VERSION ""

NS_ :

BS_:

BU_: PowertrainControlModule AtmosphericSensor SafetyRestraintSystem2 Aftertreatment_2_GasOutlet Aftertreatment_2_GasIntake DieselParticulateFilterControl Turbocharger SafetyRestraintSystem1 CabDisplay2 Aftertreatment_1_GasOutlet Aftertreatment_1_GasIntake OnBoardDataLogger OffBoardDiagnosticTool2 OffBoardDiagnosticTool1 FileServer ParkingBrakeController SeatController2 FanDriveController SteeringColumnUnit CommunicationUnitRadio CommunicationUnitSatellite CommunicationUnitCellular PropulsionBatteryCharger ChassisController2 ChassisController1 EngineValveControl AuxiliaryHeater2 AuxiliaryHeater1 ClutchUnit RampControl InformationSystem1 SuspensionSystemController2 OilSensor VehicleDynamicStability ExhaustEmissionController TransmissionDisplay2 TransmissionDisplay1 ClimateControl2 WaterPumpController RearAxleSteeringController LightingOperatorControl SeatController1 IgnitionController2 IgnitionController1 TirePressureController CabController2 CabController1 PneumaticSystemController SuspensionSystemController1 HydraulicPumpController EnduranceBrakingSystem RetarderExhaustEngine2 OnBoardDiagnosticUnit HeadwayController RetarderExhaustEngine1 CabDisplay1 ManagementComputer VirtualTerminal OffVehicleGateway PowerTakeOffFront HitchControl AuxiliaryValveControl BodyController TractorTrailerBridge1 StarterSystem ElectricalSystem VehicleSecurity VehicleNavigation AerodynamicControl ElectricalChargingSystem ClimateControl1 TripRecorder InstrumentCluster SuspensionDriveAxle2 SuspensionDriveAxle1 SuspensionSteerAxle SteeringController FuelSystem CruiseControl RetarderDriveline RetarderEngine BrakesDriveAxle2 BrakesDriveAxle1 BrakesSystemController BrakesSteerAxle AxleDrive2 AxleDrive1 AxleSteering PowerTakeOff ShiftConsoleSecondary ShiftConsolePrimary Transmission2 Transmission1 Engine2 Engine1

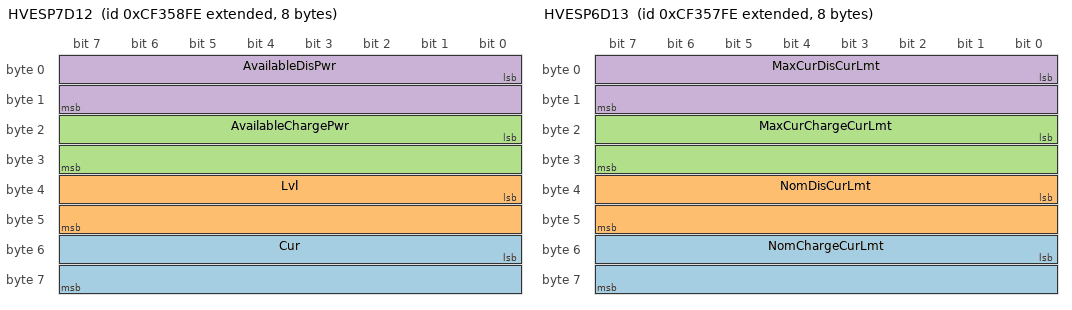
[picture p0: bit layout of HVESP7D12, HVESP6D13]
BO_ 2364758270 HVESP7D12: 8 Vector__XXX
 SG_ Cur : 48|16@1+ (0.125,-4000) [-4000|4031.875] "A" Vector__XXX
 SG_ Lvl : 32|16@1+ (0.125,0) [0|8031.875] "V" Vector__XXX
 SG_ AvailableChargePwr : 16|16@1+ (0.25,0) [0|16063.75] "kW" Vector__XXX
 SG_ AvailableDisPwr : 0|16@1+ (0.25,0) [0|16063.75] "kW" Vector__XXX

BO_ 2364758014 HVESP6D13: 8 Vector__XXX
 SG_ NomChargeCurLmt : 48|16@1+ (0.125,-4000) [0|4031.875] "A" Vector__XXX
 SG_ NomDisCurLmt : 32|16@1+ (0.125,-4000) [-4000|0] "A" Vector__XXX
 SG_ MaxCurChargeCurLmt : 16|16@1+ (0.125,-4000) [0|4031.875] "A" Vector__XXX
 SG_ MaxCurDisCurLmt : 0|16@1+ (0.125,-4000) [-4000|0] "A" Vector__XXX

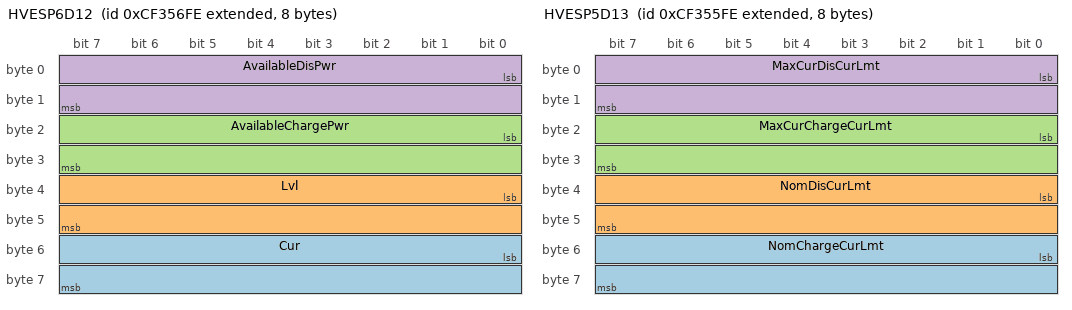
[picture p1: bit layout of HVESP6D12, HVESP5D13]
BO_ 2364757758 HVESP6D12: 8 Vector__XXX
 SG_ Cur : 48|16@1+ (0.125,-4000) [-4000|4031.875] "A" Vector__XXX
 SG_ Lvl : 32|16@1+ (0.125,0) [0|8031.875] "V" Vector__XXX
 SG_ AvailableChargePwr : 16|16@1+ (0.25,0) [0|16063.75] "kW" Vector__XXX
 SG_ AvailableDisPwr : 0|16@1+ (0.25,0) [0|16063.75] "kW" Vector__XXX

BO_ 2364757502 HVESP5D13: 8 Vector__XXX
 SG_ NomChargeCurLmt : 48|16@1+ (0.125,-4000) [0|4031.875] "A" Vector__XXX
 SG_ NomDisCurLmt : 32|16@1+ (0.125,-4000) [-4000|0] "A" Vector__XXX
 SG_ MaxCurChargeCurLmt : 16|16@1+ (0.125,-4000) [0|4031.875] "A" Vector__XXX
 SG_ MaxCurDisCurLmt : 0|16@1+ (0.125,-4000) [-4000|0] "A" Vector__XXX

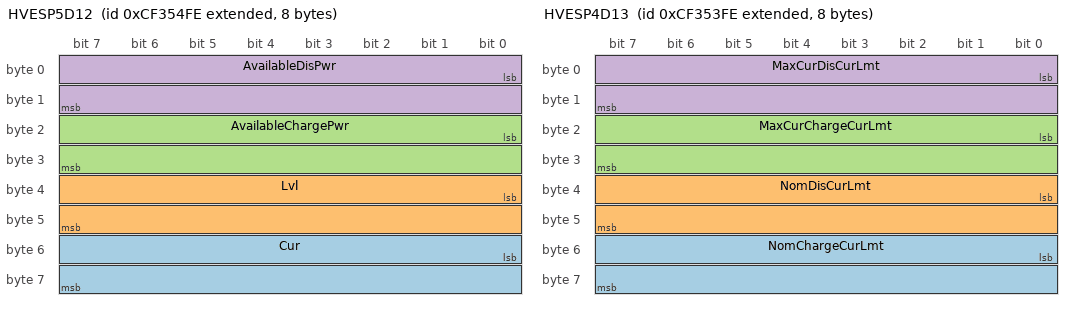
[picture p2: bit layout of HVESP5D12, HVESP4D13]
BO_ 2364757246 HVESP5D12: 8 Vector__XXX
 SG_ Cur : 48|16@1+ (0.125,-4000) [-4000|4031.875] "A" Vector__XXX
 SG_ Lvl : 32|16@1+ (0.125,0) [0|8031.875] "V" Vector__XXX
 SG_ AvailableChargePwr : 16|16@1+ (0.25,0) [0|16063.75] "kW" Vector__XXX
 SG_ AvailableDisPwr : 0|16@1+ (0.25,0) [0|16063.75] "kW" Vector__XXX

BO_ 2364756990 HVESP4D13: 8 Vector__XXX
 SG_ NomChargeCurLmt : 48|16@1+ (0.125,-4000) [0|4031.875] "A" Vector__XXX
 SG_ NomDisCurLmt : 32|16@1+ (0.125,-4000) [-4000|0] "A" Vector__XXX
 SG_ MaxCurChargeCurLmt : 16|16@1+ (0.125,-4000) [0|4031.875] "A" Vector__XXX
 SG_ MaxCurDisCurLmt : 0|16@1+ (0.125,-4000) [-4000|0] "A" Vector__XXX

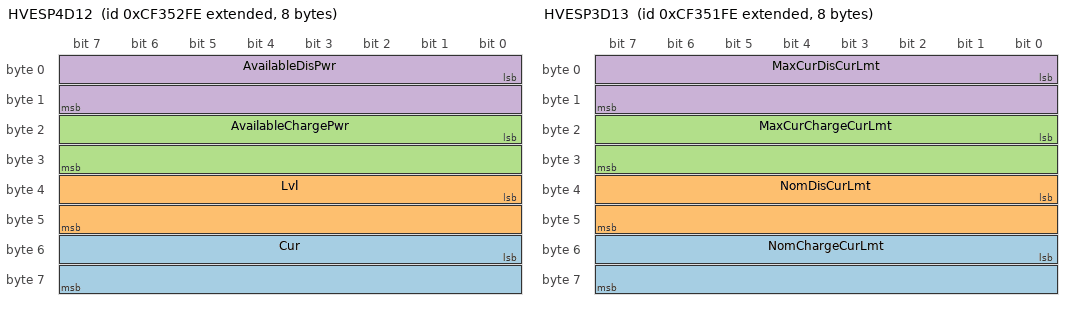
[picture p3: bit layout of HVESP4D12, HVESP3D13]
BO_ 2364756734 HVESP4D12: 8 Vector__XXX
 SG_ Cur : 48|16@1+ (0.125,-4000) [-4000|4031.875] "A" Vector__XXX
 SG_ Lvl : 32|16@1+ (0.125,0) [0|8031.875] "V" Vector__XXX
 SG_ AvailableChargePwr : 16|16@1+ (0.25,0) [0|16063.75] "kW" Vector__XXX
 SG_ AvailableDisPwr : 0|16@1+ (0.25,0) [0|16063.75] "kW" Vector__XXX

BO_ 2364756478 HVESP3D13: 8 Vector__XXX
 SG_ NomChargeCurLmt : 48|16@1+ (0.125,-4000) [0|4031.875] "A" Vector__XXX
 SG_ NomDisCurLmt : 32|16@1+ (0.125,-4000) [-4000|0] "A" Vector__XXX
 SG_ MaxCurChargeCurLmt : 16|16@1+ (0.125,-4000) [0|4031.875] "A" Vector__XXX
 SG_ MaxCurDisCurLmt : 0|16@1+ (0.125,-4000) [-4000|0] "A" Vector__XXX

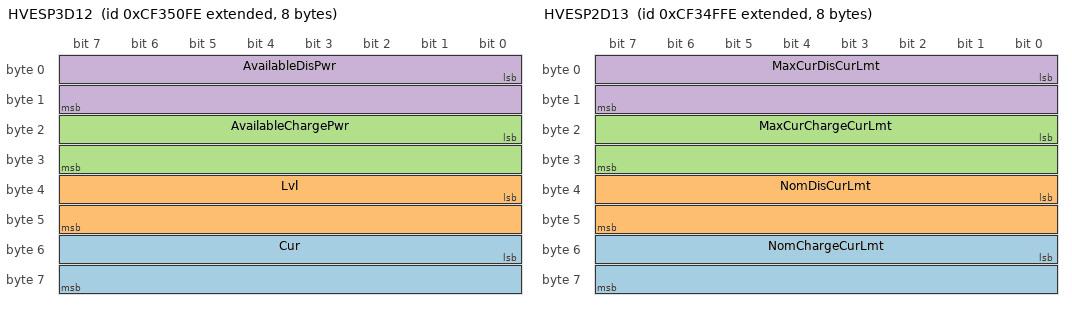
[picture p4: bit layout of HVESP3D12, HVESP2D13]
BO_ 2364756222 HVESP3D12: 8 Vector__XXX
 SG_ Cur : 48|16@1+ (0.125,-4000) [-4000|4031.875] "A" Vector__XXX
 SG_ Lvl : 32|16@1+ (0.125,0) [0|8031.875] "V" Vector__XXX
 SG_ AvailableChargePwr : 16|16@1+ (0.25,0) [0|16063.75] "kW" Vector__XXX
 SG_ AvailableDisPwr : 0|16@1+ (0.25,0) [0|16063.75] "kW" Vector__XXX

BO_ 2364755966 HVESP2D13: 8 Vector__XXX
 SG_ NomChargeCurLmt : 48|16@1+ (0.125,-4000) [0|4031.875] "A" Vector__XXX
 SG_ NomDisCurLmt : 32|16@1+ (0.125,-4000) [-4000|0] "A" Vector__XXX
 SG_ MaxCurChargeCurLmt : 16|16@1+ (0.125,-4000) [0|4031.875] "A" Vector__XXX
 SG_ MaxCurDisCurLmt : 0|16@1+ (0.125,-4000) [-4000|0] "A" Vector__XXX

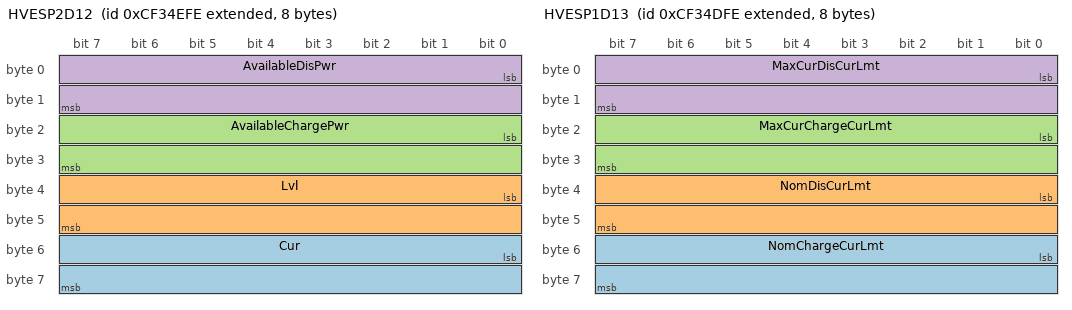
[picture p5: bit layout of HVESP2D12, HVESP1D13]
BO_ 2364755710 HVESP2D12: 8 Vector__XXX
 SG_ Cur : 48|16@1+ (0.125,-4000) [-4000|4031.875] "A" Vector__XXX
 SG_ Lvl : 32|16@1+ (0.125,0) [0|8031.875] "V" Vector__XXX
 SG_ AvailableChargePwr : 16|16@1+ (0.25,0) [0|16063.75] "kW" Vector__XXX
 SG_ AvailableDisPwr : 0|16@1+ (0.25,0) [0|16063.75] "kW" Vector__XXX

BO_ 2364755454 HVESP1D13: 8 Vector__XXX
 SG_ NomChargeCurLmt : 48|16@1+ (0.125,-4000) [0|4031.875] "A" Vector__XXX
 SG_ NomDisCurLmt : 32|16@1+ (0.125,-4000) [-4000|0] "A" Vector__XXX
 SG_ MaxCurChargeCurLmt : 16|16@1+ (0.125,-4000) [0|4031.875] "A" Vector__XXX
 SG_ MaxCurDisCurLmt : 0|16@1+ (0.125,-4000) [-4000|0] "A" Vector__XXX

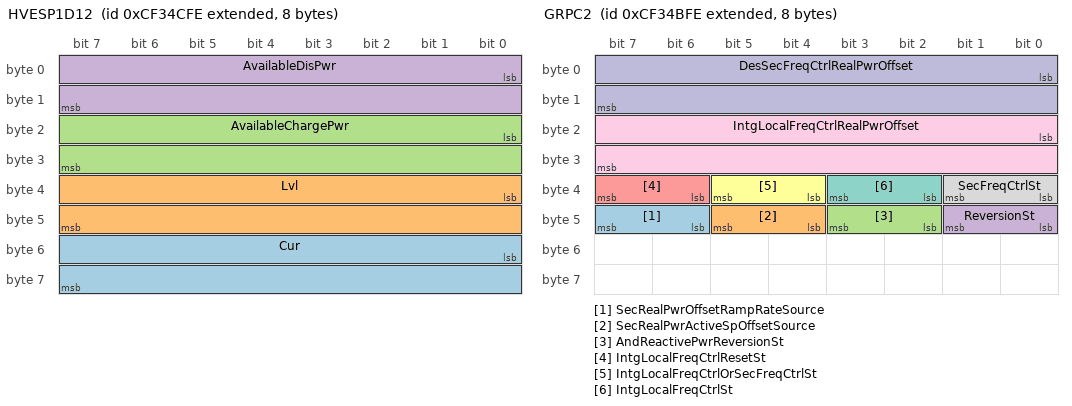
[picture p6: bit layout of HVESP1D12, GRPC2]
BO_ 2364755198 HVESP1D12: 8 Vector__XXX
 SG_ Cur : 48|16@1+ (0.125,-4000) [-4000|4031.875] "A" Vector__XXX
 SG_ Lvl : 32|16@1+ (0.125,0) [0|8031.875] "V" Vector__XXX
 SG_ AvailableChargePwr : 16|16@1+ (0.25,0) [0|16063.75] "kW" Vector__XXX
 SG_ AvailableDisPwr : 0|16@1+ (0.25,0) [0|16063.75] "kW" Vector__XXX

BO_ 2364754942 GRPC2: 8 Vector__XXX
 SG_ SecRealPwrOffsetRampRateSource : 46|2@1+ (1,0) [0|3] "" Vector__XXX
 SG_ SecRealPwrActiveSpOffsetSource : 44|2@1+ (1,0) [0|3] "" Vector__XXX
 SG_ AndReactivePwrReversionSt : 42|2@1+ (1,0) [0|3] "" Vector__XXX
 SG_ ReversionSt : 40|2@1+ (1,0) [0|3] "" Vector__XXX
 SG_ IntgLocalFreqCtrlResetSt : 38|2@1+ (1,0) [0|3] "" Vector__XXX
 SG_ IntgLocalFreqCtrlOrSecFreqCtrlSt : 36|2@1+ (1,0) [0|3] "" Vector__XXX
 SG_ IntgLocalFreqCtrlSt : 34|2@1+ (1,0) [0|3] "" Vector__XXX
 SG_ SecFreqCtrlSt : 32|2@1+ (1,0) [0|3] "" Vector__XXX
 SG_ IntgLocalFreqCtrlRealPwrOffset : 16|16@1+ (0.01,-321.27) [-321.27|321.28] "%" Vector__XXX
 SG_ DesSecFreqCtrlRealPwrOffset : 0|16@1+ (0.01,-321.27) [-321.27|321.28] "%" Vector__XXX

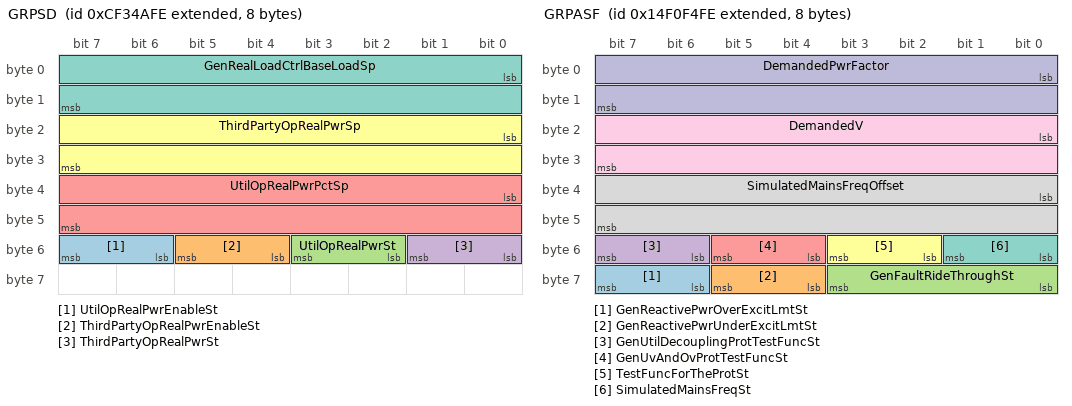
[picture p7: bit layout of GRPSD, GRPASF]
BO_ 2364754686 GRPSD: 8 Vector__XXX
 SG_ UtilOpRealPwrEnableSt : 54|2@1+ (1,0) [0|3] "" Vector__XXX
 SG_ ThirdPartyOpRealPwrEnableSt : 52|2@1+ (1,0) [0|3] "" Vector__XXX
 SG_ UtilOpRealPwrSt : 50|2@1+ (1,0) [0|3] "" Vector__XXX
 SG_ ThirdPartyOpRealPwrSt : 48|2@1+ (1,0) [0|3] "" Vector__XXX
 SG_ UtilOpRealPwrPctSp : 32|16@1+ (0.01,-321.27) [-321.27|321.28] "%" Vector__XXX
 SG_ ThirdPartyOpRealPwrSp : 16|16@1+ (0.01,-321.27) [-321.27|321.28] "%" Vector__XXX
 SG_ GenRealLoadCtrlBaseLoadSp : 0|16@1+ (0.01,-321.27) [-321.27|321.28] "%" Vector__XXX

BO_ 2498819326 GRPASF: 8 Vector__XXX
 SG_ GenReactivePwrOverExcitLmtSt : 62|2@1+ (1,0) [0|3] "" Vector__XXX
 SG_ GenReactivePwrUnderExcitLmtSt : 60|2@1+ (1,0) [0|3] "" Vector__XXX
 SG_ GenFaultRideThroughSt : 56|4@1+ (1,0) [0|15] "" Vector__XXX
 SG_ GenUtilDecouplingProtTestFuncSt : 54|2@1+ (1,0) [0|3] "" Vector__XXX
 SG_ GenUvAndOvProtTestFuncSt : 52|2@1+ (1,0) [0|3] "" Vector__XXX
 SG_ TestFuncForTheProtSt : 50|2@1+ (1,0) [0|3] "" Vector__XXX
 SG_ SimulatedMainsFreqSt : 48|2@1+ (1,0) [0|3] "" Vector__XXX
 SG_ SimulatedMainsFreqOffset : 32|16@1+ (0.0078125,0) [0|501.9921875] "Hz" Vector__XXX
 SG_ DemandedV : 16|16@1+ (0.01,-321.28) [-321.28|321.27] "V" Vector__XXX
 SG_ DemandedPwrFactor : 0|16@1+ (6.103515625E-005,-1) [-1|2.92181396484375] "" Vector__XXX

BO_ 2565918718 ETWAI2: 8 Vector__XXX
 SG_ FourOpSt : 4|4@1+ (1,0) [0|15] "" Vector__XXX
 SG_ ThreeOpSt : 0|4@1+ (1,0) [0|15] "" Vector__XXX

BO_ 2565918462 ETCC4: 8 Vector__XXX
 SG_ WastegateAct4Cmd : 16|16@1+ (0.0025,0) [0|160.6375] "%" Vector__XXX
 SG_ WastegateAct3Cmd : 0|16@1+ (0.0025,0) [0|160.6375] "%" Vector__XXX

BO_ 2565905662 MG6ITPS: 8 Vector__XXX
 SG_ CapLmt : 8|8@1+ (0.4,0) [0|100] "%" Vector__XXX
 SG_ CapUsed : 0|8@1+ (0.4,0) [0|100] "%" Vector__XXX

BO_ 2565905406 MG5ITPS: 8 Vector__XXX
 SG_ CapLmt : 8|8@1+ (0.4,0) [0|100] "%" Vector__XXX
 SG_ CapUsed : 0|8@1+ (0.4,0) [0|100] "%" Vector__XXX

BO_ 2565905150 MG4ITPS: 8 Vector__XXX
 SG_ CapLmt : 8|8@1+ (0.4,0) [0|100] "%" Vector__XXX
 SG_ CapUsed : 0|8@1+ (0.4,0) [0|100] "%" Vector__XXX

BO_ 2565904894 MG3ITPS: 8 Vector__XXX
 SG_ CapLmt : 8|8@1+ (0.4,0) [0|100] "%" Vector__XXX
 SG_ CapUsed : 0|8@1+ (0.4,0) [0|100] "%" Vector__XXX

BO_ 2565904638 MG2ITPS: 8 Vector__XXX
 SG_ CapLmt : 8|8@1+ (0.4,0) [0|100] "%" Vector__XXX
 SG_ CapUsed : 0|8@1+ (0.4,0) [0|100] "%" Vector__XXX

BO_ 2565904382 MG1ITPS: 8 Vector__XXX
 SG_ CapLmt : 8|8@1+ (0.4,0) [0|100] "%" Vector__XXX
 SG_ CapUsed : 0|8@1+ (0.4,0) [0|100] "%" Vector__XXX

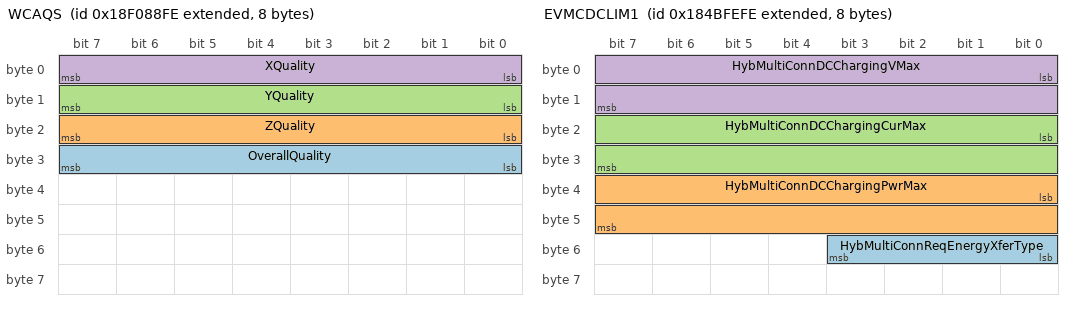
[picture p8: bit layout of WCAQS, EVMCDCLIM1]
BO_ 2565900542 WCAQS: 8 Vector__XXX
 SG_ OverallQuality : 24|8@1+ (0.4,0) [0|100] "%" Vector__XXX
 SG_ ZQuality : 16|8@1+ (0.8,-100) [-100|100] "%" Vector__XXX
 SG_ YQuality : 8|8@1+ (0.8,-100) [-100|100] "%" Vector__XXX
 SG_ XQuality : 0|8@1+ (0.8,-100) [-100|100] "%" Vector__XXX

BO_ 2555117310 EVMCDCLIM1: 8 Vector__XXX
 SG_ HybMultiConnReqEnergyXferType : 48|4@1+ (1,0) [0|15] "" Vector__XXX
 SG_ HybMultiConnDCChargingPwrMax : 32|16@1+ (0.05,0) [0|3212.75] "kW" Vector__XXX
 SG_ HybMultiConnDCChargingCurMax : 16|16@1+ (0.0625,0) [0|4015.9375] "A" Vector__XXX
 SG_ HybMultiConnDCChargingVMax : 0|16@1+ (0.05,0) [0|3212.75] "V" Vector__XXX

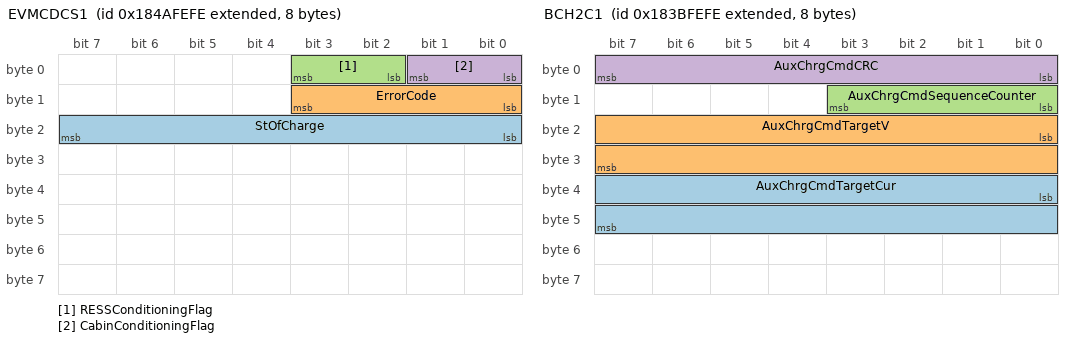
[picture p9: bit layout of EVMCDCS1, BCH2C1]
BO_ 2555051774 EVMCDCS1: 8 Vector__XXX
 SG_ StOfCharge : 16|8@1+ (0.5,0) [0|125] "%" Vector__XXX
 SG_ ErrorCode : 8|4@1+ (1,0) [0|15] "" Vector__XXX
 SG_ RESSConditioningFlag : 2|2@1+ (1,0) [0|3] "" Vector__XXX
 SG_ CabinConditioningFlag : 0|2@1+ (1,0) [0|3] "" Vector__XXX

BO_ 2554068734 BCH2C1: 8 Vector__XXX
 SG_ AuxChrgCmdTargetCur : 32|16@1+ (0.0625,0) [0|4015.9375] "A" Vector__XXX
 SG_ AuxChrgCmdTargetV : 16|16@1+ (0.05,0) [0|3212.75] "V" Vector__XXX
 SG_ AuxChrgCmdSequenceCounter : 8|4@1+ (1,0) [0|15] "" Vector__XXX
 SG_ AuxChrgCmdCRC : 0|8@1+ (1,0) [0|255] "" Vector__XXX

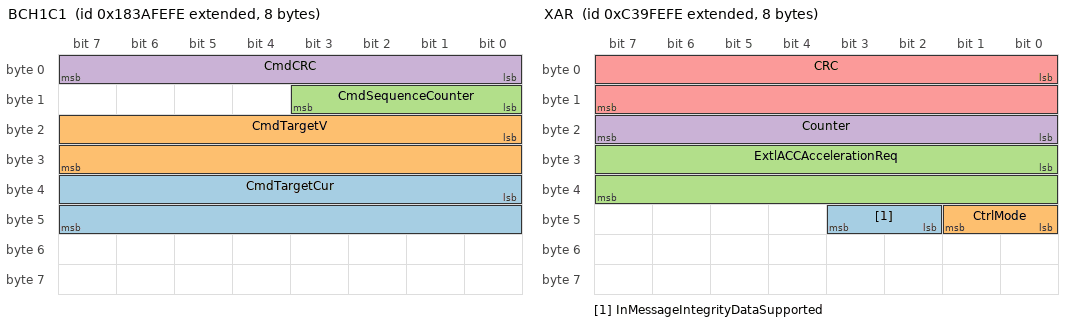
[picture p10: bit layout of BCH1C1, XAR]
BO_ 2554003198 BCH1C1: 8 Vector__XXX
 SG_ CmdTargetCur : 32|16@1+ (0.0625,0) [0|4015.9375] "A" Vector__XXX
 SG_ CmdTargetV : 16|16@1+ (0.05,0) [0|3212.75] "V" Vector__XXX
 SG_ CmdSequenceCounter : 8|4@1+ (1,0) [0|15] "" Vector__XXX
 SG_ CmdCRC : 0|8@1+ (1,0) [0|255] "" Vector__XXX

BO_ 2352611070 XAR: 8 Vector__XXX
 SG_ InMessageIntegrityDataSupported : 42|2@1+ (1,0) [0|3] "" Vector__XXX
 SG_ CtrlMode : 40|2@1+ (1,0) [0|3] "" Vector__XXX
 SG_ ExtlACCAccelerationReq : 24|16@1+ (0.00048828125,-15.6865234375) [-15.6865234375|15.68798828125] "m/s²" Vector__XXX
 SG_ Counter : 16|8@1+ (1,0) [0|255] "" Vector__XXX
 SG_ CRC : 0|16@1+ (1,0) [0|65535] "" Vector__XXX

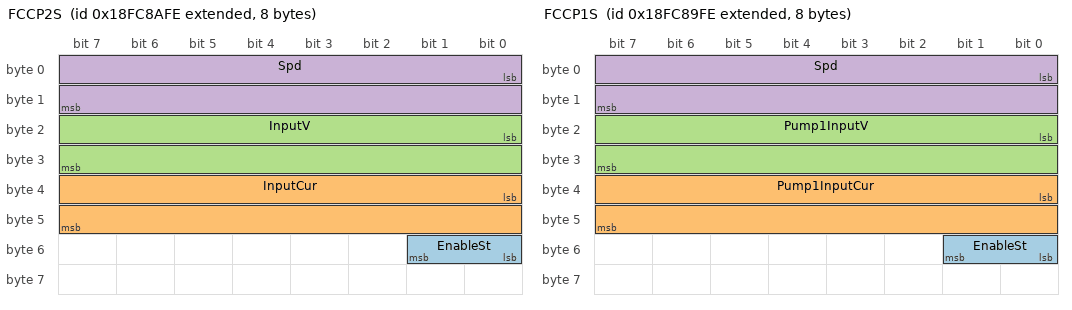
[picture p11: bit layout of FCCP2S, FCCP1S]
BO_ 2566687486 FCCP2S: 8 Vector__XXX
 SG_ EnableSt : 48|2@1+ (1,0) [0|3] "" Vector__XXX
 SG_ InputCur : 32|16@1+ (0.001,0) [0|64.255] "A" Vector__XXX
 SG_ InputV : 16|16@1+ (1,0) [0|64255] "V" Vector__XXX
 SG_ Spd : 0|16@1+ (0.5,0) [0|32127.5] "rpm" Vector__XXX

BO_ 2566687230 FCCP1S: 8 Vector__XXX
 SG_ EnableSt : 48|2@1+ (1,0) [0|3] "" Vector__XXX
 SG_ Pump1InputCur : 32|16@1+ (0.001,0) [0|64.255] "A" Vector__XXX
 SG_ Pump1InputV : 16|16@1+ (1,0) [0|64255] "V" Vector__XXX
 SG_ Spd : 0|16@1+ (0.5,0) [0|32127.5] "rpm" Vector__XXX

BO_ 2566686974 FCCP2C: 8 Vector__XXX
 SG_ EnableCmd : 24|2@1+ (1,0) [0|3] "" Vector__XXX
 SG_ PercentSpdCmd : 16|8@1+ (0.5,0) [0|125] "%" Vector__XXX
 SG_ SpdCmd : 0|16@1+ (0.5,0) [0|32127.5] "rpm" Vector__XXX

BO_ 2566686718 FCCP1C: 8 Vector__XXX
 SG_ EnableCmd : 24|2@1+ (1,0) [0|3] "" Vector__XXX
 SG_ PercentSpdCmd : 16|8@1+ (0.5,0) [0|125] "%" Vector__XXX
 SG_ SpdCmd : 0|16@1+ (0.5,0) [0|32127.5] "rpm" Vector__XXX

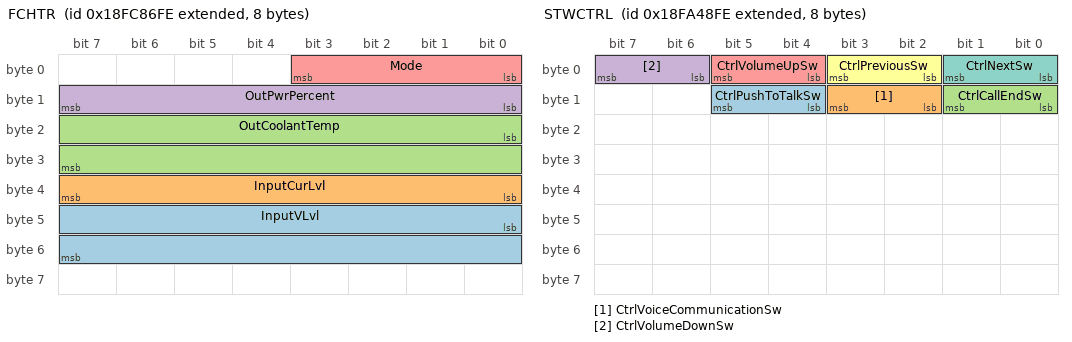
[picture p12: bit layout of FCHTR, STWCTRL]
BO_ 2566686462 FCHTR: 8 Vector__XXX
 SG_ InputVLvl : 40|16@1+ (1,0) [0|64255] "V" Vector__XXX
 SG_ InputCurLvl : 32|8@1+ (0.25,0) [0|62.5] "A" Vector__XXX
 SG_ OutCoolantTemp : 16|16@1+ (0.0078125,-273) [-273|228.9921875] "°C" Vector__XXX
 SG_ OutPwrPercent : 8|8@1+ (0.4,0) [0|100] "%" Vector__XXX
 SG_ Mode : 0|4@1+ (1,0) [0|15] "" Vector__XXX

BO_ 2566686206 FCHTRC: 8 Vector__XXX
 SG_ OutCoolantTempSp : 16|16@1+ (0.0078125,-273) [-273|228.9921875] "°C" Vector__XXX
 SG_ PwrPercentCmd : 8|8@1+ (0.4,0) [0|100] "%" Vector__XXX
 SG_ ModeReq : 0|4@1+ (1,0) [0|15] "" Vector__XXX

BO_ 2566675710 SSCTI: 8 Vector__XXX
 SG_ Component3Identifier : 8|8@1+ (1,0) [0|250] "ID" Vector__XXX
 SG_ SyncSvcDelay_CalendarTime : 0|8@1+ (1,-125) [-125|125] "week" Vector__XXX

BO_ 2566675454 SSOTI: 8 Vector__XXX
 SG_ Component2Identifier : 0|8@1+ (1,0) [0|250] "ID" Vector__XXX
 SG_ SyncSvcDelay_OperationalTime : 65528|16@1+ (1,-32127) [-32127|32128] "h" Vector__XXX

BO_ 2566675198 SSDI: 8 Vector__XXX
 SG_ Component1Identifier : 0|8@1+ (1,0) [0|250] "ID" Vector__XXX
 SG_ SyncSvcDist : 65528|16@1+ (5,-160635) [-160635|160640] "km" Vector__XXX

BO_ 2566539774 PA: 8 Vector__XXX
 SG_ RearParkAssistSt : 3|3@1+ (1,0) [0|7] "" Vector__XXX
 SG_ FrontParkAssistSt : 0|3@1+ (1,0) [0|7] "" Vector__XXX

BO_ 2566539518 STWCTRL: 8 Vector__XXX
 SG_ CtrlPushToTalkSw : 12|2@1+ (1,0) [0|3] "" Vector__XXX
 SG_ CtrlVoiceCommunicationSw : 10|2@1+ (1,0) [0|3] "" Vector__XXX
 SG_ CtrlCallEndSw : 8|2@1+ (1,0) [0|3] "" Vector__XXX
 SG_ CtrlVolumeDownSw : 6|2@1+ (1,0) [0|3] "" Vector__XXX
 SG_ CtrlVolumeUpSw : 4|2@1+ (1,0) [0|3] "" Vector__XXX
 SG_ CtrlPreviousSw : 2|2@1+ (1,0) [0|3] "" Vector__XXX
 SG_ CtrlNextSw : 0|2@1+ (1,0) [0|3] "" Vector__XXX

BO_ 2566539262 EFASM: 8 Vector__XXX
 SG_ TwoSvcModeReq : 2|2@1+ (1,0) [0|3] "" Vector__XXX
 SG_ OneSvcModeReq : 0|2@1+ (1,0) [0|3] "" Vector__XXX

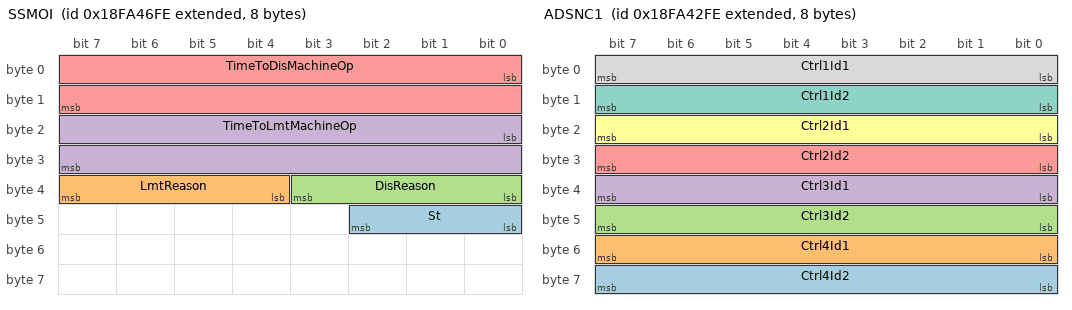
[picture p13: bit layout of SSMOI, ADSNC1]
BO_ 2566539006 SSMOI: 8 Vector__XXX
 SG_ St : 40|3@1+ (1,0) [0|7] "" Vector__XXX
 SG_ LmtReason : 36|4@1+ (1,0) [0|15] "" Vector__XXX
 SG_ DisReason : 32|4@1+ (1,0) [0|15] "" Vector__XXX
 SG_ TimeToLmtMachineOp : 16|16@1+ (1,0) [0|64255] "min" Vector__XXX
 SG_ TimeToDisMachineOp : 0|16@1+ (1,0) [0|64255] "min" Vector__XXX

BO_ 2365212158 GTRACE2: 8 Vector__XXX
 SG_ KVArHoursImport : 0|32@1+ (1,0) [0|4211081215] "kVArh" Vector__XXX

BO_ 2566538494 LF2: 8 Vector__XXX
 SG_ TotalAvgLoadFactor : 8|8@1+ (0.4,0) [0|100] "%" Vector__XXX
 SG_ TripAvgLoadFactor : 0|8@1+ (0.4,0) [0|100] "%" Vector__XXX

BO_ 2499429374 HSI2: 8 Vector__XXX
 SG_ TotalRegenerativeBrakingLvl : 16|8@1+ (0.4,0) [0|100] "%" Vector__XXX

BO_ 2566537982 ADSNC1: 8 Vector__XXX
 SG_ Ctrl4Id2 : 56|8@1+ (1,0) [0|255] "" Vector__XXX
 SG_ Ctrl4Id1 : 48|8@1+ (1,0) [0|255] "" Vector__XXX
 SG_ Ctrl3Id2 : 40|8@1+ (1,0) [0|255] "" Vector__XXX
 SG_ Ctrl3Id1 : 32|8@1+ (1,0) [0|255] "" Vector__XXX
 SG_ Ctrl2Id2 : 24|8@1+ (1,0) [0|255] "" Vector__XXX
 SG_ Ctrl2Id1 : 16|8@1+ (1,0) [0|255] "" Vector__XXX
 SG_ Ctrl1Id2 : 8|8@1+ (1,0) [0|255] "" Vector__XXX
 SG_ Ctrl1Id1 : 0|8@1+ (1,0) [0|255] "" Vector__XXX

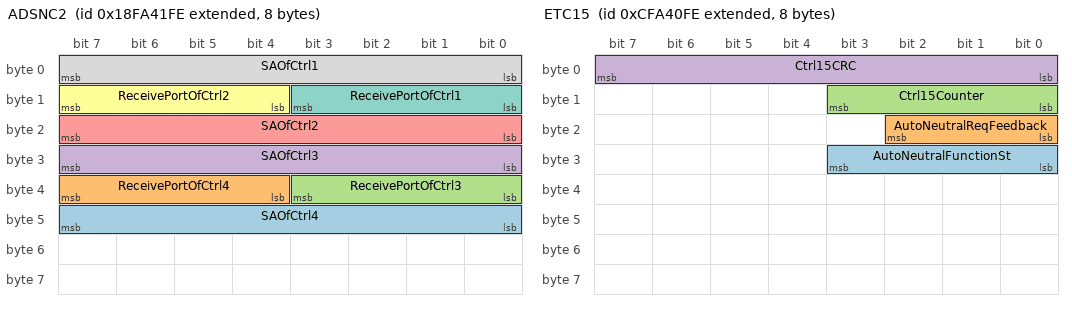
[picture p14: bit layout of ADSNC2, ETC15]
BO_ 2566537726 ADSNC2: 8 Vector__XXX
 SG_ SAOfCtrl4 : 40|8@1+ (1,0) [0|255] "" Vector__XXX
 SG_ ReceivePortOfCtrl4 : 36|4@1+ (1,0) [0|15] "" Vector__XXX
 SG_ ReceivePortOfCtrl3 : 32|4@1+ (1,0) [0|15] "" Vector__XXX
 SG_ SAOfCtrl3 : 24|8@1+ (1,0) [0|255] "" Vector__XXX
 SG_ SAOfCtrl2 : 16|8@1+ (1,0) [0|255] "" Vector__XXX
 SG_ ReceivePortOfCtrl2 : 12|4@1+ (1,0) [0|15] "" Vector__XXX
 SG_ ReceivePortOfCtrl1 : 8|4@1+ (1,0) [0|15] "" Vector__XXX
 SG_ SAOfCtrl1 : 0|8@1+ (1,0) [0|255] "" Vector__XXX

BO_ 2365210878 ETC15: 8 Vector__XXX
 SG_ AutoNeutralFunctionSt : 24|4@1+ (1,0) [0|15] "" Vector__XXX
 SG_ AutoNeutralReqFeedback : 16|3@1+ (1,0) [0|7] "" Vector__XXX
 SG_ Ctrl15Counter : 8|4@1+ (1,0) [0|15] "" Vector__XXX
 SG_ Ctrl15CRC : 0|8@1+ (1,0) [0|255] "" Vector__XXX

BO_ 2566081022 FCCI: 8 Vector__XXX
 SG_ HydrogenConcentration : 16|8@1+ (500,0) [0|125000] "ppm" Vector__XXX
 SG_ Enclosure2HydrogenConcentration : 8|8@1+ (500,0) [0|125000] "ppm" Vector__XXX
 SG_ Enclosure1HydrogenConcentration : 0|8@1+ (500,0) [0|125000] "ppm" Vector__XXX

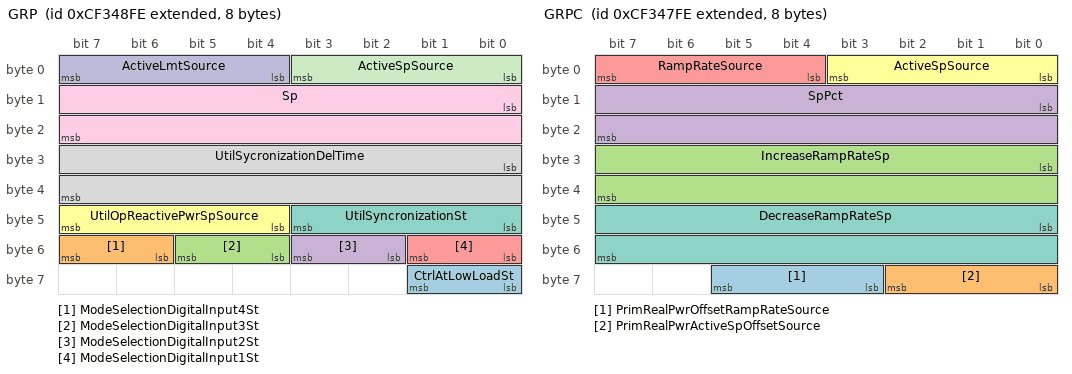
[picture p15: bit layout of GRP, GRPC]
BO_ 2364754174 GRP: 8 Vector__XXX
 SG_ CtrlAtLowLoadSt : 56|2@1+ (1,0) [0|3] "" Vector__XXX
 SG_ ModeSelectionDigitalInput4St : 54|2@1+ (1,0) [0|3] "" Vector__XXX
 SG_ ModeSelectionDigitalInput3St : 52|2@1+ (1,0) [0|3] "" Vector__XXX
 SG_ ModeSelectionDigitalInput2St : 50|2@1+ (1,0) [0|3] "" Vector__XXX
 SG_ ModeSelectionDigitalInput1St : 48|2@1+ (1,0) [0|3] "" Vector__XXX
 SG_ UtilOpReactivePwrSpSource : 44|4@1+ (1,0) [0|15] "" Vector__XXX
 SG_ UtilSyncronizationSt : 40|4@1+ (1,0) [0|15] "" Vector__XXX
 SG_ UtilSycronizationDelTime : 24|16@1+ (1,0) [0|64255] "s" Vector__XXX
 SG_ Sp : 8|16@1+ (0.01,-321.27) [-321.27|321.28] "%" Vector__XXX
 SG_ ActiveLmtSource : 4|4@1+ (1,0) [0|15] "" Vector__XXX
 SG_ ActiveSpSource : 0|4@1+ (1,0) [0|15] "" Vector__XXX

BO_ 2364753918 GRPC: 8 Vector__XXX
 SG_ PrimRealPwrOffsetRampRateSource : 59|3@1+ (1,0) [0|7] "" Vector__XXX
 SG_ PrimRealPwrActiveSpOffsetSource : 56|3@1+ (1,0) [0|7] "" Vector__XXX
 SG_ IncreaseRampRateSp : 24|16@1+ (0.01,0) [0|642.55] "%/s" Vector__XXX
 SG_ SpPct : 8|16@1+ (0.01,-321.27) [-321.27|321.28] "%" Vector__XXX
 SG_ RampRateSource : 4|4@1+ (1,0) [0|15] "" Vector__XXX
 SG_ ActiveSpSource : 0|4@1+ (1,0) [0|15] "" Vector__XXX
 SG_ DecreaseRampRateSp : 40|16@1+ (0.01,0) [0|642.55] "%/s" Vector__XXX

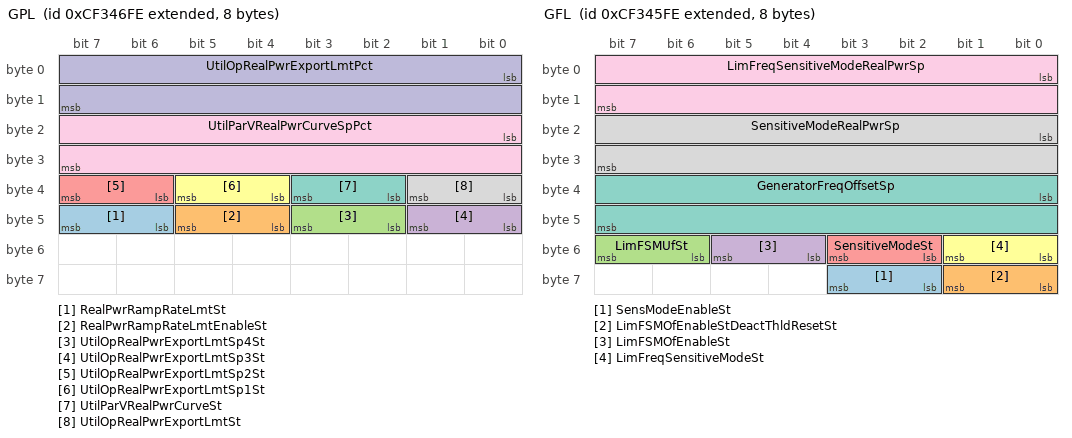
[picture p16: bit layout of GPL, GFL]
BO_ 2364753662 GPL: 8 Vector__XXX
 SG_ RealPwrRampRateLmtSt : 46|2@1+ (1,0) [0|3] "" Vector__XXX
 SG_ RealPwrRampRateLmtEnableSt : 44|2@1+ (1,0) [0|3] "" Vector__XXX
 SG_ UtilOpRealPwrExportLmtSp4St : 42|2@1+ (1,0) [0|3] "" Vector__XXX
 SG_ UtilOpRealPwrExportLmtSp3St : 40|2@1+ (1,0) [0|3] "" Vector__XXX
 SG_ UtilOpRealPwrExportLmtSp2St : 38|2@1+ (1,0) [0|3] "" Vector__XXX
 SG_ UtilOpRealPwrExportLmtSp1St : 36|2@1+ (1,0) [0|3] "" Vector__XXX
 SG_ UtilParVRealPwrCurveSt : 34|2@1+ (1,0) [0|3] "" Vector__XXX
 SG_ UtilOpRealPwrExportLmtSt : 32|2@1+ (1,0) [0|3] "" Vector__XXX
 SG_ UtilParVRealPwrCurveSpPct : 16|16@1+ (0.01,-321.27) [-321.27|321.28] "%" Vector__XXX
 SG_ UtilOpRealPwrExportLmtPct : 0|16@1+ (0.01,-321.27) [-321.27|321.28] "%" Vector__XXX

BO_ 2364753406 GFL: 8 Vector__XXX
 SG_ SensModeEnableSt : 58|2@1+ (1,0) [0|3] "" Vector__XXX
 SG_ LimFSMOfEnableStDeactThldResetSt : 56|2@1+ (1,0) [0|3] "" Vector__XXX
 SG_ LimFSMUfSt : 54|2@1+ (1,0) [0|3] "" Vector__XXX
 SG_ LimFSMOfEnableSt : 52|2@1+ (1,0) [0|3] "" Vector__XXX
 SG_ SensitiveModeSt : 50|2@1+ (1,0) [0|3] "" Vector__XXX
 SG_ LimFreqSensitiveModeSt : 48|2@1+ (1,0) [0|3] "" Vector__XXX
 SG_ GeneratorFreqOffsetSp : 32|16@1+ (0.0078125,0) [0|501.9921875] "Hz" Vector__XXX
 SG_ SensitiveModeRealPwrSp : 16|16@1+ (0.01,-321.27) [-321.27|321.28] "%" Vector__XXX
 SG_ LimFreqSensitiveModeRealPwrSp : 0|16@1+ (0.01,-321.27) [-321.27|321.28] "%" Vector__XXX

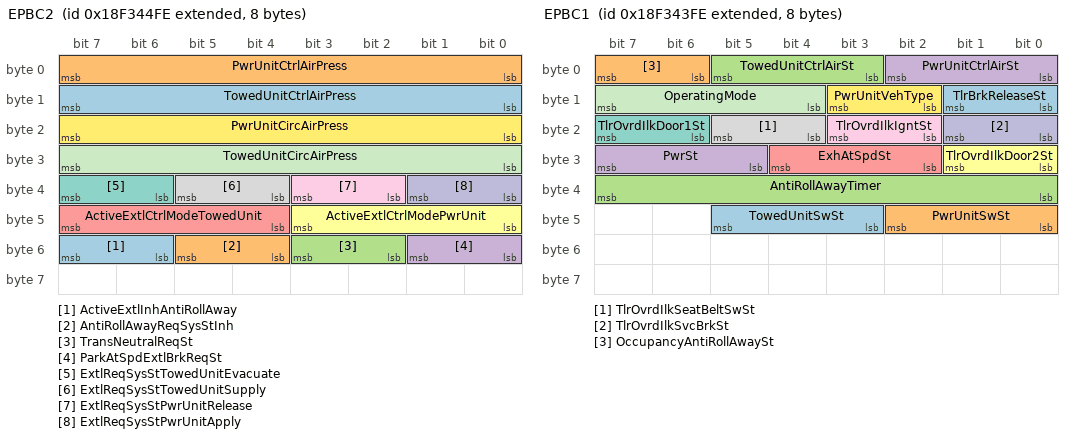
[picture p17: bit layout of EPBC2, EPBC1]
BO_ 2566079742 EPBC2: 8 Vector__XXX
 SG_ ActiveExtlInhAntiRollAway : 54|2@1+ (1,0) [0|3] "" Vector__XXX
 SG_ AntiRollAwayReqSysStInh : 52|2@1+ (1,0) [0|3] "" Vector__XXX
 SG_ TransNeutralReqSt : 50|2@1+ (1,0) [0|3] "" Vector__XXX
 SG_ ParkAtSpdExtlBrkReqSt : 48|2@1+ (1,0) [0|3] "" Vector__XXX
 SG_ ActiveExtlCtrlModeTowedUnit : 44|4@1+ (1,0) [0|15] "" Vector__XXX
 SG_ ActiveExtlCtrlModePwrUnit : 40|4@1+ (1,0) [0|15] "" Vector__XXX
 SG_ ExtlReqSysStTowedUnitEvacuate : 38|2@1+ (1,0) [0|3] "" Vector__XXX
 SG_ ExtlReqSysStTowedUnitSupply : 36|2@1+ (1,0) [0|3] "" Vector__XXX
 SG_ ExtlReqSysStPwrUnitRelease : 34|2@1+ (1,0) [0|3] "" Vector__XXX
 SG_ ExtlReqSysStPwrUnitApply : 32|2@1+ (1,0) [0|3] "" Vector__XXX
 SG_ TowedUnitCircAirPress : 24|8@1+ (8,0) [0|2000] "kPa" Vector__XXX
 SG_ PwrUnitCircAirPress : 16|8@1+ (8,0) [0|2000] "kPa" Vector__XXX
 SG_ TowedUnitCtrlAirPress : 8|8@1+ (8,0) [0|2000] "kPa" Vector__XXX
 SG_ PwrUnitCtrlAirPress : 0|8@1+ (8,0) [0|2000] "kPa" Vector__XXX

BO_ 2566079486 EPBC1: 8 Vector__XXX
 SG_ TowedUnitSwSt : 43|3@1+ (1,0) [0|7] "" Vector__XXX
 SG_ PwrUnitSwSt : 40|3@1+ (1,0) [0|7] "" Vector__XXX
 SG_ AntiRollAwayTimer : 32|8@1+ (1,0) [0|240] "s" Vector__XXX
 SG_ PwrSt : 29|3@1+ (1,0) [0|7] "" Vector__XXX
 SG_ ExhAtSpdSt : 26|3@1+ (1,0) [0|7] "" Vector__XXX
 SG_ TlrOvrdIlkDoor2St : 24|2@1+ (1,0) [0|3] "" Vector__XXX
 SG_ TlrOvrdIlkDoor1St : 22|2@1+ (1,0) [0|3] "" Vector__XXX
 SG_ TlrOvrdIlkSeatBeltSwSt : 20|2@1+ (1,0) [0|3] "" Vector__XXX
 SG_ TlrOvrdIlkIgntSt : 18|2@1+ (1,0) [0|3] "" Vector__XXX
 SG_ TlrOvrdIlkSvcBrkSt : 16|2@1+ (1,0) [0|3] "" Vector__XXX
 SG_ OperatingMode : 12|4@1+ (1,0) [0|15] "" Vector__XXX
 SG_ PwrUnitVehType : 10|2@1+ (1,0) [0|3] "" Vector__XXX
 SG_ TlrBrkReleaseSt : 8|2@1+ (1,0) [0|3] "" Vector__XXX
 SG_ OccupancyAntiRollAwaySt : 6|2@1+ (1,0) [0|3] "" Vector__XXX
 SG_ TowedUnitCtrlAirSt : 3|3@1+ (1,0) [0|7] "" Vector__XXX
 SG_ PwrUnitCtrlAirSt : 0|3@1+ (1,0) [0|7] "" Vector__XXX

BO_ 2555313918 FDTPDT: 12 Vector__XXX
 SG_ SessionNumber : 0|4@1+ (1,0) [0|7] "" Vector__XXX
 SG_ SegmentNumber : 8|24@1+ (1,0) [0|16777215] "" Vector__XXX
 SG_ DataTransferFormatInd : 4|4@1+ (1,0) [0|15] "" Vector__XXX

BO_ 2555248382 FDTPCM: 12 Vector__XXX
 SG_ TotalNoOfSegments m0 : 32|24@1+ (1,0) [0|16777215] "" Vector__XXX
 SG_ TotalMsgSize m0 : 8|24@1+ (1,0) [0|16777215] "" Vector__XXX
 SG_ RequestCode m1 : 64|8@1+ (1,0) [0|255] "" Vector__XXX
 SG_ PgnOfSegmentedMsg : 72|24@1+ (1,0) [0|262143] "" Vector__XXX
 SG_ NumberOfSegments m1 : 56|8@1+ (1,0) [0|255] "" Vector__XXX
 SG_ NextSegment m1 : 32|24@1+ (1,0) [0|16777215] "" Vector__XXX
 SG_ MaxNoOfSegments m0 : 56|8@1+ (1,0) [0|255] "" Vector__XXX
 SG_ SizeOfAssuranceData m2 : 56|8@1+ (1,0) [0|52] "" Vector__XXX
 SG_ AssuranceDataType m0 : 64|8@1+ (1,0) [0|255] "" Vector__XXX
 SG_ ConAbortReason m15 : 64|8@1+ (1,0) [0|0] "" Vector__XXX
 SG_ SessionNumber : 4|4@1+ (1,0) [0|7] "" Vector__XXX
 SG_ ControlByte M : 0|4@1+ (1,0) [0|0] "" Vector__XXX

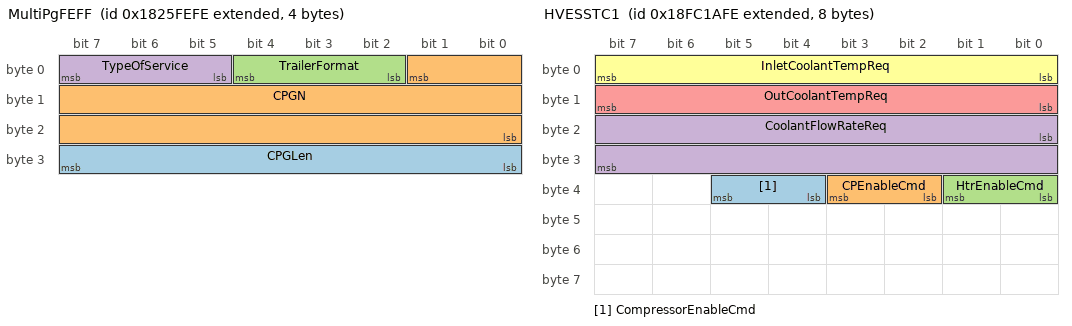
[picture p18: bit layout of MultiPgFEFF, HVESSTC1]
BO_ 2552626942 MultiPgFEFF: 4 Vector__XXX
 SG_ CPGLen : 31|8@0+ (1,0) [0|60] "" Vector__XXX
 SG_ CPGN : 1|18@0+ (1,0) [0|262143] "" Vector__XXX
 SG_ TrailerFormat : 4|3@0+ (1,0) [0|7] "" Vector__XXX
 SG_ TypeOfService : 7|3@0+ (1,0) [0|7] "" Vector__XXX

BO_ 2566679038 EVOI1: 8 Vector__XXX
 SG_ HVESSEstRemainingDist : 0|16@1+ (0.25,0) [0|16063.75] "km" Vector__XXX

BO_ 2365332478 HVESSTC2: 8 Vector__XXX
 SG_ CompressorPercentSpdCmd : 40|8@1+ (0.5,0) [0|100] "%" Vector__XXX
 SG_ CompressorSpdCmd : 24|16@1+ (0.5,0) [0|32127.5] "rpm" Vector__XXX
 SG_ CPPercentSpdCmd : 16|8@1+ (0.5,0) [0|100] "%" Vector__XXX
 SG_ CPSpdCmd : 0|16@1+ (0.5,0) [0|32127.5] "rpm" Vector__XXX

BO_ 2566658814 HVESSTC1: 8 Vector__XXX
 SG_ CompressorEnableCmd : 36|2@1+ (1,0) [0|3] "" Vector__XXX
 SG_ CPEnableCmd : 34|2@1+ (1,0) [0|3] "" Vector__XXX
 SG_ HtrEnableCmd : 32|2@1+ (1,0) [0|3] "" Vector__XXX
 SG_ CoolantFlowRateReq : 16|16@1+ (0.5,0) [0|32127.5] "l/min" Vector__XXX
 SG_ OutCoolantTempReq : 8|8@1+ (1,-40) [-40|210] "°C" Vector__XXX
 SG_ InletCoolantTempReq : 0|8@1+ (1,-40) [-40|210] "°C" Vector__XXX

BO_ 2566564606 EATC2: 8 Vector__XXX
 SG_ CurGear : 8|8@1+ (1,-125) [-125|125] "" Vector__XXX
 SG_ SelectedGear : 0|8@1+ (1,-125) [-125|125] "" Vector__XXX

BO_ 2566564350 TSTI: 8 Vector__XXX
 SG_ OneIntmdShaftPeakTwist : 16|8@1+ (0.1,-12.5) [-12.5|12.5] "deg" Vector__XXX
 SG_ OneOutShaftPeakTwist : 8|8@1+ (0.1,-12.5) [-12.5|12.5] "deg" Vector__XXX
 SG_ OneInputShaftPeakTwist : 0|8@1+ (0.1,-12.5) [-12.5|12.5] "deg" Vector__XXX

BO_ 2566564094 T1HIST: 12 Vector__XXX
 SG_ OpTimeSinceRebuild : 64|32@1+ (1,0) [0|4211081215] "s" Vector__XXX
 SG_ TotalOutShaftRevolutions : 32|32@1+ (1000,0) [0|4211081215000] "r" Vector__XXX
 SG_ TotalHoursOfOp : 0|32@1+ (1,0) [0|4211081215] "s" Vector__XXX

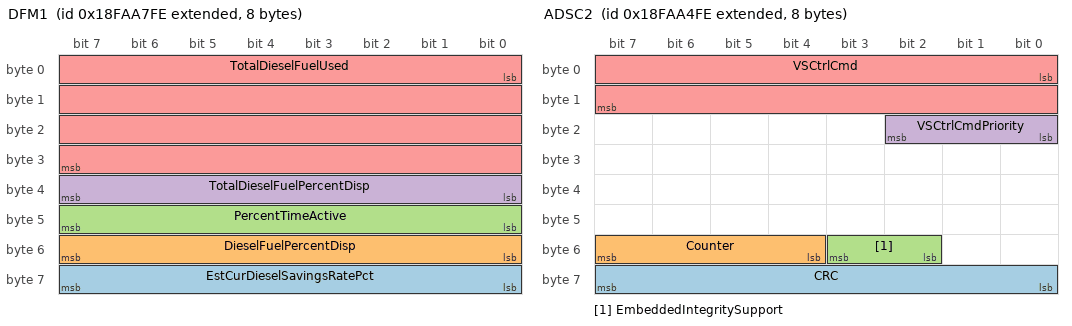
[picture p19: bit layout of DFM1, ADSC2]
BO_ 2566563838 DFM1: 8 Vector__XXX
 SG_ EstCurDieselSavingsRatePct : 56|8@1+ (0.4,0) [0|100] "%" Vector__XXX
 SG_ DieselFuelPercentDisp : 48|8@1+ (0.4,0) [0|100] "%" Vector__XXX
 SG_ PercentTimeActive : 40|8@1+ (0.4,0) [0|100] "%" Vector__XXX
 SG_ TotalDieselFuelPercentDisp : 32|8@1+ (0.5,0) [0|125] "%" Vector__XXX
 SG_ TotalDieselFuelUsed : 0|32@1+ (0.5,0) [0|2105540607.5] "l" Vector__XXX

BO_ 2566563582 DFM2: 8 Vector__XXX
 SG_ TotalDieselFuelDemand : 32|32@1+ (0.5,0) [0|2105540607.5] "l" Vector__XXX
 SG_ TotalDieselFuelDispByGasFuel : 0|32@1+ (0.5,0) [0|2105540607.5] "l" Vector__XXX

BO_ 2566563326 DFM3: 8 Vector__XXX
 SG_ StReason : 24|8@1+ (1,0) [0|255] "" Vector__XXX
 SG_ OperatingSt : 16|4@1+ (1,0) [0|15] "" Vector__XXX
 SG_ EstCurFuelSavingsRate : 0|16@1+ (0.05,0) [0|3212.75] "l/h" Vector__XXX

BO_ 2566563070 ADSC2: 8 Vector__XXX
 SG_ CRC : 56|8@1+ (1,0) [0|255] "" Vector__XXX
 SG_ Counter : 52|4@1+ (1,0) [0|15] "" Vector__XXX
 SG_ EmbeddedIntegritySupport : 50|2@1+ (1,0) [0|3] "" Vector__XXX
 SG_ VSCtrlCmdPriority : 16|3@1+ (1,0) [0|7] "" Vector__XXX
 SG_ VSCtrlCmd : 0|16@1+ (0.00390625,0) [0|250.99609375] "km/h" Vector__XXX

BO_ 2566562814 HVESP26CFG: 19 Vector__XXX
 SG_ NomRatedCapacity : 128|24@1+ (0.001,0) [0|16449.535] "kWh" Vector__XXX
 SG_ CellMinVLmt : 120|8@1+ (0.02044,0) [0|5.11] "V" Vector__XXX
 SG_ CellMaxVLmt : 112|8@1+ (0.02044,0) [0|5.11] "V" Vector__XXX
 SG_ RecommendedMinOperatingTemp : 96|16@1+ (0.03125,-273) [-273|1734.96875] "°C" Vector__XXX
 SG_ RecommendedMaxOperatingTemp : 80|16@1+ (0.03125,-273) [-273|1734.96875] "°C" Vector__XXX
 SG_ RecommendedMaxStOfCharge : 64|16@1+ (0.0015625,0) [0|100.3984375] "%" Vector__XXX
 SG_ RecommendedMinStOfCharge : 48|16@1+ (0.0015625,0) [0|100.3984375] "%" Vector__XXX
 SG_ RecommendedMaxOperatingV : 32|16@1+ (0.05,0) [0|3212.75] "V" Vector__XXX
 SG_ RecommendedMinOperatingV : 16|16@1+ (0.05,0) [0|3212.75] "V" Vector__XXX
 SG_ NomV : 0|16@1+ (0.05,0) [0|3212.75] "V" Vector__XXX

BO_ 2633671422 HVESP26HIST: 19 Vector__XXX
 SG_ TotalEnergyOut : 120|32@1+ (1,0) [0|4211081215] "kWh" Vector__XXX
 SG_ TotalEnergyInput : 88|32@1+ (1,0) [0|4211081215] "kWh" Vector__XXX
 SG_ TotalAccumulatedCharge : 56|32@1+ (100,0) [0|421108121500] "Ah" Vector__XXX
 SG_ TotalEnergyThroughput : 24|32@1+ (100,0) [0|421108121500] "Wh" Vector__XXX
 SG_ ContactorOpenUnderLoadCount : 8|16@1+ (1,0) [0|64255] "" Vector__XXX
 SG_ StOfHealth : 0|8@1+ (0.4,0) [0|100] "%" Vector__XXX

BO_ 2566562302 HVESP25CFG: 19 Vector__XXX
 SG_ NomRatedCapacity : 128|24@1+ (0.001,0) [0|16449.535] "kWh" Vector__XXX
 SG_ CellMinVLmt : 120|8@1+ (0.02044,0) [0|5.11] "V" Vector__XXX
 SG_ CellMaxVLmt : 112|8@1+ (0.02044,0) [0|5.11] "V" Vector__XXX
 SG_ RecommendedMinOperatingTemp : 96|16@1+ (0.03125,-273) [-273|1734.96875] "°C" Vector__XXX
 SG_ RecommendedMaxOperatingTemp : 80|16@1+ (0.03125,-273) [-273|1734.96875] "°C" Vector__XXX
 SG_ RecommendedMaxStOfCharge : 64|16@1+ (0.0015625,0) [0|100.3984375] "%" Vector__XXX
 SG_ RecommendedMinStOfCharge : 48|16@1+ (0.0015625,0) [0|100.3984375] "%" Vector__XXX
 SG_ RecommendedMaxOperatingV : 32|16@1+ (0.05,0) [0|3212.75] "V" Vector__XXX
 SG_ RecommendedMinOperatingV : 16|16@1+ (0.05,0) [0|3212.75] "V" Vector__XXX
 SG_ NomV : 0|16@1+ (0.05,0) [0|3212.75] "V" Vector__XXX

BO_ 2633670910 HVESP25HIST: 19 Vector__XXX
 SG_ TotalEnergyOut : 120|32@1+ (1,0) [0|4211081215] "kWh" Vector__XXX
 SG_ TotalEnergyInput : 88|32@1+ (1,0) [0|4211081215] "kWh" Vector__XXX
 SG_ TotalAccumulatedCharge : 56|32@1+ (100,0) [0|421108121500] "Ah" Vector__XXX
 SG_ TotalEnergyThroughput : 24|32@1+ (100,0) [0|421108121500] "Wh" Vector__XXX
 SG_ ContactorOpenUnderLoadCount : 8|16@1+ (1,0) [0|64255] "" Vector__XXX
 SG_ StOfHealth : 0|8@1+ (0.4,0) [0|100] "%" Vector__XXX

BO_ 2566561790 HVESP24CFG: 19 Vector__XXX
 SG_ NomRatedCapacity : 128|24@1+ (0.001,0) [0|16449.535] "kWh" Vector__XXX
 SG_ CellMinVLmt : 120|8@1+ (0.02044,0) [0|5.11] "V" Vector__XXX
 SG_ CellMaxVLmt : 112|8@1+ (0.02044,0) [0|5.11] "V" Vector__XXX
 SG_ RecommendedMinOperatingTemp : 96|16@1+ (0.03125,-273) [-273|1734.96875] "°C" Vector__XXX
 SG_ RecommendedMaxOperatingTemp : 80|16@1+ (0.03125,-273) [-273|1734.96875] "°C" Vector__XXX
 SG_ RecommendedMaxStOfCharge : 64|16@1+ (0.0015625,0) [0|100.3984375] "%" Vector__XXX
 SG_ RecommendedMinStOfCharge : 48|16@1+ (0.0015625,0) [0|100.3984375] "%" Vector__XXX
 SG_ RecommendedMaxOperatingV : 32|16@1+ (0.05,0) [0|3212.75] "V" Vector__XXX
 SG_ RecommendedMinOperatingV : 16|16@1+ (0.05,0) [0|3212.75] "V" Vector__XXX
 SG_ NomV : 0|16@1+ (0.05,0) [0|3212.75] "V" Vector__XXX

BO_ 2633670398 HVESP24HIST: 19 Vector__XXX
 SG_ TotalEnergyOut : 120|32@1+ (1,0) [0|4211081215] "kWh" Vector__XXX
 SG_ TotalEnergyInput : 88|32@1+ (1,0) [0|4211081215] "kWh" Vector__XXX
 SG_ TotalAccumulatedCharge : 56|32@1+ (100,0) [0|421108121500] "Ah" Vector__XXX
 SG_ TotalEnergyThroughput : 24|32@1+ (100,0) [0|421108121500] "Wh" Vector__XXX
 SG_ ContactorOpenUnderLoadCount : 8|16@1+ (1,0) [0|64255] "" Vector__XXX
 SG_ StOfHealth : 0|8@1+ (0.4,0) [0|100] "%" Vector__XXX

BO_ 2566561278 HVESP23CFG: 19 Vector__XXX
 SG_ NomRatedCapacity : 128|24@1+ (0.001,0) [0|16449.535] "kWh" Vector__XXX
 SG_ CellMinVLmt : 120|8@1+ (0.02044,0) [0|5.11] "V" Vector__XXX
 SG_ CellMaxVLmt : 112|8@1+ (0.02044,0) [0|5.11] "V" Vector__XXX
 SG_ RecommendedMinOperatingTemp : 96|16@1+ (0.03125,-273) [-273|1734.96875] "°C" Vector__XXX
 SG_ RecommendedMaxOperatingTemp : 80|16@1+ (0.03125,-273) [-273|1734.96875] "°C" Vector__XXX
 SG_ RecommendedMaxStOfCharge : 64|16@1+ (0.0015625,0) [0|100.3984375] "%" Vector__XXX
 SG_ RecommendedMinStOfCharge : 48|16@1+ (0.0015625,0) [0|100.3984375] "%" Vector__XXX
 SG_ RecommendedMaxOperatingV : 32|16@1+ (0.05,0) [0|3212.75] "V" Vector__XXX
 SG_ RecommendedMinOperatingV : 16|16@1+ (0.05,0) [0|3212.75] "V" Vector__XXX
 SG_ NomV : 0|16@1+ (0.05,0) [0|3212.75] "V" Vector__XXX

CM_ BO_ 2364758270 "High Voltage Energy Storage Pack 7 Data 12
Data set 12 (electrical data) for High Voltage Energy Storage Pack 7.";
CM_ SG_ 2364758270 Cur "The current in or out of this High Voltage Energy Storage Pack instance. This parameter should be synchronized with SPN 22492 (HVESP7 Voltage Level (Extended Range)) such that a realized power value can be calculated. This parameter is defined from ...";
CM_ SG_ 2364758270 Lvl "The voltage level of this High Voltage Energy Storage Pack instance. This parameter should be synchronized with SPN 22493 (HVESP7 Current (Extended Range)) such that a realized power value can be calculated. If the HVES component physically contains ...";
CM_ SG_ 2364758270 AvailableChargePwr "The rate at which this High Voltage Energy Storage Pack instance can currently receive energy from a regenerative or recharging system.
This parameter is for one of multiple packs in an HVESS. If there is only one pack in the system, the HVESS ...";
CM_ SG_ 2364758270 AvailableDisPwr "The rate at which this High Voltage Energy Storage Pack instance can currently provide energy for propulsion or other uses.
This parameter is for one of multiple packs in an HVESS. If there is only one pack in the system, the HVESS parameters ...";
CM_ BO_ 2364758014 "High Voltage Energy Storage Pack 6 Data 13
Data set 13 (electrical data) for High Voltage Energy Storage Pack 6.";
CM_ SG_ 2364758014 NomChargeCurLmt "The nominal current flow limit into the High Voltage Energy Storage Pack instance. This limit is a preferred boundary for normal operation.  Operating within this limit reduces negative impacts on battery life or battery health, but should not ...";
CM_ SG_ 2364758014 NomDisCurLmt "The nominal current flow limit out of the High Voltage Energy Storage Pack instance. This limit is a preferred boundary for normal operation.  Operating within this limit reduces negative impacts on battery life or battery health, but should not ...";
CM_ SG_ 2364758014 MaxCurChargeCurLmt "The maximum instantaneous current flow limit into this High Voltage Energy Storage Pack instance. This parameter is defined from the high voltage energy storage pack's point of view and should reflect the instantaneous capability of the pack.  The ...";
CM_ SG_ 2364758014 MaxCurDisCurLmt "The maximum instantaneous current flow limit out of this High Voltage Energy Storage Pack instance. This parameter is defined from the high voltage energy storage pack's point of view and should reflect the instantaneous capability of the pack.  The ...";
CM_ BO_ 2364757758 "High Voltage Energy Storage Pack 6 Data 12
Data set 12 (electrical data) for High Voltage Energy Storage Pack 6.";
CM_ SG_ 2364757758 Cur "The current in or out of this High Voltage Energy Storage Pack instance. This parameter should be synchronized with SPN 22470 (HVESP6 Voltage Level (Extended Range)) such that a realized power value can be calculated. This parameter is defined from ...";
CM_ SG_ 2364757758 Lvl "The voltage level of this High Voltage Energy Storage Pack instance. This parameter should be synchronized with SPN 22471 (HVESP6 Current (Extended Range)) such that a realized power value can be calculated. If the HVES component physically contains ...";
CM_ SG_ 2364757758 AvailableChargePwr "The rate at which this High Voltage Energy Storage Pack instance can currently receive energy from a regenerative or recharging system.
This parameter is for one of multiple packs in an HVESS. If there is only one pack in the system, the HVESS ...";
CM_ SG_ 2364757758 AvailableDisPwr "The rate at which this High Voltage Energy Storage Pack instance can currently provide energy for propulsion or other uses.
This parameter is for one of multiple packs in an HVESS. If there is only one pack in the system, the HVESS parameters ...";
CM_ BO_ 2364757502 "High Voltage Energy Storage Pack 5 Data 13
Data set 13 (electrical data) for High Voltage Energy Storage Pack 5.";
CM_ SG_ 2364757502 NomChargeCurLmt "The nominal current flow limit into the High Voltage Energy Storage Pack instance. This limit is a preferred boundary for normal operation.  Operating within this limit reduces negative impacts on battery life or battery health, but should not ...";
CM_ SG_ 2364757502 NomDisCurLmt "The nominal current flow limit out of the High Voltage Energy Storage Pack instance. This limit is a preferred boundary for normal operation.  Operating within this limit reduces negative impacts on battery life or battery health, but should not ...";
CM_ SG_ 2364757502 MaxCurChargeCurLmt "The maximum instantaneous current flow limit into this High Voltage Energy Storage Pack instance. This parameter is defined from the high voltage energy storage pack's point of view and should reflect the instantaneous capability of the pack.  The ...";
CM_ SG_ 2364757502 MaxCurDisCurLmt "The maximum instantaneous current flow limit out of this High Voltage Energy Storage Pack instance. This parameter is defined from the high voltage energy storage pack's point of view and should reflect the instantaneous capability of the pack.  The ...";
CM_ BO_ 2364757246 "High Voltage Energy Storage Pack 5 Data 12
Data set 12 (electrical data) for High Voltage Energy Storage Pack 5.";
CM_ SG_ 2364757246 Cur "The current in or out of this High Voltage Energy Storage Pack instance. This parameter should be synchronized with SPN 22448 (HVESP5 Voltage Level (Extended Range)) such that a realized power value can be calculated. This parameter is defined from ...";
CM_ SG_ 2364757246 Lvl "The voltage level of this High Voltage Energy Storage Pack instance. This parameter should be synchronized with SPN 22449 (HVESP5 Current (Extended Range)) such that a realized power value can be calculated. If the HVES component physically contains ...";
CM_ SG_ 2364757246 AvailableChargePwr "The rate at which this High Voltage Energy Storage Pack instance can currently receive energy from a regenerative or recharging system.
This parameter is for one of multiple packs in an HVESS. If there is only one pack in the system, the HVESS ...";
CM_ SG_ 2364757246 AvailableDisPwr "The rate at which this High Voltage Energy Storage Pack instance can currently provide energy for propulsion or other uses.
This parameter is for one of multiple packs in an HVESS. If there is only one pack in the system, the HVESS parameters ...";
CM_ BO_ 2364756990 "High Voltage Energy Storage Pack 4 Data 13
Data set 13 (electrical data) for High Voltage Energy Storage Pack 4.";
CM_ SG_ 2364756990 NomChargeCurLmt "The nominal current flow limit into the High Voltage Energy Storage Pack instance. This limit is a preferred boundary for normal operation.  Operating within this limit reduces negative impacts on battery life or battery health, but should not ...";
CM_ SG_ 2364756990 NomDisCurLmt "The nominal current flow limit out of the High Voltage Energy Storage Pack instance. This limit is a preferred boundary for normal operation.  Operating within this limit reduces negative impacts on battery life or battery health, but should not ...";
CM_ SG_ 2364756990 MaxCurChargeCurLmt "The maximum instantaneous current flow limit into this High Voltage Energy Storage Pack instance. This parameter is defined from the high voltage energy storage pack's point of view and should reflect the instantaneous capability of the pack.  The ...";
CM_ SG_ 2364756990 MaxCurDisCurLmt "The maximum instantaneous current flow limit out of this High Voltage Energy Storage Pack instance. This parameter is defined from the high voltage energy storage pack's point of view and should reflect the instantaneous capability of the pack.  The ...";
CM_ BO_ 2364756734 "High Voltage Energy Storage Pack 4 Data 12
Data set 12 (electrical data) for High Voltage Energy Storage Pack 4.";
CM_ SG_ 2364756734 Cur "The current in or out of this High Voltage Energy Storage Pack instance. This parameter should be synchronized with SPN 22426 (HVESP4 Voltage Level (Extended Range)) such that a realized power value can be calculated. This parameter is defined from ...";
CM_ SG_ 2364756734 Lvl "The voltage level of this High Voltage Energy Storage Pack instance. This parameter should be synchronized with SPN 22427 (HVESP4 Current (Extended Range)) such that a realized power value can be calculated. If the HVES component physically contains ...";
CM_ SG_ 2364756734 AvailableChargePwr "The rate at which this High Voltage Energy Storage Pack instance can currently receive energy from a regenerative or recharging system.
This parameter is for one of multiple packs in an HVESS. If there is only one pack in the system, the HVESS ...";
CM_ SG_ 2364756734 AvailableDisPwr "The rate at which this High Voltage Energy Storage Pack instance can currently provide energy for propulsion or other uses.
This parameter is for one of multiple packs in an HVESS. If there is only one pack in the system, the HVESS parameters ...";
CM_ BO_ 2364756478 "High Voltage Energy Storage Pack 3 Data 13
Data set 13 (electrical data) for High Voltage Energy Storage Pack 3.";
CM_ SG_ 2364756478 NomChargeCurLmt "The nominal current flow limit into the High Voltage Energy Storage Pack instance. This limit is a preferred boundary for normal operation.  Operating within this limit reduces negative impacts on battery life or battery health, but should not ...";
CM_ SG_ 2364756478 NomDisCurLmt "The nominal current flow limit out of the High Voltage Energy Storage Pack instance. This limit is a preferred boundary for normal operation.  Operating within this limit reduces negative impacts on battery life or battery health, but should not ...";
CM_ SG_ 2364756478 MaxCurChargeCurLmt "The maximum instantaneous current flow limit into this High Voltage Energy Storage Pack instance. This parameter is defined from the high voltage energy storage pack's point of view and should reflect the instantaneous capability of the pack.  The ...";
CM_ SG_ 2364756478 MaxCurDisCurLmt "The maximum instantaneous current flow limit out of this High Voltage Energy Storage Pack instance. This parameter is defined from the high voltage energy storage pack's point of view and should reflect the instantaneous capability of the pack.  The ...";
CM_ BO_ 2364756222 "High Voltage Energy Storage Pack 3 Data 12
Data set 12 (electrical data) for High Voltage Energy Storage Pack 3.";
CM_ SG_ 2364756222 Cur "The current in or out of this High Voltage Energy Storage Pack instance. This parameter should be synchronized with SPN 22404 (HVESP3 Voltage Level (Extended Range)) such that a realized power value can be calculated. This parameter is defined from ...";
CM_ SG_ 2364756222 Lvl "The voltage level of this High Voltage Energy Storage Pack instance. This parameter should be synchronized with SPN 22405 (HVESP3 Current (Extended Range)) such that a realized power value can be calculated. If the HVES component physically contains ...";
CM_ SG_ 2364756222 AvailableChargePwr "The rate at which this High Voltage Energy Storage Pack instance can currently receive energy from a regenerative or recharging system.
This parameter is for one of multiple packs in an HVESS. If there is only one pack in the system, the HVESS ...";
CM_ SG_ 2364756222 AvailableDisPwr "The rate at which this High Voltage Energy Storage Pack instance can currently provide energy for propulsion or other uses.
This parameter is for one of multiple packs in an HVESS. If there is only one pack in the system, the HVESS parameters ...";
CM_ BO_ 2364755966 "High Voltage Energy Storage Pack 2 Data 13
Data set 13 (electrical data) for High Voltage Energy Storage Pack 2.";
CM_ SG_ 2364755966 NomChargeCurLmt "The nominal current flow limit into the High Voltage Energy Storage Pack instance. This limit is a preferred boundary for normal operation.  Operating within this limit reduces negative impacts on battery life or battery health, but should not ...";
CM_ SG_ 2364755966 NomDisCurLmt "The nominal current flow limit out of the High Voltage Energy Storage Pack instance. This limit is a preferred boundary for normal operation.  Operating within this limit reduces negative impacts on battery life or battery health, but should not ...";
CM_ SG_ 2364755966 MaxCurChargeCurLmt "The maximum instantaneous current flow limit into this High Voltage Energy Storage Pack instance. This parameter is defined from the high voltage energy storage pack's point of view and should reflect the instantaneous capability of the pack.  The ...";
CM_ SG_ 2364755966 MaxCurDisCurLmt "The maximum instantaneous current flow limit out of this High Voltage Energy Storage Pack instance. This parameter is defined from the high voltage energy storage pack's point of view and should reflect the instantaneous capability of the pack.  The ...";
CM_ BO_ 2364755710 "High Voltage Energy Storage Pack 2 Data 12
Data set 12 (electrical data) for High Voltage Energy Storage Pack 2.";
CM_ SG_ 2364755710 Cur "The current in or out of this High Voltage Energy Storage Pack instance. This parameter should be synchronized with SPN 22382 (HVESP2 Voltage Level (Extended Range)) such that a realized power value can be calculated. This parameter is defined from ...";
CM_ SG_ 2364755710 Lvl "The voltage level of this High Voltage Energy Storage Pack instance. This parameter should be synchronized with SPN 22383 (HVESP2 Current (Extended Range)) such that a realized power value can be calculated. If the HVES component physically contains ...";
CM_ SG_ 2364755710 AvailableChargePwr "The rate at which this High Voltage Energy Storage Pack instance can currently receive energy from a regenerative or recharging system.
This parameter is for one of multiple packs in an HVESS. If there is only one pack in the system, the HVESS ...";
CM_ SG_ 2364755710 AvailableDisPwr "The rate at which this High Voltage Energy Storage Pack instance can currently provide energy for propulsion or other uses.
This parameter is for one of multiple packs in an HVESS. If there is only one pack in the system, the HVESS parameters ...";
CM_ BO_ 2364755454 "High Voltage Energy Storage Pack 1 Data 13
Data set 13 (electrical data) for High Voltage Energy Storage Pack 1.";
CM_ SG_ 2364755454 NomChargeCurLmt "The nominal current flow limit into the High Voltage Energy Storage Pack instance. This limit is a preferred boundary for normal operation.  Operating within this limit reduces negative impacts on battery life or battery health, but should not ...";
CM_ SG_ 2364755454 NomDisCurLmt "The nominal current flow limit out of the High Voltage Energy Storage Pack instance. This limit is a preferred boundary for normal operation.  Operating within this limit reduces negative impacts on battery life or battery health, but should not ...";
CM_ SG_ 2364755454 MaxCurChargeCurLmt "The maximum instantaneous current flow limit into this High Voltage Energy Storage Pack instance. This parameter is defined from the high voltage energy storage pack's point of view and should reflect the instantaneous capability of the pack.  The ...";
CM_ SG_ 2364755454 MaxCurDisCurLmt "The maximum instantaneous current flow limit out of this High Voltage Energy Storage Pack instance. This parameter is defined from the high voltage energy storage pack's point of view and should reflect the instantaneous capability of the pack.  The ...";
CM_ BO_ 2364755198 "High Voltage Energy Storage Pack 1 Data 12
Data set 12 (electrical data) for High Voltage Energy Storage Pack 1.";
CM_ SG_ 2364755198 Cur "The current in or out of this High Voltage Energy Storage Pack instance. This parameter should be synchronized with SPN 22360 (HVESP1 Voltage Level (Extended Range)) such that a realized power value can be calculated. This parameter is defined from ...";
CM_ SG_ 2364755198 Lvl "The voltage level of this High Voltage Energy Storage Pack instance. This parameter should be synchronized with SPN 22361 (HVESP1 Current (Extended Range)) such that a realized power value can be calculated. If the HVES component physically contains ...";
CM_ SG_ 2364755198 AvailableChargePwr "The rate at which this High Voltage Energy Storage Pack instance can currently receive energy from a regenerative or recharging system.
This parameter is for one of multiple packs in an HVESS. If there is only one pack in the system, the HVESS ...";
CM_ SG_ 2364755198 AvailableDisPwr "The rate at which this High Voltage Energy Storage Pack instance can currently provide energy for propulsion or other uses.
This parameter is for one of multiple packs in an HVESS. If there is only one pack in the system, the HVESS parameters ...";
CM_ BO_ 2364754942 "Genset Real Power Control 2
Contains control information for the status, power and reactive power for generator grid code control functions.
These parameters are intended for stationary Generator/Engine components, not mobile applications.  See ...";
CM_ SG_ 2364754942 SecRealPwrOffsetRampRateSource "Indicates when the secondary frequency control or the integral local frequency control are controlling the real power offset ramp rate.

00b = Integral Local Frequency Regulation
01b = Secondary Regulation
10b = Error
11b = None";
CM_ SG_ 2364754942 SecRealPwrActiveSpOffsetSource "Indicates when the secondary frequency control or the integral local frequency control are controlling the real power offset.

00b = Integral Local Frequency Regulation
01b = Secondary Regulation
10b = Error
11b = None";
CM_ SG_ 2364754942 AndReactivePwrReversionSt "Indicates real power and reactive power reversion status. 

00b = Inactive
01b = Active
10b = Error
11b = Not available";
CM_ SG_ 2364754942 ReversionSt "Indicates when the real power reversion is active.

00b = Inactive
01b = Active
10b = Error
11b = Not available";
CM_ SG_ 2364754942 IntgLocalFreqCtrlResetSt "Indicates when a reset of the offset of the integral local frequency control is requested.

00b = Reset not requested
01b = Reset requested
10b = Error
11b = Not Available";
CM_ SG_ 2364754942 IntgLocalFreqCtrlOrSecFreqCtrlSt "Indicates when the integral local frequency control or the secondary frequency control function are enabled.

00b = Disabled
01b = Enabled
10b = Error
11b = Not available";
CM_ SG_ 2364754942 IntgLocalFreqCtrlSt "Indicates when the integral local frequency control is active

00b = Inactive
01b = Active
10b = Error
11b = Not available";
CM_ SG_ 2364754942 SecFreqCtrlSt "Indicates when the secondary frequency control is active.

00b = Inactive
01b = Active
10b = Error
11b = Not available";
CM_ SG_ 2364754942 IntgLocalFreqCtrlRealPwrOffset "Desired generator real power offset based on the real power demand by the integral local frequency control.";
CM_ SG_ 2364754942 DesSecFreqCtrlRealPwrOffset "Desired generator real power offset based on the real power demand by the secondary frequency control.";
CM_ BO_ 2364754686 "Genset Real Power Setpoint Demand
Contains control information for the status, power and reactive power for generator grid code control functions.
These parameters are intended for stationary Generator/Engine components, not mobile applications ...";
CM_ SG_ 2364754686 UtilOpRealPwrEnableSt "Indicates when the utility operator real power input status is enabled.

00b = Disabled
01b = Enabled
10b = Error
11b = Not available";
CM_ SG_ 2364754686 ThirdPartyOpRealPwrEnableSt "Indicates when the third party operator real power input status is enabled.

00b = Disabled
01b = Enabled
10b = Error
11b = Not available";
CM_ SG_ 2364754686 UtilOpRealPwrSt "Indicates when the utility operator real power is controlling the generator output power.

00b = Not Actively Controlling
01b = Actively Controlling
10b = Error
11b = Not available";
CM_ SG_ 2364754686 ThirdPartyOpRealPwrSt "Indicates when the third party operator real power is controlling the generator output power.

00b = Not Actively Controlling
01b = Actively Controlling
10b = Error
11b = Not available";
CM_ SG_ 2364754686 UtilOpRealPwrPctSp "The desired utility operator real power setpoint as a percentage of generator rated power.";
CM_ SG_ 2364754686 ThirdPartyOpRealPwrSp "The desired third party operator real power setpoint as a percentage of generator rated power.";
CM_ SG_ 2364754686 GenRealLoadCtrlBaseLoadSp "The desired real power base load setpoint as a percentage of generator rated power.";
CM_ BO_ 2498819326 "Genset Reactive Power and Supporting Functions
Contains control information for the status, power and reactive power for generator grid code control functions.
These parameters are intended for stationary Generator/Engine components, not mobile ...";
CM_ SG_ 2498819326 GenReactivePwrOverExcitLmtSt "Indicates that the generator reactive power is limited with an over excitation limitation.

00b = Inactive
01b = Active
10b = Error
11b = Not available";
CM_ SG_ 2498819326 GenReactivePwrUnderExcitLmtSt "Indicates that the generator reactive power is limited with an under excitation limitation.

00b = Inactive
01b = Active
10b = Error
11b = Not available";
CM_ SG_ 2498819326 GenFaultRideThroughSt "Indicates when a Fault Ride Through is detected.
Note:  The state 0001b = Fault Ride Through detected is used when the system is unable to determine high or low voltage
0000b = No Fault Ride Through detected
0001b = Fault Ride Through detected
 ...";
CM_ SG_ 2498819326 GenUtilDecouplingProtTestFuncSt "Indicates if the test function for the utility decoupling protection function is active or inactive.

00b = Inactive
01b = Active
10b = Error
11b = Not available";
CM_ SG_ 2498819326 GenUvAndOvProtTestFuncSt "Indicates if the test function for the overvoltage and undervoltage protection function is active or inactive.

00b = Inactive
01b = Active
10b = Error
11b = Not available";
CM_ SG_ 2498819326 TestFuncForTheProtSt "Indicates when the test function for the protection function is active or inactive.

00b = Inactive
01b = Active
10b = Error
11b = Not available";
CM_ SG_ 2498819326 SimulatedMainsFreqSt "Indicates when the test function for the simulated mains frequency is active or inactive. The simulated frequency offset can be added to the measured frequency or to the nominal frequency.
00b = Inactive
01b = Active
10b = Error
11b = Not ...";
CM_ SG_ 2498819326 SimulatedMainsFreqOffset "Simulated mains frequency offset for test functionality for grid code functions. The simulated frequency offset can be added to the measured frequency or to the nominal frequency.";
CM_ SG_ 2498819326 DemandedV "Voltage demanded by the reactive power and real power grid code functions.";
CM_ SG_ 2498819326 DemandedPwrFactor "Power factor demanded by the reactive power grid code functions.";
CM_ BO_ 2565918718 "Engine Turbocharger Wastegate Actuator and Exhaust Back Pressure Regulator Information 2";
CM_ SG_ 2565918718 FourOpSt "Used to identify the status of Engine Turbocharger Wastegate Actuator 4.
0000b = Normal
0001b = Alarm (fully operational but needs service)
0010b = Alarm High Severity (functional but transient performance may be reduced)
0011b = Derate Active ...";
CM_ SG_ 2565918718 ThreeOpSt "Used to identify the status of Engine Turbocharger Wastegate Actuator 3.
0000b = Normal
0001b = Alarm (fully operational but needs service)
0010b = Alarm High Severity (functional but transient performance may be reduced)
0011b = Derate Active ...";
CM_ BO_ 2565918462 "Engine Turbocharger Control 4
This PG contains commands for the Engine Turbocharger Wastegate Actuator 3 & 4.";
CM_ SG_ 2565918462 WastegateAct4Cmd "The command to a Turbocharger Wastegate actuator 4, normalized to percent, where 0% nominally represents fully closed (No Flow) and 100% represents fully open (Max Flow).";
CM_ SG_ 2565918462 WastegateAct3Cmd "The command to a Turbocharger Wastegate actuator 3, normalized to percent, where 0% nominally represents fully closed (No Flow) and 100% represents fully open (Max Flow).";
CM_ BO_ 2565905662 "Motor/Generator 6 Inverter Thermal Performance Status  
Inverter Thermal Performance Status Information";
CM_ SG_ 2565905662 CapLmt "A manufacturer defined thermal threshold beyond which product life may be reduced. 
According to SPN 22965 (Motor/Generator 6 Inverter Thermal Capability Used).
Detailed description is attached in Appendix D figure SPNxxx_A.";
CM_ SG_ 2565905662 CapUsed "Thermal Capability Used of this Motor/Generator Inverter instance. The calculation method must be defined by the manufacturer.
Thermal Capability is an indicator of available inverter power capability in relation to thermal conditions.
Detailed ...";
CM_ BO_ 2565905406 "Motor/Generator 5 Inverter Thermal Performance Status  
Inverter Thermal Performance Status Information";
CM_ SG_ 2565905406 CapLmt "A manufacturer defined thermal threshold beyond which product life may be reduced. 
According to SPN 22961 (Motor/Generator 5 Inverter Thermal Capability Used).
Detailed description is attached in Appendix D figure SPNxxx_A.";
CM_ SG_ 2565905406 CapUsed "Thermal Capability Used of this Motor/Generator Inverter instance. The calculation method must be defined by the manufacturer.
Thermal Capability is an indicator of available inverter power capability in relation to thermal conditions.
Detailed ...";
CM_ BO_ 2565905150 "Motor/Generator 4 Inverter Thermal Performance Status  
Inverter Thermal Performance Status Information";
CM_ SG_ 2565905150 CapLmt "A manufacturer defined thermal threshold beyond which product life may be reduced. 
According to SPN 22957 (Motor/Generator 4 Inverter Thermal Capability Used).
Detailed description is attached in Appendix D figure SPNxxx_A.";
CM_ SG_ 2565905150 CapUsed "Thermal Capability Used of this Motor/Generator Inverter instance. The calculation method must be defined by the manufacturer.
Thermal Capability is an indicator of available inverter power capability in relation to thermal conditions.
Detailed ...";
CM_ BO_ 2565904894 "Motor/Generator 3 Inverter Thermal Performance Status  
Inverter Thermal Performance Status Information";
CM_ SG_ 2565904894 CapLmt "A manufacturer defined thermal threshold beyond which product life may be reduced. 
According to SPN 22953 (Motor/Generator 3 Inverter Thermal Capability Used).
Detailed description is attached in Appendix D figure SPNxxx_A.";
CM_ SG_ 2565904894 CapUsed "Thermal Capability Used of this Motor/Generator Inverter instance. The calculation method must be defined by the manufacturer.
Thermal Capability is an indicator of available inverter power capability in relation to thermal conditions.
Detailed ...";
CM_ BO_ 2565904638 "Motor/Generator 2 Inverter Thermal Performance Status  
Inverter Thermal Performance Status Information";
CM_ SG_ 2565904638 CapLmt "A manufacturer defined thermal threshold beyond which product life may be reduced. 
According to SPN 22949 (Motor/Generator 2 Inverter Thermal Capability Used).
Detailed description is attached in Appendix D figure SPNxxx_A.";
CM_ SG_ 2565904638 CapUsed "Thermal Capability Used of this Motor/Generator Inverter instance. The calculation method must be defined by the manufacturer.
Thermal Capability is an indicator of available inverter power capability in relation to thermal conditions.
Detailed ...";
CM_ BO_ 2565904382 "Motor/Generator 1 Inverter Thermal Performance Status  
Inverter Thermal Performance Status Information";
CM_ SG_ 2565904382 CapLmt "A manufacturer defined thermal threshold beyond which product life may be reduced. According to SPN 22945 (Motor/Generator 1 Inverter Thermal Capability Used). Detailed description is attached in Appendix D figure SPNxxx_A.";
CM_ SG_ 2565904382 CapUsed "Thermal Capability Used of this Motor/Generator Inverter instance. The calculation method must be defined by the manufacturer. Thermal Capability is an indicator of available inverter power capability in relation to thermal conditions. Detailed ...";
CM_ BO_ 2565900542 "Wireless Charger Alignment Quality Status
Communicates the quality of alignment of the vehicle charger over top of the ground charger. This is used to aid the driver of the vehicle during approach and alignment.";
CM_ SG_ 2565900542 OverallQuality "Qualitative metric of overall alignment, 100% being optimally aligned and 0% not being aligned in any measurable way.";
CM_ SG_ 2565900542 ZQuality "Qualitative metric of alignment in the Z direction (vertical direction), 100 when the vehicle coil is above the nominal charging height, -100 when below the nominal charging height, 0 when the vehicle coil is at the nominal charging height.";
CM_ SG_ 2565900542 YQuality "Qualitative metric of alignment in the Y direction (left/right direction), 100 when the ground assembly coil is to the left of the vehicle coil, -100 when ground assembly coil is to the right of the vehicle, 0 when the charging coils are aligned.";
CM_ SG_ 2565900542 XQuality "Qualitative metric of alignment in the X direction (direction of travel), 100 when the ground assembly coil is in front of the vehicle coil, -100 when ground assembly coil is behind the vehicle coil, 0 when the charging coils are aligned.";
CM_ BO_ 2555117310 "EV Multi-Connection DC Charging Limits 1
Data used by the EVCC when negotiating charging limits with an EVSE that supports DC charging.
This data is sent to the EVSE on initial connection and may be dynamically updated during charging.
This PG ...";
CM_ SG_ 2555117310 HybMultiConnReqEnergyXferType "Hybrid  or Electric vehicle's required Energy transfer type for this connection
0000b = DC-Extended
0001b = DC-Core
0010b = Reserved
0011b = Reserved
0100b = Reserved
0101b = Reserved
0110b = Reserved
0111b = Reserved
1000b = Reserved
 ...";
CM_ SG_ 2555117310 HybMultiConnDCChargingPwrMax "Hybrid or Electric Vehicle's maximum rated DC charging input power,  for this connection.
This is communicated to a DC EVSE during initial exchange of parameters and may optionally be dynamically updated during charging.
When charging, the ...";
CM_ SG_ 2555117310 HybMultiConnDCChargingCurMax "Hybrid or Electric Vehicle's maximum rated DC charging input current, for this connection.
This is communicated to a DC EVSE during initial exchange of parameters and may optionally be dynamically updated during charging.
When charging, the ...";
CM_ SG_ 2555117310 HybMultiConnDCChargingVMax "Hybrid or Electric Vehicle's maximum allowed DC charging input voltage for this connection.
This is communicated to a DC EVSE during initial exchange of parameters and may optionally be dynamically updated during charging.
When charging, the ...";
CM_ BO_ 2555051774 "EV Multi-Connection DC Status 1
This message carries status of the vehicle during DC charging to the EVCC/EVSE.
This PG can be addressed to a specific EVCC and can be used on systems which support multiple active connections where different EVCCs ...";
CM_ SG_ 2555051774 StOfCharge "State of Charge for the battery pack being charged by this connection.

This value may be used by the connected EVSE for display purposes";
CM_ SG_ 2555051774 ErrorCode "Indicates the highest priority EV internal error state that may inhibit/abort charging
See SAE J2847-2 (April 2015 Section 4.2.26)
0000b = No Error
0001b = Battery Temperature too hot/cold
0010b = Shift Position  (Vehicle not in park)
0011b = ...";
CM_ SG_ 2555051774 RESSConditioningFlag "Informs the EVSE that the EV is using energy from the EVSE  to perform battery (RESS/HVES) conditioning.
See SAE J2847-2 (April 2015 Section 4.2.33)
00b = Battery conditioning not active
01b = Battery conditioning active
10b = Reserved
11b = ...";
CM_ SG_ 2555051774 CabinConditioningFlag "Informs the EVSE that the EV is performing cabin conditioning.

See SAE J2847-2 (April 2015 Section 4.2.23)

00b = Cabin conditioning not active
01b = Cabin conditioning active
10b = Reserved
11b = Not available";
CM_ BO_ 2554068734 "Battery Charger 2 Command 1
This PG is used to control the auxiliary output of a battery charger or other power source. The status of that auxiliary output is reported by PGN 64788 (BCH2). Typically this will used to charge the low voltage battery ...";
CM_ SG_ 2554068734 AuxChrgCmdTargetCur "Instantaneous requested DC output current limit.";
CM_ SG_ 2554068734 AuxChrgCmdTargetV "Instantaneous requested DC output voltage limit.";
CM_ SG_ 2554068734 AuxChrgCmdSequenceCounter "The message counter is used to detect situations where the transmitting ECU malfunction repeats the same frame all the time. The receiver of the information may use the counter parameter to
detect this situation. The transmitting device will ...";
CM_ SG_ 2554068734 AuxChrgCmdCRC "The CRC is defined as follows:
• Length: 8 bits
• Polynomial: x^8+x^5+x^3+x^2+x+1
• Initial Value: FFh
• Input Data Reflection: Not reflected
• Result Data Reflection: Not reflected
• XOR value: FFh
SAE makes no claim of the functional safety ...";
CM_ BO_ 2554003198 "Battery Charger 1 Command 1
This PG is used to control the main (or only) output of a battery charger or other power source. The status of the main output is reported by PGN 64789 (BCH1).
This PG is used in systems that support multiple, ...";
CM_ SG_ 2554003198 CmdTargetCur "Instantaneous requested DC output current limit.";
CM_ SG_ 2554003198 CmdTargetV "Instantaneous requested DC output voltage limit.";
CM_ SG_ 2554003198 CmdSequenceCounter "The message counter is used to detect situations where the transmitting ECU malfunction repeats the same frame all the time. The receiver of the information may use the counter parameter to
detect this situation. The transmitting device will ...";
CM_ SG_ 2554003198 CmdCRC "The CRC is defined as follows:
• Length: 8 bits
• Polynomial: x^8+x^5+x^3+x^2+x+1
• Initial Value: FFh
• Input Data Reflection: Not reflected
• Result Data Reflection: Not reflected
• XOR value: FFh
SAE makes no claim of the functional safety ...";
CM_ BO_ 2352611070 "External ACC Acceleration Request
Intended to provide the vehicle an Adaptive Cruise Control (ACC) acceleration interface to a powertrain cruise control system. The powertrain cruise control system has to process the demanded acceleration. This PG ...";
CM_ SG_ 2352611070 InMessageIntegrityDataSupported "Indicates the External ACC Acceleration Request CRC (SPN 22128) and the External ACC Acceleration Request  Counter (SPN 22129) is supported by the sender.
00b = External ACC Acceleration Request CRC and Counter is support by the sender
01b = ...";
CM_ SG_ 2352611070 CtrlMode "This signal defines if the External ACC acceleration request should be considered by the cruise control system.
When the signal state is No External ACC Acceleration Request (00b) the powertrain cruise control system should not consider the ...";
CM_ SG_ 2352611070 ExtlACCAccelerationReq "This signal is provided to a powertrain cruise control system from an external adaptive cruise control system. This acceleration value is intended as an input to the engine controller’s cruise control system. This signal is intended to be used to ...";
CM_ SG_ 2352611070 Counter "The counter is generated by the sender of the PG. The counter value is initialized to 0 for the first transmission of this PG. The counter shall be incremented by 1 for every following transmission of the PG. When the counter reaches the maximum ...";
CM_ SG_ 2352611070 CRC "This two byte signal field is reserved to support the use of an in-frame data integrity CRC.
When a CRC is correctly implemented as part of a Functional Safety process (ISO 26262) it can provide protection against the effects of faults within the ...";
CM_ BO_ 2566687486 "Fuel Cell Coolant Pump 2 Status
Indicates the status of Fuel Cell Coolant Pump 2.

Note: See PGN 64648 (Fuel Cell Coolant Pump 2 Command) for corresponding command message.";
CM_ SG_ 2566687486 EnableSt "Indicates the enable and direction status of the Fuel Cell Coolant Pump 2 system or component.

00b = Motor Off
01b = Motor On - Normal, Forward, or Default Direction
10b = Motor On - Reverse Direction
11b = Not available";
CM_ SG_ 2566687486 InputCur "This parameter indicates the input DC current to the Fuel Cell Coolant pump 2.";
CM_ SG_ 2566687486 InputV "Indicates the input DC voltage to the Fuel Cell Coolant pump 2.";
CM_ SG_ 2566687486 Spd "Indicates the speed of the Fuel Cell Coolant Pump 2.";
CM_ BO_ 2566687230 "Fuel Cell Coolant Pump 1 Status
Indicates the status of Fuel Cell Coolant Pump 1.

Note: See PGN 64647 (Fuel Cell Coolant Pump 1 Command) for corresponding command message.";
CM_ SG_ 2566687230 EnableSt "Indicates the enable and direction status of the Fuel Cell Coolant Pump 1 system or component.

00b = Motor Off
01b = Motor On - Normal, Forward, or Default Direction
10b = Motor On - Reverse Direction
11b = Not available";
CM_ SG_ 2566687230 Pump1InputCur "Indicates the input DC current to the Fuel Cell Coolant pump 1.";
CM_ SG_ 2566687230 Pump1InputV "Indicates the input DC voltage to the Fuel Cell Coolant pump 1.";
CM_ SG_ 2566687230 Spd "Indicates the speed of the Fuel Cell Coolant Pump 1.";
CM_ BO_ 2566686974 "Fuel Cell Coolant Pump 2 Command
The command message to the Fuel Cell Coolant Pump 2.

Note: See PGN 64650 (Fuel Cell Coolant Pump 2 Status) for corresponding status message.";
CM_ SG_ 2566686974 EnableCmd "Indicates the enable and direction command to the Fuel Cell Coolant Pump 2.

00b = Motor Off
01b = Motor On Normal/Default Direction
10b = Motor On Reverse Direction
11b = Don't Care/Take no action";
CM_ SG_ 2566686974 PercentSpdCmd "The speed commanded to the Fuel Cell Coolant Pump 2  in percentage of maximum speed.
Note:  Both Fuel Cell Coolant Pump 2 Speed Command and Fuel Cell Coolant Pump 2 Percent Speed Command cannot be used at the same time.  Always set the unused speed ...";
CM_ SG_ 2566686974 SpdCmd "The speed commanded to the Fuel Cell Coolant Pump 2.
Note:  Both Fuel Cell Coolant Pump 2 Speed Command and Fuel Cell Coolant Pump 2 Percent Speed Command cannot be used at the same time.  Always set the unused speed command to Not Available.  If ...";
CM_ BO_ 2566686718 "Fuel Cell Coolant Pump 1 Command
The command message to the Fuel Cell Coolant Pump 1.

Note: See PGN 64649 (Fuel Cell Coolant Pump 1 Status) for corresponding status message.";
CM_ SG_ 2566686718 EnableCmd "Indicates the enable and direction command to the Fuel Cell Coolant Pump 1.

00b = Motor Off
01b = Motor On Normal/Default Direction
10b = Motor On Reverse Direction
11b = Don't Care/Take no action";
CM_ SG_ 2566686718 PercentSpdCmd "The speed commanded to the Fuel Cell Coolant Pump 1  in percentage of maximum speed.
Note: Both Fuel Cell Coolant Pump 1 Speed Command and Fuel Cell Coolant Pump 1 Percent Speed Command cannot be used at the same time.  Always set the unused speed ...";
CM_ SG_ 2566686718 SpdCmd "The speed commanded to the fuel cell coolant pump 1.
Note:  Both Fuel Cell Coolant Pump 1 Speed Command and Fuel Cell Coolant Pump 1 Percent Speed Command cannot be used at the same time.  Always set the unused speed command to Not Available.  If ...";
CM_ BO_ 2566686462 "Fuel Cell Auxiliary Heater Information
Contains the Fuel Cell Auxiliary Heater Information.";
CM_ SG_ 2566686462 InputVLvl "Indicates the input DC voltage to the fuel cell auxilary heater.";
CM_ SG_ 2566686462 InputCurLvl "Indicates the input DC current to the fuel cell auxilary heater.";
CM_ SG_ 2566686462 OutCoolantTemp "Indicates the temperature of the fuel cell auxiliary heater output coolant (I.e. water in a water heater system.)";
CM_ SG_ 2566686462 OutPwrPercent "Indicates the current fuel cell auxiliary heater output power, relative to the fuel cell auxiliary heater maximum output power.
Note: See SPN 21315 (Fuel Cell Auxiliary Heater Power Percent Command) for Fuel Cell Auxiliary Heater Power Percent ...";
CM_ SG_ 2566686462 Mode "Indicates the state of the fuel cell auxiliary heater
0000b = Heater not active
0001b = Economy mode
0010b = Normal mode
0011b = Heater pump up-keep   (running the equipment in order to keep it in good condition)
0100b = Heater Starting - ...";
CM_ BO_ 2566686206 "Fuel Cell Auxiliary Heater Control
The command message to the Fuel Cell Auxiliary Heater.";
CM_ SG_ 2566686206 OutCoolantTempSp "This parameter indicates the setpoint temperature of the fuel cell auxiliary heater output coolant (i.e. water in a water heater system.)";
CM_ SG_ 2566686206 PwrPercentCmd "This parameter indicates the commanded fuel cell auxillary heater output power in percentage, relative to the fuel cell auxiliary heater maximum output power.
Note: See SPN 21318 (Fuel Cell Auxiliary Heater Output Power Percent) for the Fuel Cell ...";
CM_ SG_ 2566686206 ModeReq "This is the request to activate the fuel cell auxiliary heater.
0000b = De-activate fuel cell auxiliary heater
0001b = Economy mode
0010b = Normal mode
0011b = Heater pump up-keep (run the equipment in order to keep it in good condition)
0100b ...";
CM_ BO_ 2566675710 "Synchronized Service Delay/Calendar Time Based Information
Transmitted with all the service component identification values that have the  nearest time in weeks until the next service inspection. Along with the component identifier with nearest ...";
CM_ SG_ 2566675710 Component3Identifier "Identification of the component needing service. This parameter indicates each components needing to be serviced based on SPN 21204 (Synchronized Service Delay/Calendar Time).
Component values are defined in Table SPN911_A of Appendix D in ...";
CM_ SG_ 2566675710 SyncSvcDelay_CalendarTime "The parameter indicates the synchronized time in weeks until the next vehicle service inspection is required. If the service inspection has passed, a negative time is transmitted. A service time that has exceeded the data range is saturated to the ...";
CM_ BO_ 2566675454 "Synchronized Service Delay/Operational Time Based Information
Transmitted with all the service component identification values that have the nearest time in hours until the next service inspection. Along with the component identifier with nearest ...";
CM_ SG_ 2566675454 Component2Identifier "Identification of the component needing service. This parameter indicates each component needing to be serviced based on SPN 21202 (Synchronized Service Delay/Operational Time).
Component values are defined in Table SPN911_A of Appendix D in ...";
CM_ SG_ 2566675454 SyncSvcDelay_OperationalTime "The parameter indicates the vehicle operational time until the next service inspection is required. If the service inspection has passed, a negative time is transmitted. A service time that has exceeded the data range is saturated to the minimum or ...";
CM_ BO_ 2566675198 "Synchronized Service Distance Information
Transmitted with all the service component identification values that have the shortest distance until the next service inspection. Along with the service component identifier with shortest distance to the ...";
CM_ SG_ 2566675198 Component1Identifier "Identification of the component needing service. This parameter indicates each component needing to be serviced based on SPN 21200 (Synchronized Service Distance).  Component values are defined in Table SPN911_A of Appendix D in Supporting ...";
CM_ SG_ 2566675198 SyncSvcDist "The parameter indicates the synchronized distance until the next vehicle service inspection is required. If the service inspection has passed, a negative distance is transmitted. A service distance that has exceeded the data range is saturated to ...";
CM_ BO_ 2566539774 "Park Assist
Contains park assist information for the vehicle. This may include any such technology that provides vehicle parking support, i.e. radar, ultrasonic, or camera-based.";
CM_ SG_ 2566539774 RearParkAssistSt "Indicates the status of the Rear Park Assist system. Park Assist systems detect objects during low velocity movement and typically utilize ultrasonics, radar, or cameras.
000b = Off - Park assist is not enabled
001b = Standby - Park assist is ...";
CM_ SG_ 2566539774 FrontParkAssistSt "Indicates the status of the Front Park Assist system. Park Assist systems detect objects during low velocity movement and typically utilize ultrasonics, radar, or cameras.
000b = Off - Park assist is not enabled
001b = Standby - Park assist is ...";
CM_ BO_ 2566539518 "Steering Wheel Controls
Contains steering wheel button press information.";
CM_ SG_ 2566539518 CtrlPushToTalkSw "Status of the Steering Wheel Push To Talk Switch.

00b = Released (Off)
01b = Pressed (On)
10b = Error
11b = Not Available";
CM_ SG_ 2566539518 CtrlVoiceCommunicationSw "Status of the Steering Wheel Voice Communication Control Switch.

00b = Released (Off)
01b = Pressed (On)
10b = Error
11b = Not Available";
CM_ SG_ 2566539518 CtrlCallEndSw "Indicates the status of the steering wheel call end switch. This button is used to end an ongoing call or to mute entertainment (non-call) audio in some cases.

00b = Released (Off)
01b = Pressed (On)
10b = Error
11b = Not Available";
CM_ SG_ 2566539518 CtrlVolumeDownSw "Indicates the status of the steering wheel volume down switch. This switch controls the volume of the audio that is actively playing.

00b = Released (Off)
01b = Pressed (On)
10b = Error
11b = Not Available";
CM_ SG_ 2566539518 CtrlVolumeUpSw "Indicates the status of the steering wheel volume up switch. This switch controls the volume of the audio that is actively playing.

00b = Released (Off)
01b = Pressed (On)
10b = Error
11b = Not Available";
CM_ SG_ 2566539518 CtrlPreviousSw "Indicates the state of the steering wheel previous switch button. This will typically cycle to the previous favorite, station, or song that is currently providing audio.

00b = Released (Off)
01b = Pressed (On)
10b = Error
11b = Not Available";
CM_ SG_ 2566539518 CtrlNextSw "Indicates the state of the steering wheel next switch button. This will typically cycle to the next favorite, station, or song that is currently providing audio.

00b = Released (Off)
01b = Pressed (On)
10b = Error
11b = Not Available";
CM_ BO_ 2566539262 "Engine Fuel Actuator Service Mode
Used to command fuel control actuator service modes.";
CM_ SG_ 2566539262 TwoSvcModeReq "Intended for applications where SPN 1244 represents a flow command, to request that the fuel actuator enter a service mode of operation in which SPN 1244 is interpreted as a position command instead of a flow command. If the device supports and ...";
CM_ SG_ 2566539262 OneSvcModeReq "Intended for applications where SPN 633 represents a flow command, to request that the fuel actuator enter a service mode of operation in which SPN 633 is interpreted as a position command instead of a flow command. If the device supports and enters ...";
CM_ BO_ 2566539006 "Security System Machine Operation Information
Contains parameters related to the security system machine operation.
For example, this PG can be used by a security system or an anti-theft device to indicate to a display or other user interface that ...";
CM_ SG_ 2566539006 St "Indicates Machine Operation Status as commanded by a security system or anti-theft device.
A status of Normal Operation means that the security system or anti-theft device is not preventing or limiting machine operation in any way (however, there ...";
CM_ SG_ 2566539006 LmtReason "Indicates the reason for the security system to limit machine operation.
This SP can be used to indicate the reason that the machine operation is currently or actively Limited. The SP can also be used to indicate the reason for the machine ...";
CM_ SG_ 2566539006 DisReason "Indicates the reason for the Security System to Disable Machine Operation.
This SP can be used to indicate the reason that the machine operation is currently or actively disabled. The SP can also be used to indicate the reason for the machine ...";
CM_ SG_ 2566539006 TimeToLmtMachineOp "Indicates amount of time until the security system limits machine operation.
For example, if there is a condition that if not resolved, will result in the machine operation becoming limited in some way, this SP may be used to indicate how much time ...";
CM_ SG_ 2566539006 TimeToDisMachineOp "Indicates amount of time until the security system disables machine operation.
For example, if there is a condition that if not resolved, will result in the machine operation becoming disabled, this SP may be used to indicate how much time is ...";
CM_ BO_ 2365212158 "Generator Trip Energy 2
Contains additional quantities for the \"trip\" energy from the generator.";
CM_ SG_ 2365212158 KVArHoursImport "The trip AC reactive energy imported by the generator since the last reset of the trip kVArh meter.

This value will be reset by the user at will.";
CM_ BO_ 2566538494 "Engine Speed/Load Factor Information 2
Used to transmit Engine Load Factor Information.";
CM_ SG_ 2566538494 TotalAvgLoadFactor "Indicates the average engine load factor while engine speed is greater than zero, over the life of the engine. Engine operation during cruise control operation is included.
Note: See SPN 1016 for Total Drive Average Load Factor and Marine ...";
CM_ SG_ 2566538494 TripAvgLoadFactor "Indicates the average engine load factor while engine speed is greater than zero, since last trip reset. Engine operation during cruise control operation is included.

Note: See SPN 1015 for Trip Drive Average Load Factor and Marine applications.";
CM_ BO_ 2499429374 "Hybrid System Inputs 2
This message can be sent by any controller that has hybrid system related information";
CM_ SG_ 2499429374 TotalRegenerativeBrakingLvl "Indicates the total regenerative braking level requested by the operator. It is expressed as a percent and determined by the ratio of current position to the maximum possible position. The physical device may be a lever, rotary dial, combination of ...";
CM_ BO_ 2566537982 "Automated Driving System Network Configuration 1
Sent by a controller application to report the detected automated driving system network configuration. This parameter group is transmitted with up to two unique identifiers for up to four ADS ...";
CM_ SG_ 2566537982 Ctrl4Id2 "This parameter represents the second unique identifier of ADS controller 4 detected by the controller application which is under control of an automated driving system.
NOTE - The ASCII character \"*\" is reserved as a delimiter.
The following SPs ...";
CM_ SG_ 2566537982 Ctrl4Id1 "This parameter represents the first unique identifier of ADS controller 4 detected by the controller application which is under control of an automated driving system.
NOTE - The ASCII character \"*\" is reserved as a delimiter.
The following SPs ...";
CM_ SG_ 2566537982 Ctrl3Id2 "This parameter represents the second unique identifier of ADS controller 3 detected by the controller application which is under control of an automated driving system.
NOTE - The ASCII character \"*\" is reserved as a delimiter.
The following SPs ...";
CM_ SG_ 2566537982 Ctrl3Id1 "This parameter represents the first unique identifier of ADS controller 3 detected by the controller application which is under control of an automated driving system.
NOTE - The ASCII character \"*\" is reserved as a delimiter.
The following SPs ...";
CM_ SG_ 2566537982 Ctrl2Id2 "This parameter represents the second unique identifier of ADS controller 2 detected by the controller application which is under control of an automated driving system.
NOTE - The ASCII character \"*\" is reserved as a delimiter.
The following SPs ...";
CM_ SG_ 2566537982 Ctrl2Id1 "This parameter represents the first unique identifier of ADS controller 2 detected by the controller application which is under control of an automated driving system.
NOTE - The ASCII character \"*\" is reserved as a delimiter.
The following SPs ...";
CM_ SG_ 2566537982 Ctrl1Id2 "This parameter represents the second unique identifier of the ADS controller 1 detected by the controller application which is under control of an automated driving system.
NOTE - The ASCII character \"*\" is reserved as a delimiter.
The following ...";
CM_ SG_ 2566537982 Ctrl1Id1 "This parameter represents the first unique identifier of ADS Controller 1 detected by the controller application which is under control of an automated driving system.
NOTE - The ASCII character \"*\" is reserved as a delimiter.
The following SPs ...";
CM_ BO_ 2566537726 "Automated Driving System Network Configuration 2
Sent by a controller application to report the  detected automated driving system network configuration.";
CM_ SG_ 2566537726 SAOfCtrl4 "This parameter indicates the source address of ADS controller 4 detected by the controller application which is under control of an automated driving system.
254 (FEh) indicates this parameter is supported, but ADS Controller 4 is not Identified.
 ...";
CM_ SG_ 2566537726 ReceivePortOfCtrl4 "This parameter indicates the communication port of the ADS Controller 4.  The identification of each ECU communication port is ECU specific. The correlation of ECU communication port to a physical network connection is ECU specific. Users of this ...";
CM_ SG_ 2566537726 ReceivePortOfCtrl3 "This parameter indicates the communication port of the ADS Controller 3.  The identification of each ECU communication port is ECU specific. The correlation of ECU communication port to a physical network connection is ECU specific. Users of this ...";
CM_ SG_ 2566537726 SAOfCtrl3 "This parameter indicates the source address of ADS controller 3 detected by the controller application which is under control of an automated driving system.
254 (FEh) indicates this parameter is supported, but ADS Controller 3 is not Identified.
 ...";
CM_ SG_ 2566537726 SAOfCtrl2 "This parameter indicates the source address of ADS controller 2 detected by the controller application which is under control of an automated driving system.
254 (FEh) indicates this parameter is supported, but ADS Controller 2 is not Identified.
 ...";
CM_ SG_ 2566537726 ReceivePortOfCtrl2 "This parameter indicates the communication port of the ADS Controller 2.  The identification of each ECU communication port is ECU specific. The correlation of ECU communication port to a physical network connection is ECU specific. Users of this ...";
CM_ SG_ 2566537726 ReceivePortOfCtrl1 "This parameter indicates the communication port of the ADS Controller 1.  The identification of each ECU communication port is ECU specific. The correlation of ECU communication port to a physical network connection is ECU specific. Users of this ...";
CM_ SG_ 2566537726 SAOfCtrl1 "This parameter indicates the source address of ADS controller 1 detected by the controller application which is under control of an automated driving system.
254 (FEh) indicates this parameter is supported, but ADS Controller 1 is not Identified.
 ...";
CM_ BO_ 2365210878 "Electronic Transmission Controller 15
Electronic Transmission Controller 15";
CM_ SG_ 2365210878 AutoNeutralFunctionSt "Indicates the state of the Transmission Auto-Neutral (Auto-Return) function in relation to the state indicated in SPN 21253 [Transmission Auto-Neutral (Auto-Return) Request Feedback]. The applicability of the states and state transitions depend on ...";
CM_ SG_ 2365210878 AutoNeutralReqFeedback "This parameter reflects the state of SPN 21252 [Transmission Auto-Neutral (Auto-Return) Request] that the transmission is currently acting upon.
000b = Responding to: No request
001b = Responding to: Request to shift to (or maintain) Auto-Neutral ...";
CM_ SG_ 2365210878 Ctrl15Counter "The message counter is used to detect situations where the transmitting ECU malfunction repeats the same frame all the time. The receiver of the information may use the counter parameter to detect this situation. The transmitting device will ...";
CM_ SG_ 2365210878 Ctrl15CRC "The CRC is defined as follows:
• Length: 8 bits
• Polynomial: x^8+x^5+x^3+x^2+x+1
• Initial Value: FFh
• Input Data Reflection: Not reflected
• Result Data Reflection: Not reflected
• XOR value: FFh
SAE makes no claim of the functional safety ...";
CM_ BO_ 2566081022 "Fuel Cell Compartment Information
Contains the Fuel Cell Compartment Information.";
CM_ SG_ 2566081022 HydrogenConcentration "This parameter indicates the hydrogen concentration measured inside the Fuel Cell Compartment.
Note: A Fuel Cell Compartment can contain one or more Fuel Cell Enclosures. See SPN 21336 (Fuel Cell Enclosure 1 Hydrogen Concentration) and SPN 21337 ...";
CM_ SG_ 2566081022 Enclosure2HydrogenConcentration "This parameter indicates the hydrogen concentration measured inside the Fuel Cell Enclosure 2 in the Fuel Cell Compartment
Note: A Fuel Cell Enclosure can contain one or more Fuel Cell Stack.
Parameter Specific Indicator:  A value of FBh indicates ...";
CM_ SG_ 2566081022 Enclosure1HydrogenConcentration "This parameter indicates the hydrogen concentration measured inside the Fuel Cell Enclosure 1 in the Fuel Cell Compartment
Note: A Fuel Cell Enclosure can contain one or more Fuel Cell Stack.
Parameter Specific Indicator:  A value of FBh indicates ...";
CM_ BO_ 2364754174 "Genset Reactive Power
Contains control information for the status, power and reactive power for generator grid code control functions.
These parameters are intended for stationary Generator/Engine components, not mobile applications.  See ...";
CM_ SG_ 2364754174 CtrlAtLowLoadSt "Indicates when the reactive power control feature is within limits.

00b = Not within limits
01b = Within limits
10b = Error / function disabled
11b = Not available";
CM_ SG_ 2364754174 ModeSelectionDigitalInput4St "For a generator system, there are several possible digital input sources for reactive power demand. This parameter is used to indicate when the digital input 4 of the reactive power mode selection is active.
00b = Inactive
01b = Active
10b = ...";
CM_ SG_ 2364754174 ModeSelectionDigitalInput3St "For a generator system, there are several possible digital input sources for reactive power demand. This parameter is used to indicate when the digital input 3 of the reactive power mode selection is active.
00b = Inactive
01b = Active
10b = ...";
CM_ SG_ 2364754174 ModeSelectionDigitalInput2St "For a generator system, there are several possible digital input sources for reactive power demand. This parameter is used to indicate when the digital input 2 of the reactive power mode selection is active.
00b = Inactive
01b = Active
10b = ...";
CM_ SG_ 2364754174 ModeSelectionDigitalInput1St "For a generator system, there are several possible digital input sources for reactive power demand. This parameter is used to indicate when the digital input 1 of the reactive power mode selection is active.
00b = Inactive
01b = Active
10b = ...";
CM_ SG_ 2364754174 UtilOpReactivePwrSpSource "For a generator system there are several possible sources or inputs for reactive power demand.  This parameter is used to indicate the source requested by the utility operator that that is to actively control the generator control system reactive ...";
CM_ SG_ 2364754174 UtilSyncronizationSt "For a generator system there are multiple possible statuses that the generator is allowed to synchronize with the electrical utility grid.
0000b = Permission granted
0001b = Waiting for external signal
0010b = Voltage or frequency outside of ...";
CM_ SG_ 2364754174 UtilSycronizationDelTime "Time before the generator system will attempt to synchronize with the electrical utility grid.";
CM_ SG_ 2364754174 Sp "Desired reactive power for the generator control system as a percentage of generator rated reactive power.";
CM_ SG_ 2364754174 ActiveLmtSource "For a generator system there are multiple possible sources or inputs that can limit the reactive power limitation. This parameter is used to indicate the source of the Generator Control System reactive power limit.
0000b = None
0001b = ...";
CM_ SG_ 2364754174 ActiveSpSource "For a generator system there are multiple possible sources or inputs for reactive power demand. This parameter is used to indicate the source that the Generator Control System is actively controlling reactive power.
0000b = None
0001b = Power ...";
CM_ BO_ 2364753918 "Genset Real Power Control
Contains control information for the status, power and reactive power for generator grid code control functions.
These parameters are intended for stationary Generator/Engine components, not mobile applications.  See ...";
CM_ SG_ 2364753918 PrimRealPwrOffsetRampRateSource "Used to indicate the source that the Generator Control is actively controlling the real power ramp rate offset.
000b = None
001b = Frequency Sensitive Mode Increase
010b = Frequency Sensitive Mode Decrease
011b = Reserved
100b = Reserved
101b ...";
CM_ SG_ 2364753918 PrimRealPwrActiveSpOffsetSource "For a generator system there are multiple possible sources or inputs for real power offsets. This parameter is used to indicate the source that the Generator Control System is actively controlling real power offset.
000b = None
001b = Frequency ...";
CM_ SG_ 2364753918 IncreaseRampRateSp "Real power desired ramp rate that the generator control system will use to increase power.";
CM_ SG_ 2364753918 SpPct "Desired real power for the generator control system as a percentage of generator rated power.";
CM_ SG_ 2364753918 RampRateSource "For a generator system there are multiple possible sources or inputs for real power ramp rates. This parameter is used to indicate the source that the Generator Control System is actively controlling real power ramp rate too.
0000b = Genset ...";
CM_ SG_ 2364753918 ActiveSpSource "For a generator system there are multiple possible sources or inputs for real power demand. This parameter is used to indicate the source that the Generator Control System is actively controlling real power.
0000b = Genset Operator
0001b = Service ...";
CM_ SG_ 2364753918 DecreaseRampRateSp "Real power desired ramp rate that the generator control system will use to decrease power.";
CM_ BO_ 2364753662 "Genset Power Limitation
Contains control information for the status, power and reactive power for generator grid code control functions.";
CM_ SG_ 2364753662 RealPwrRampRateLmtSt "Indicates when the Ramp Rate Limitation is limiting the real power ramp rate.

00b = Not Actively Limiting
01b = Actively Limiting
10b = Error
11b = Not available";
CM_ SG_ 2364753662 RealPwrRampRateLmtEnableSt "Indicates when the Real Power Ramp Rate Limit is enabled.

00b = Disabled
01b = Enabled
10b = Error
11b = Not available";
CM_ SG_ 2364753662 UtilOpRealPwrExportLmtSp4St "Indicates when the electrical utility operator is limiting the generator output power for Setpoint 4.

00b = Not Actively Limiting
01b = Actively Limiting
10b = Error
11b = Not available";
CM_ SG_ 2364753662 UtilOpRealPwrExportLmtSp3St "Indicates when the electrical utility operator is limiting the generator output power for Setpoint 3.

00b = Not Actively Limiting
01b = Actively Limiting
10b = Error
11b = Not available";
CM_ SG_ 2364753662 UtilOpRealPwrExportLmtSp2St "Indicates when the electrical utility operator is limiting the generator output power for Setpoint 2.

00b = Not Actively Limiting
01b = Actively Limiting
10b = Error
11b = Not available";
CM_ SG_ 2364753662 UtilOpRealPwrExportLmtSp1St "Indicates when the electrical utility operator is limiting the generator output power for Setpoint 1.

00b = Not Actively Limiting
01b = Actively Limiting
10b = Error
11b = Not available";
CM_ SG_ 2364753662 UtilParVRealPwrCurveSt "Indicates when the Utility Parallel Voltage Real-Power Control Curve is active.

00b = Inactive
01b = Active
10b = Error
11b = Not available";
CM_ SG_ 2364753662 UtilOpRealPwrExportLmtSt "Indicates when the electrical utility operator is limiting the generator output power. Disabled indicates that the limiting feature is not turned on.

00b = Inactive
01b = Active
10b = Error
11b = Not available";
CM_ SG_ 2364753662 UtilParVRealPwrCurveSpPct "Generator real power setpoint as a percentage based on the active voltage defined by the voltage-real power control curve.";
CM_ SG_ 2364753662 UtilOpRealPwrExportLmtPct "Utility operator real power maximum setpoint for the generator output power percentage";
CM_ BO_ 2364753406 "Genset Frequency Limitation
Contains control information for the status, power and reactive power for generator grid code control functions.
These parameters are intended for stationary Generator/Engine components, not mobile applications.  See ...";
CM_ SG_ 2364753406 SensModeEnableSt "Indicates when the Frequency Sensitive Mode is enabled.

00b = Disabled
01b = Enabled
10b = Error
11b = Not Available";
CM_ SG_ 2364753406 LimFSMOfEnableStDeactThldResetSt "Indicates the request for the deactivation threshold control that prevents the genset from changing real power when the measured frequency changes while in Limited Frequency Sensitive Mode.
00b = Reset not requested
01b = Reset requested
10b = ...";
CM_ SG_ 2364753406 LimFSMUfSt "Indicates the enable status of the feature that allows Limited Frequency Sensetive Mode to function normally when the frequency of the system exceeds the limit.

00b = Disabled
01b = Enabled
10b = Error
11b = Not Available";
CM_ SG_ 2364753406 LimFSMOfEnableSt "Indicates the enable status of the feature that allows Limited Frequency Sensetive Mode to function normally when the frequency of the system exceeds the threshold.

00b = Disabled
01b = Enabled
10b = Error
11b = Not Available";
CM_ SG_ 2364753406 SensitiveModeSt "Indicates when the Frequency Sensitive Mode is active.

00b = Inactive
01b = Active
10b = Error
11b = Not available";
CM_ SG_ 2364753406 LimFreqSensitiveModeSt "Indicates when the Limited Frequency Sensitive Mode is active.

00b = Inactive
01b = Active
10b = Error
11b = Not available";
CM_ SG_ 2364753406 GeneratorFreqOffsetSp "Provides a frequency offset that is added to the measured utility frequency.";
CM_ SG_ 2364753406 SensitiveModeRealPwrSp "Desired Generator real power setpoint based on the active frequency defined by the Frequency Sensitive Mode control curve.";
CM_ SG_ 2364753406 LimFreqSensitiveModeRealPwrSp "Desired Generator real power setpoint based on the active frequency defined by the Limited Frequency Sensitive Mode control curve.";
CM_ BO_ 2566079742 "Electronic Park Brake Controller 2
Electronic Park Brake system output, control, and interface information";
CM_ SG_ 2566079742 ActiveExtlInhAntiRollAway "Indicates external inhibit Anti-Roll-Away is executed by the EPB (Electronic Park Brake) system.
 
00b = No external inhibit Anti-Roll-Away being executed
01b = External EPB Inhibit Anti-Roll-Away being executed
10b = Error
11b = Not Available";
CM_ SG_ 2566079742 AntiRollAwayReqSysStInh "Indicates if external control of EPB (Electronic Park Brake) is allowed for Inhibit Anti-Roll-Away.
00b = External EPB Inhibit Anti-Roll-Away will not be accepted
01b = External EPB Inhibit Anti-Roll-Away will be accepted
10b = Error
11b = Not ...";
CM_ SG_ 2566079742 TransNeutralReqSt "Status of Transmission Neutral Request (TNR). Will communicate the state of the EPB (Electronic Park Brake) system requesting that the vehicle transmission be placed in neutral if the parking brake is applied when the vehicle transmission is not in ...";
CM_ SG_ 2566079742 ParkAtSpdExtlBrkReqSt "Status of Park-at-Speed (PAS) External Brake Request (XBR). Will communicate the state of the EPB (Electronic Park Brake) system requesting that the vehicle service brakes be applied.
00b = EPB is not executing external Park-at-Speed service brake ...";
CM_ SG_ 2566079742 ActiveExtlCtrlModeTowedUnit "Indicates which external control mode is executed by the EPB (Electronic Park Brake) system for the Towed Unit (PU).
0000b = No external Power Unit apply or release demand being executed
0001b = External EPB Power Unit apply demand being executed
 ...";
CM_ SG_ 2566079742 ActiveExtlCtrlModePwrUnit "Indicates which external control mode is executed by the EPB (Electronic Park Brake) system for the Power Unit (PU).
0000b = No external Power Unit apply or release demand being executed
0001b = External EPB Power Unit apply demand being executed
 ...";
CM_ SG_ 2566079742 ExtlReqSysStTowedUnitEvacuate "Indicates when external control of EPB (Electronic Park Brake) is allowed for the Towed Unit (TU) evacuate.
00b = External EPB Towed Unit Evacuate will not be accepted
01b = External EPB Towed Unit Evacuate will be accepted
10b = Reserved
11b = ...";
CM_ SG_ 2566079742 ExtlReqSysStTowedUnitSupply "Indicates when external control of EPB (Electronic Park Brake) is allowed for the Towed Unit (TU) supply.
00b = External EPB Towed Unit Supply will not be accepted
01b = External EPB Towed Unit Supply will be accepted
10b = Reserved
11b = Not ...";
CM_ SG_ 2566079742 ExtlReqSysStPwrUnitRelease "Indicates when external control of EPB (Electronic Park Brake) is allowed for the Power Unit (PU) release.
00b = External EPB Power Unit Release will not be accepted
01b = External EPB Power Unit Release will be accepted
10b = Reserved
11b = Not ...";
CM_ SG_ 2566079742 ExtlReqSysStPwrUnitApply "Indicates when external control of EPB (Electronic Park Brake) is allowed for the Power Unit (PU) apply
00b = External EPB Power Unit Apply will not be accepted
01b = External EPB Power Unit Apply will be accepted
10b = Reserved
11b = Not ...";
CM_ SG_ 2566079742 TowedUnitCircAirPress "The pneumatic pressure in the trailer supply circuit as reported by the EPB (Electronic Park Brake) system.";
CM_ SG_ 2566079742 PwrUnitCircAirPress "The pneumatic pressure in the park brake circuit as reported by the EPB (Electronic Park Brake) system.";
CM_ SG_ 2566079742 TowedUnitCtrlAirPress "The pneumatic pressure in the control portion of the trailer supply circuit as reported by the EPB (Electronic Park Brake) system.";
CM_ SG_ 2566079742 PwrUnitCtrlAirPress "The pneumatic pressure in the control portion of the park brake circuit as reported by the EPB (Electronic Park Brake) system.";
CM_ BO_ 2566079486 "Electronic Park Brake Controller 1
Electronic Park Brake system control air status, mode status, and interlock status.";
CM_ SG_ 2566079486 TowedUnitSwSt "EPB (Electronic Park Brake) system user input for park and unpark for the Towed Unit (TU).
000b = Neutral Position
001b = Apply Park Brake Position - Driver Request Not Honored
010b = Apply Park Brake Position - Driver Request Honored
011b = ...";
CM_ SG_ 2566079486 PwrUnitSwSt "EPB (Electronic Park Brake) system user input for park and unpark for the Power Unit (PU).
000b = Neutral Position
001b = Apply Park Brake Position - Driver Request Not Honored
010b = Apply Park Brake Position - Driver Request Honored
011b = ...";
CM_ SG_ 2566079486 AntiRollAwayTimer "Anti-Roll-Away (ARA) Countdown Timer.

Parameter Specific States:

F1h - ARA Trigger
F2h - ARA Acknowledgement Pending
F3h - Countdown Started
F4h - Countdown Paused
F5h - Countdown Not Started";
CM_ SG_ 2566079486 PwrSt "The EPB (Electronic Park Brake) system will send out the Entering Sleep Mode message before entering sleep mode.
000b = Normal
001b = Entering Sleep Mode
010b = Reserved
011b = Reserved
100b = Reserved
101b = Reserved
110b = Error
111b = Not ...";
CM_ SG_ 2566079486 ExhAtSpdSt "Status of Exhaust-at-Speed (EAS) dynamic function of the Electronic Park Brake (EPB) system. EAS can occur when an operator applies the parking brakes while the vehicle is in motion.  Parameters are configurable and can either make the driver hold ...";
CM_ SG_ 2566079486 TlrOvrdIlkDoor2St "Status of Door 2 Switch interlock override.  If this value is overriden, the EPB (Electronic Park Brake) system will not use it as interlock control for trailer unparking.
00b = EPB will not override door 2 switch interlock for trailer unparking
 ...";
CM_ SG_ 2566079486 TlrOvrdIlkDoor1St "Status of Door 1 Switch interlock override.  If this value is overriden, the EPB (Electronic Park Brake) system will not use it as interlock control for trailer unparking.
00b = EPB will not override door 1 switch interlock for trailer unparking
 ...";
CM_ SG_ 2566079486 TlrOvrdIlkSeatBeltSwSt "Status of Seat Belt Switch (SBS) interlock override.  If this value is overriden, the EPB (Electronic Park Brake) system will not use it as interlock control for trailer unparking.
00b = EPB will not override seat belt switch interlock for trailer ...";
CM_ SG_ 2566079486 TlrOvrdIlkIgntSt "Status of Ignition Switch Interlock override.  If this value is overriden, the EPB (Electronic Park Brake) system will not use it as interlock control for trailer unparking.
00b = EPB will not override ignition switch interlock for trailer ...";
CM_ SG_ 2566079486 TlrOvrdIlkSvcBrkSt "Status of Service Brake interlock override.  If this value is overriden, the EPB (Electronic Park Brake) system will not use it as interlock control for trailer unparking.
00b = EPB will not override service brake switch interlock for trailer ...";
CM_ SG_ 2566079486 OperatingMode "The EPB (Electronic Park Brake) system can be in various operating modes, depending on the state of the vehicle and available inputs.
0000b = Normal Mode - Intended for use during typical vehicle operation when all required interfaces with the EPB ...";
CM_ SG_ 2566079486 PwrUnitVehType "EPB (Electronic Park Brake) system configuration for Power Unit (PU) vehicle type. This is a configuration parameter.

00b = Towing (i.e. tractor)
01b = Non-Towing Straight Truck
10b = Non-Towing bus
11b = Error";
CM_ SG_ 2566079486 TlrBrkReleaseSt "Status of Trailer Brake Release (TBR) driver assistance function of the Electronic Park Brake (EPB) system. TBR can automatically charge the Towed Unit resulting in the trailer unparking in order to prevent a combination vehicle being driven with ...";
CM_ SG_ 2566079486 OccupancyAntiRollAwaySt "Status of Anti-Roll-Away (ARA) driver assistance feature in the Electronic Park Brake (EPB) system. ARA can automatically set the park brakes in order to mitigate potential vehicle rollaway events.
00b = Occupancy Anti-Roll-Away Passive.  EPB has ...";
CM_ SG_ 2566079486 TowedUnitCtrlAirSt "Status or control air pressure output to towed unit supply. While in the No Trailer Attached state, the EPB (Electronic Park Brake) system is indicating that it’s operating with behavior suitable for a towing vehicle which is not coupled to a Towed ...";
CM_ SG_ 2566079486 PwrUnitCtrlAirSt "Status of control air pressure output to power unit spring brake system.
000b = Exhausted
001b = Exhausting Pressure (Intermediate)
010b = Building Pressure (Intermediate)
011b = Charged
100b = Reserved
101b = Reserved
110b = Error
111b = ...";
CM_ BO_ 2566679038 "EV Operator Indicators 1
EV Operator Indicators";
CM_ SG_ 2566679038 HVESSEstRemainingDist "Estimated remaining distance based on existing available HVES system capacity.";
CM_ BO_ 2365332478 "HVESS Thermal Management System Control 2
Control commands to be sent to High Voltage Energy Storage System (or Pack 1 in systems with only one pack).";
CM_ SG_ 2365332478 CompressorPercentSpdCmd "Speed command to HVESS Thermal Management Compressor Speed  in percentage of maximum speed.
Note: Both SPN 20462 (HVESS Thermal Management System Compressor Speed Command) and SPN 20463 (HVESS Thermal Management System Compressor Percent Speed ...";
CM_ SG_ 2365332478 CompressorSpdCmd "Speed command to HVESS Thermal Management Compressor Speed.
Note: Both SPN 20462 (HVESS Thermal Management System Compressor Speed Command) and SPN 20463 (HVESS Thermal Management System Compressor Percent Speed Command) cannot be used at the same ...";
CM_ SG_ 2365332478 CPPercentSpdCmd "Speed command to HVESS Thermal Management Coolant Pump in percentage of maximum speed.
Note: Both SPN 20460 (HVESS Thermal Management System Coolant Pump Speed Command) and SPN 20461 (HVESS Thermal Management System Coolant Pump Percent Speed ...";
CM_ SG_ 2365332478 CPSpdCmd "Speed command to HVESS Thermal Management Coolant Pump.
Note: Both SPN 20460 (HVESS Thermal Management System Coolant Pump Speed Command) and SPN 20461 (HVESS Thermal Management System Coolant Pump Percent Speed Command) cannot be used at the same ...";
CM_ BO_ 2566658814 "HVESS Thermal Management System Control 1
Control requests to be sent to High Voltage Energy Storage System (or Pack 1 in systems with only one pack) Thermal Management System.";
CM_ SG_ 2566658814 CompressorEnableCmd "Command to enable HVESS Thermal Management Compressor.

00b = Compressor Off
01b = Compressor On
10b = Reserved
11b = Don't Care/Take no action";
CM_ SG_ 2566658814 CPEnableCmd "Command to enable and direction HVESS Thermal Management System Coolant Pump.

00b = Motor Off
01b = Motor On Normal/Default Direction
10b = Motor On Reverse Direction
11b = Don't Care/Take no action";
CM_ SG_ 2566658814 HtrEnableCmd "Command to enable HVESS Thermal Management heater.

00b = Disable Heater
01b = Enable Heater
10b = Reserved
11b = Don't Care/Take no action";
CM_ SG_ 2566658814 CoolantFlowRateReq "Parameter used to request the desired HVESS Thermal Management System coolant flow rate.";
CM_ SG_ 2566658814 OutCoolantTempReq "Parameter used to request the desired HVESS Thermal Management System Outlet Coolant Temperature.";
CM_ SG_ 2566658814 InletCoolantTempReq "Parameter used to request the desired HVESS Thermal Management System Inlet Coolant Temperature.";
CM_ BO_ 2566564606 "Electronic Auxiliary Transmission Controller 2
Electronic Auxiliary Transmission Controller 2";
CM_ SG_ 2566564606 CurGear "The gear currently engaged in the auxiliary transmission or the last gear engaged while the auxiliary transmission is in the process of shifting to the new or selected gear.  Transitions toward a destination gear will not be indicated.  Once the ...";
CM_ SG_ 2566564606 SelectedGear "The gear that the auxiliary transmission will attempt to achieve during the current shift if a shift is in progress, or the next shift if one is pending (i.e., waiting for torque reduction to initiate the shift).
Negative values are reverse gears, ...";
CM_ BO_ 2566564350 "Transmission Shaft Twist Information
Contains data relating to the twist levels on various transmission shafts.";
CM_ SG_ 2566564350 OneIntmdShaftPeakTwist "Indicates the maximum dynamic twist angle observed during a sample period for the first instance of a transmission 1 intermediate shaft, as designated by the transmission manufacturer. The broadcast value is always the largest twist displacement ...";
CM_ SG_ 2566564350 OneOutShaftPeakTwist "Indicates the maximum dynamic twist angle observed during a sample period for the transmission 1 output shaft. The broadcast value is always the largest twist displacement (regardless of positive or negative direction) observed during the last ...";
CM_ SG_ 2566564350 OneInputShaftPeakTwist "Indicates the maximum dynamic twist angle observed during a sample period for the transmission 1 input shaft. The broadcast value is always the largest twist displacement (regardless of positive or negative direction) observed during the last sample ...";
CM_ BO_ 2566564094 "Transmission 1 History
This message contains information of the operating history of the transmission.";
CM_ SG_ 2566564094 OpTimeSinceRebuild "The estimated or actual amount of transmission 1 operation time since the last transmission rebuild.";
CM_ SG_ 2566564094 TotalOutShaftRevolutions "Accumulated number of transmission 1 output shaft revolutions during its operation.";
CM_ SG_ 2566564094 TotalHoursOfOp "Accumulated time of transmission operation.";
CM_ BO_ 2566563838 "Dual Fuel Mode 1
Engine Dual Fuel Mode parameters";
CM_ SG_ 2566563838 EstCurDieselSavingsRatePct "Estimated instantaneous diesel fuel savings rate percentage while operating in blended dual fuel mode.
This value is calculated by dividing the Blended Dual Fuel Mode Estimated Instantaneous Diesel Savings Rate (SPN 15231) by engine fuel rate * ...";
CM_ SG_ 2566563838 DieselFuelPercentDisp "Percent of total diesel fuel displaced in a blended dual fuel application.

0% = No diesel fuel displaced. 100% = All amount of diesel fuel is being displaced.";
CM_ SG_ 2566563838 PercentTimeActive "The percentage of accumulated hours the engine has run in blended dual fuel mode.

This value is calculated by dividing dual fuel active time by engine run time * 100.";
CM_ SG_ 2566563838 TotalDieselFuelPercentDisp "Percent of total quantity of diesel fuel that was displaced by an engine when gaseous fuel was substituted for a portion of diesel fuel in blended dual fuel mode. This is calculated using total diesel fuel divided by total diesel fuel that would ...";
CM_ SG_ 2566563838 TotalDieselFuelUsed "Accumulated total amount of diesel fuel used by a dual fuel engine while fuel is being blended.

Use SPN 7597 for accumulated amount of actual diesel fuel used and the diesel fuel that was displaced by gaseous fuel.";
CM_ BO_ 2566563582 "Dual Fuel Mode 2
Engine Dual Fuel Mode parameters";
CM_ SG_ 2566563582 TotalDieselFuelDemand "Accumulated amount of liquid fuel that would have been used during engine operation, including actual diesel fuel used and the diesel fuel that was displaced by gaseous fuel.";
CM_ SG_ 2566563582 TotalDieselFuelDispByGasFuel "Accumulated total amount of diesel fuel displaced on blended dual fuel applications.";
CM_ BO_ 2566563326 "Dual Fuel Mode 3
Engine Dual Fuel Mode parameters";
CM_ SG_ 2566563326 StReason "Indicates the current status reason of the blended dual fuel mode while the engine is operating.
00000000b = Not Requested
00000001b = Diagnostic Trouble Code Active
00000010b = Engine Speed Too Low
00000011b = Engine Speed Too High
00000100b = ...";
CM_ SG_ 2566563326 OperatingSt "Indicates the current blended dual fuel mode operating state.
0000b = Disabled by Configuration
0001b = Operator Disabled
0010b = Automatically Disabled and Locked
0011b = Temporarily Disabled Due to Current Conditions
0100b = Pending
0101b = ...";
CM_ SG_ 2566563326 EstCurFuelSavingsRate "Estimated instantaneous fuel savings rate while operating in blended dual fuel mode.  This is in comparison to operating in diesel only mode.";
CM_ BO_ 2566563070 "Automated Driving System Control 2
Sent by the automated driving system.";
CM_ SG_ 2566563070 CRC "The CRC is defined as follows:
• Length: 8 bits
• Polynomial: x^8+x^5+x^3+x^2+x+1
• Initial Value: FFh
• Input Data Reflection: Not reflected
• Result Data Reflection: Not reflected
• XOR value: FFh
SAE makes no claim of the functional safety ...";
CM_ SG_ 2566563070 Counter "The message counter is used to detect situations where the transmitting ECU malfunction repeats the same frame all the time. The receiver of the information may use the counter parameter to detect this situation. The transmitting device will ...";
CM_ SG_ 2566563070 EmbeddedIntegritySupport "Indicates that SPN 22263 (ADSC2 CRC) and SPN 22262 (ADSC2 Counter) are supported by the sender.
00b = ADSC2 embedded CRC and Counter are supported by the sender
01b = ADSC2 protection is supported using J1939-76 SHM
10b = Reserved
11b = ADSC2 ...";
CM_ SG_ 2566563070 VSCtrlCmdPriority "This parameter is the priority of the ADS Vehicle Speed Control Command (SPN 15248). The recipient will honor the ADS Vehicle Speed Control Command with the highest priority when multiple ADSC2 messages are received. If multiple devices are sent ...";
CM_ SG_ 2566563070 VSCtrlCmd "Indicates the desired vehicle speed as commanded by the automated driving system (ADS).  ADS Vehicle Speed Control Command shall only be honored when ADS Vehicle Speed Control Consent (SPN 15247) is set to 01b.
Note: 0xFB00 denotes no vehicle speed ...";
CM_ BO_ 2566562814 "High Voltage Energy Storage Pack 26 Configuration
Configuration data for High Voltage Energy Storage Pack 26.  Note that configuration data should not dynamically change during vehicle operation.";
CM_ SG_ 2566562814 NomRatedCapacity "Per the HVES manufacturer, this is the manufacturer's nominal rated capacity of this instance of the energy storage system.  The rated capacity does not change over the life of the HVES.
This parameter is for one of multiple packs in an HVESS.  If ...";
CM_ SG_ 2566562814 CellMinVLmt "Per the HVES manufacturer, this is the minimum cell voltage for this High Voltage Energy Storage Pack instance operation.  Operating below this value may damage HVES hardware, or compromise HVES life.
This parameter is for one of multiple packs in ...";
CM_ SG_ 2566562814 CellMaxVLmt "Per the HVES manufacturer, this is the maximum cell voltage for this High Voltage Energy Storage Pack instance operation.  Operating above this value may damage HVES hardware, or compromise HVES life.
This parameter is for one of multiple packs in ...";
CM_ SG_ 2566562814 RecommendedMinOperatingTemp "Per the HVES manufacturer, this is the recommended minimum temperature for this High Voltage Energy Storage Pack instance operation.  Operating below this value may damage HVES hardware, or compromise HVES life.
This parameter is for one of ...";
CM_ SG_ 2566562814 RecommendedMaxOperatingTemp "Per the HVES manufacturer, this is the recommended maximum temperature for this High Voltage Energy Storage Pack instance operation.  Operating above this value may damage HVES hardware, or compromise HVES life.
This parameter is for one of ...";
CM_ SG_ 2566562814 RecommendedMaxStOfCharge "Per the HVES manufacturer, this is the recommended maximum state of charge for this High Voltage Energy Storage Pack instance operation.  Operating above this value may compromise HVES life.
This parameter is for one of multiple packs in an HVESS ...";
CM_ SG_ 2566562814 RecommendedMinStOfCharge "Per the HVES manufacturer, this is the recommended minimum state of charge for this High Voltage Energy Storage Pack instance operation.  Operating below this value may compromise HVES life.
This parameter is for one of multiple packs in an HVESS ...";
CM_ SG_ 2566562814 RecommendedMaxOperatingV "Per the HVES manufacturer, this is the maximum recommended voltage level for this High Voltage Energy Storage Pack instance operation.  Operating above this value may compromise HVES life.
This parameter is for one of multiple packs in an HVESS ...";
CM_ SG_ 2566562814 RecommendedMinOperatingV "Per the HVES manufacturer, this is the minimum recommended voltage level for this High Voltage Energy Storage Pack instance operation.  Operating below this value may compromise HVES life.
This parameter is for one of multiple packs in an HVESS ...";
CM_ SG_ 2566562814 NomV "Per the HVES manufacturer, this is the nominal operating voltage of this High Voltage Energy Storage Pack instance, e.g. “300V” or “600V”.
This parameter is for one of multiple packs in an HVESS.  If there is only one pack in the system, the HVESS ...";
CM_ BO_ 2633671422 "High Voltage Energy Storage Pack 26 History
Historical data for High Voltage Energy Storage Pack 26.";
CM_ SG_ 2633671422 TotalEnergyOut "The cumulative energy which has flowed out of this High Voltage Energy Storage Pack instance over the lifetime of the battery pack. This parameter is the sum of the Energy out of this HVES instance. This value is reset when the pack is replaced. For ...";
CM_ SG_ 2633671422 TotalEnergyInput "The cumulative energy which has flowed into this High Voltage Energy Storage Pack instance over the lifetime of the battery pack. This parameter is the sum of the Energy into this HVES instance.
This value is reset when the pack is replaced. For ...";
CM_ SG_ 2633671422 TotalAccumulatedCharge "The total accumulated amp hours which have flowed through this High Voltage Energy Storage Pack instance.  This parameter is the sum of the absolute values of the Ampere hours into and out of this HVES instance.
This parameter is for one of ...";
CM_ SG_ 2633671422 TotalEnergyThroughput "The total energy throughput which has flowed through this High Voltage Energy Storage Pack instance.  This parameter is the sum of the absolute values of the Energy into and out of this HVES instance.
This parameter is for one of multiple packs in ...";
CM_ SG_ 2633671422 ContactorOpenUnderLoadCount "This signal represents the number of times the contactors inside this High Voltage Energy Storage Pack instance have opened while current is flowing through them.  The current level (that determines if an opening event will be counted) shall be ...";
CM_ SG_ 2633671422 StOfHealth "This signal represents the expected remaining \"Life\" of this High Voltage Energy Storage Pack instance, in percent.  Battery life is a manufacturer-specific measure of how well the energy storage system is functioning relative to its nominal (rated) ...";
CM_ BO_ 2566562302 "High Voltage Energy Storage Pack 25 Configuration
Configuration data for High Voltage Energy Storage Pack 25.  Note that configuration data should not dynamically change during vehicle operation.";
CM_ SG_ 2566562302 NomRatedCapacity "Per the HVES manufacturer, this is the manufacturer's nominal rated capacity of this instance of the energy storage system.  The rated capacity does not change over the life of the HVES.
This parameter is for one of multiple packs in an HVESS.  If ...";
CM_ SG_ 2566562302 CellMinVLmt "Per the HVES manufacturer, this is the minimum cell voltage for this High Voltage Energy Storage Pack instance operation.  Operating below this value may damage HVES hardware, or compromise HVES life.
This parameter is for one of multiple packs in ...";
CM_ SG_ 2566562302 CellMaxVLmt "Per the HVES manufacturer, this is the maximum cell voltage for this High Voltage Energy Storage Pack instance operation.  Operating above this value may damage HVES hardware, or compromise HVES life.
This parameter is for one of multiple packs in ...";
CM_ SG_ 2566562302 RecommendedMinOperatingTemp "Per the HVES manufacturer, this is the recommended minimum temperature for this High Voltage Energy Storage Pack instance operation.  Operating below this value may damage HVES hardware, or compromise HVES life.
This parameter is for one of ...";
CM_ SG_ 2566562302 RecommendedMaxOperatingTemp "Per the HVES manufacturer, this is the recommended maximum temperature for this High Voltage Energy Storage Pack instance operation.  Operating above this value may damage HVES hardware, or compromise HVES life.
This parameter is for one of ...";
CM_ SG_ 2566562302 RecommendedMaxStOfCharge "Per the HVES manufacturer, this is the recommended maximum state of charge for this High Voltage Energy Storage Pack instance operation.  Operating above this value may compromise HVES life.
This parameter is for one of multiple packs in an HVESS ...";
CM_ SG_ 2566562302 RecommendedMinStOfCharge "Per the HVES manufacturer, this is the recommended minimum state of charge for this High Voltage Energy Storage Pack instance operation.  Operating below this value may compromise HVES life.
This parameter is for one of multiple packs in an HVESS ...";
CM_ SG_ 2566562302 RecommendedMaxOperatingV "Per the HVES manufacturer, this is the maximum recommended voltage level for this High Voltage Energy Storage Pack instance operation.  Operating above this value may compromise HVES life.
This parameter is for one of multiple packs in an HVESS ...";
CM_ SG_ 2566562302 RecommendedMinOperatingV "Per the HVES manufacturer, this is the minimum recommended voltage level for this High Voltage Energy Storage Pack instance operation.  Operating below this value may compromise HVES life.
This parameter is for one of multiple packs in an HVESS ...";
CM_ SG_ 2566562302 NomV "Per the HVES manufacturer, this is the nominal operating voltage of this High Voltage Energy Storage Pack instance, e.g. “300V” or “600V”.
This parameter is for one of multiple packs in an HVESS.  If there is only one pack in the system, the HVESS ...";
CM_ BO_ 2633670910 "High Voltage Energy Storage Pack 25 History
Historical data for High Voltage Energy Storage Pack 25.";
CM_ SG_ 2633670910 TotalEnergyOut "The cumulative energy which has flowed out of this High Voltage Energy Storage Pack instance over the lifetime of the battery pack. This parameter is the sum of the Energy out of this HVES instance. This value is reset when the pack is replaced. For ...";
CM_ SG_ 2633670910 TotalEnergyInput "The cumulative energy which has flowed into this High Voltage Energy Storage Pack instance over the lifetime of the battery pack. This parameter is the sum of the Energy into this HVES instance.
This value is reset when the pack is replaced. For ...";
CM_ SG_ 2633670910 TotalAccumulatedCharge "The total accumulated amp hours which have flowed through this High Voltage Energy Storage Pack instance.  This parameter is the sum of the absolute values of the Ampere hours into and out of this HVES instance.
This parameter is for one of ...";
CM_ SG_ 2633670910 TotalEnergyThroughput "The total energy throughput which has flowed through this High Voltage Energy Storage Pack instance.  This parameter is the sum of the absolute values of the Energy into and out of this HVES instance.
This parameter is for one of multiple packs in ...";
CM_ SG_ 2633670910 ContactorOpenUnderLoadCount "This signal represents the number of times the contactors inside this High Voltage Energy Storage Pack instance have opened while current is flowing through them.  The current level (that determines if an opening event will be counted) shall be ...";
CM_ SG_ 2633670910 StOfHealth "This signal represents the expected remaining \"Life\" of this High Voltage Energy Storage Pack instance, in percent.  Battery life is a manufacturer-specific measure of how well the energy storage system is functioning relative to its nominal (rated) ...";
CM_ BO_ 2566561790 "High Voltage Energy Storage Pack 24 Configuration
Configuration data for High Voltage Energy Storage Pack 24.  Note that configuration data should not dynamically change during vehicle operation.";
CM_ SG_ 2566561790 NomRatedCapacity "Per the HVES manufacturer, this is the manufacturer's nominal rated capacity of this instance of the energy storage system.  The rated capacity does not change over the life of the HVES.
This parameter is for one of multiple packs in an HVESS.  If ...";
CM_ SG_ 2566561790 CellMinVLmt "Per the HVES manufacturer, this is the minimum cell voltage for this High Voltage Energy Storage Pack instance operation.  Operating below this value may damage HVES hardware, or compromise HVES life.
This parameter is for one of multiple packs in ...";
CM_ SG_ 2566561790 CellMaxVLmt "Per the HVES manufacturer, this is the maximum cell voltage for this High Voltage Energy Storage Pack instance operation.  Operating above this value may damage HVES hardware, or compromise HVES life.
This parameter is for one of multiple packs in ...";
CM_ SG_ 2566561790 RecommendedMinOperatingTemp "Per the HVES manufacturer, this is the recommended minimum temperature for this High Voltage Energy Storage Pack instance operation.  Operating below this value may damage HVES hardware, or compromise HVES life.
This parameter is for one of ...";
CM_ SG_ 2566561790 RecommendedMaxOperatingTemp "Per the HVES manufacturer, this is the recommended maximum temperature for this High Voltage Energy Storage Pack instance operation.  Operating above this value may damage HVES hardware, or compromise HVES life.
This parameter is for one of ...";
CM_ SG_ 2566561790 RecommendedMaxStOfCharge "Per the HVES manufacturer, this is the recommended maximum state of charge for this High Voltage Energy Storage Pack instance operation.  Operating above this value may compromise HVES life.
This parameter is for one of multiple packs in an HVESS ...";
CM_ SG_ 2566561790 RecommendedMinStOfCharge "Per the HVES manufacturer, this is the recommended minimum state of charge for this High Voltage Energy Storage Pack instance operation.  Operating below this value may compromise HVES life.
This parameter is for one of multiple packs in an HVESS ...";
CM_ SG_ 2566561790 RecommendedMaxOperatingV "Per the HVES manufacturer, this is the maximum recommended voltage level for this High Voltage Energy Storage Pack instance operation.  Operating above this value may compromise HVES life.
This parameter is for one of multiple packs in an HVESS ...";
CM_ SG_ 2566561790 RecommendedMinOperatingV "Per the HVES manufacturer, this is the minimum recommended voltage level for this High Voltage Energy Storage Pack instance operation.  Operating below this value may compromise HVES life.
This parameter is for one of multiple packs in an HVESS ...";
CM_ SG_ 2566561790 NomV "Per the HVES manufacturer, this is the nominal operating voltage of this High Voltage Energy Storage Pack instance, e.g. “300V” or “600V”.
This parameter is for one of multiple packs in an HVESS.  If there is only one pack in the system, the HVESS ...";
CM_ BO_ 2633670398 "High Voltage Energy Storage Pack 24 History
Historical data for High Voltage Energy Storage Pack 24.";
CM_ SG_ 2633670398 TotalEnergyOut "The cumulative energy which has flowed out of this High Voltage Energy Storage Pack instance over the lifetime of the battery pack. This parameter is the sum of the Energy out of this HVES instance. This value is reset when the pack is replaced. For ...";
CM_ SG_ 2633670398 TotalEnergyInput "The cumulative energy which has flowed into this High Voltage Energy Storage Pack instance over the lifetime of the battery pack. This parameter is the sum of the Energy into this HVES instance.
This value is reset when the pack is replaced. For ...";
CM_ SG_ 2633670398 TotalAccumulatedCharge "The total accumulated amp hours which have flowed through this High Voltage Energy Storage Pack instance.  This parameter is the sum of the absolute values of the Ampere hours into and out of this HVES instance.
This parameter is for one of ...";
CM_ SG_ 2633670398 TotalEnergyThroughput "The total energy throughput which has flowed through this High Voltage Energy Storage Pack instance.  This parameter is the sum of the absolute values of the Energy into and out of this HVES instance.
This parameter is for one of multiple packs in ...";
CM_ SG_ 2633670398 ContactorOpenUnderLoadCount "This signal represents the number of times the contactors inside this High Voltage Energy Storage Pack instance have opened while current is flowing through them.  The current level (that determines if an opening event will be counted) shall be ...";
CM_ SG_ 2633670398 StOfHealth "This signal represents the expected remaining \"Life\" of this High Voltage Energy Storage Pack instance, in percent.  Battery life is a manufacturer-specific measure of how well the energy storage system is functioning relative to its nominal (rated) ...";
CM_ BO_ 2566561278 "High Voltage Energy Storage Pack 23 Configuration
Configuration data for High Voltage Energy Storage Pack 23.  Note that configuration data should not dynamically change during vehicle operation.";
CM_ SG_ 2566561278 NomRatedCapacity "Per the HVES manufacturer, this is the manufacturer's nominal rated capacity of this instance of the energy storage system.  The rated capacity does not change over the life of the HVES.
This parameter is for one of multiple packs in an HVESS.  If ...";
CM_ SG_ 2566561278 CellMinVLmt "Per the HVES manufacturer, this is the minimum cell voltage for this High Voltage Energy Storage Pack instance operation.  Operating below this value may damage HVES hardware, or compromise HVES life.
This parameter is for one of multiple packs in ...";
CM_ SG_ 2566561278 CellMaxVLmt "Per the HVES manufacturer, this is the maximum cell voltage for this High Voltage Energy Storage Pack instance operation.  Operating above this value may damage HVES hardware, or compromise HVES life.
This parameter is for one of multiple packs in ...";
CM_ SG_ 2566561278 RecommendedMinOperatingTemp "Per the HVES manufacturer, this is the recommended minimum temperature for this High Voltage Energy Storage Pack instance operation.  Operating below this value may damage HVES hardware, or compromise HVES life.
This parameter is for one of ...";
CM_ SG_ 2566561278 RecommendedMaxOperatingTemp "Per the HVES manufacturer, this is the recommended maximum temperature for this High Voltage Energy Storage Pack instance operation.  Operating above this value may damage HVES hardware, or compromise HVES life.
This parameter is for one of ...";
CM_ SG_ 2566561278 RecommendedMaxStOfCharge "Per the HVES manufacturer, this is the recommended maximum state of charge for this High Voltage Energy Storage Pack instance operation.  Operating above this value may compromise HVES life.
This parameter is for one of multiple packs in an HVESS ...";
CM_ SG_ 2566561278 RecommendedMinStOfCharge "Per the HVES manufacturer, this is the recommended minimum state of charge for this High Voltage Energy Storage Pack instance operation.  Operating below this value may compromise HVES life.
This parameter is for one of multiple packs in an HVESS ...";
CM_ SG_ 2566561278 RecommendedMaxOperatingV "Per the HVES manufacturer, this is the maximum recommended voltage level for this High Voltage Energy Storage Pack instance operation.  Operating above this value may compromise HVES life.
This parameter is for one of multiple packs in an HVESS ...";
CM_ SG_ 2566561278 RecommendedMinOperatingV "Per the HVES manufacturer, this is the minimum recommended voltage level for this High Voltage Energy Storage Pack instance operation.  Operating below this value may compromise HVES life.
This parameter is for one of multiple packs in an HVESS ...";
CM_ SG_ 2566561278 NomV "Per the HVES manufacturer, this is the nominal operating voltage of this High Voltage Energy Storage Pack instance, e.g. “300V” or “600V”.
This parameter is for one of multiple packs in an HVESS.  If there is only one pack in the system, the HVESS ...";
BA_DEF_ SG_  "GenSigInactiveValue" INT 0 0;
BA_DEF_ SG_  "SigType" ENUM  "Default","Range","RangeSigned","ASCII","Discrete","Control","ReferencePGN","DTC","StringDelimiter","StringLength","StringLengthControl","MessageCounter","MessageChecksum";
BA_DEF_ SG_  "GenSigStartValue" INT 0 2147483647;
BA_DEF_ SG_  "GenSigSendType" ENUM  "Cyclic","OnWrite","OnWriteWithRepetition","OnChange","OnChangeWithRepetition","IfActive","IfActiveWithRepetition","NoSigSendType";
BA_DEF_ SG_  "GenSigILSupport" ENUM  "No","Yes";
BA_DEF_ SG_  "SPN" INT 0 524287;
BA_DEF_ BO_  "J1939CPgSendTimeout" INT -1 3600000;
BA_DEF_ BO_  "J1939CPgTOS" INT 0 7;
BA_DEF_ BO_  "J1939PgAppearanceOnBus" ENUM  "Default","CAN_Extended","CANFD_Extended";
BA_DEF_ BO_  "FsJ1939UseCrcAndCounter" STRING ;
BA_DEF_ BO_  "TpJ1939VarDlc" ENUM  "No","Yes";
BA_DEF_ BO_  "GenMsgNrOfRepetition" INT 0 1000000;
BA_DEF_ BO_  "GenMsgCycleTimeFast" INT 0 3600000;
BA_DEF_ BO_  "GenMsgFastOnStart" INT 0 100000;
BA_DEF_ BO_  "GenMsgStartDelayTime" INT 0 100000;
BA_DEF_ BO_  "GenMsgILSupport" ENUM  "No","Yes";
BA_DEF_ BO_  "GenMsgDelayTime" INT 0 1000;
BA_DEF_ BO_  "GenMsgRequestable" INT 0 1;
BA_DEF_ BO_  "GenMsgSendType" ENUM  "cyclic","NotUsed","NotUsed","NotUsed","NotUsed","NotUsed","NotUsed","IfActive","noMsgSendType";
BA_DEF_ BO_  "VFrameFormat" ENUM  "StandardCAN","ExtendedCAN","reserved","J1939PG","reserved","reserved","reserved","reserved","reserved","reserved","reserved","reserved","reserved","reserved","StandardCAN_FD","ExtendedCAN_FD";
BA_DEF_ BO_  "SingleFrame" INT 0 1;
BA_DEF_ BO_  "GenMsgCycleTime" INT 0 3600000;
BA_DEF_ SG_  "SystemSignalLongSymbol" STRING ;
BA_DEF_DEF_  "GenSigInactiveValue" 0;
BA_DEF_DEF_  "SigType" "Default";
BA_DEF_DEF_  "GenSigStartValue" 0;
BA_DEF_DEF_  "GenSigSendType" "NoSigSendType";
BA_DEF_DEF_  "GenSigILSupport" "Yes";
BA_DEF_DEF_  "SPN" 0;
BA_DEF_DEF_  "J1939CPgSendTimeout" -1;
BA_DEF_DEF_  "J1939CPgTOS" 2;
BA_DEF_DEF_  "J1939PgAppearanceOnBus" "Default";
BA_DEF_DEF_  "FsJ1939UseCrcAndCounter" "";
BA_DEF_DEF_  "TpJ1939VarDlc" "No";
BA_DEF_DEF_  "GenMsgNrOfRepetition" 0;
BA_DEF_DEF_  "GenMsgCycleTimeFast" 0;
BA_DEF_DEF_  "GenMsgFastOnStart" 0;
BA_DEF_DEF_  "GenMsgStartDelayTime" 0;
BA_DEF_DEF_  "GenMsgILSupport" "Yes";
BA_DEF_DEF_  "GenMsgDelayTime" 0;
BA_DEF_DEF_  "GenMsgRequestable" 1;
BA_DEF_DEF_  "GenMsgSendType" "noMsgSendType";
BA_DEF_DEF_  "VFrameFormat" "J1939PG";
BA_DEF_DEF_  "SingleFrame" 1;
BA_DEF_DEF_  "GenMsgCycleTime" 0;
BA_DEF_DEF_  "SystemSignalLongSymbol" "";
BA_ "GenMsgSendType" BO_ 2364758270 0;
BA_ "GenMsgCycleTime" BO_ 2364758270 20;
BA_ "GenMsgSendType" BO_ 2364758014 0;
BA_ "GenMsgCycleTime" BO_ 2364758014 20;
BA_ "GenMsgSendType" BO_ 2364757758 0;
BA_ "GenMsgCycleTime" BO_ 2364757758 20;
BA_ "GenMsgSendType" BO_ 2364757502 0;
BA_ "GenMsgCycleTime" BO_ 2364757502 20;
BA_ "GenMsgSendType" BO_ 2364757246 0;
BA_ "GenMsgCycleTime" BO_ 2364757246 20;
BA_ "GenMsgSendType" BO_ 2364756990 0;
BA_ "GenMsgCycleTime" BO_ 2364756990 20;
BA_ "GenMsgSendType" BO_ 2364756734 0;
BA_ "GenMsgCycleTime" BO_ 2364756734 20;
BA_ "GenMsgSendType" BO_ 2364756478 0;
BA_ "GenMsgCycleTime" BO_ 2364756478 20;
BA_ "GenMsgSendType" BO_ 2364756222 0;
BA_ "GenMsgCycleTime" BO_ 2364756222 20;
BA_ "GenMsgSendType" BO_ 2364755966 0;
BA_ "GenMsgCycleTime" BO_ 2364755966 20;
BA_ "GenMsgSendType" BO_ 2364755710 0;
BA_ "GenMsgCycleTime" BO_ 2364755710 20;
BA_ "GenMsgSendType" BO_ 2364755454 0;
BA_ "GenMsgCycleTime" BO_ 2364755454 20;
BA_ "GenMsgSendType" BO_ 2364755198 0;
BA_ "GenMsgCycleTime" BO_ 2364755198 20;
BA_ "GenMsgSendType" BO_ 2364754942 0;
BA_ "GenMsgCycleTime" BO_ 2364754942 100;
BA_ "GenMsgSendType" BO_ 2364754686 0;
BA_ "GenMsgCycleTime" BO_ 2364754686 100;
BA_ "GenMsgSendType" BO_ 2498819326 0;
BA_ "GenMsgCycleTime" BO_ 2498819326 100;
BA_ "GenMsgSendType" BO_ 2565918718 0;
BA_ "GenMsgCycleTime" BO_ 2565918718 100;
BA_ "GenMsgSendType" BO_ 2565905662 0;
BA_ "GenMsgCycleTime" BO_ 2565905662 100;
BA_ "GenMsgSendType" BO_ 2565905406 0;
BA_ "GenMsgCycleTime" BO_ 2565905406 100;
BA_ "GenMsgSendType" BO_ 2565905150 0;
BA_ "GenMsgCycleTime" BO_ 2565905150 100;
BA_ "GenMsgSendType" BO_ 2565904894 0;
BA_ "GenMsgCycleTime" BO_ 2565904894 100;
BA_ "GenMsgSendType" BO_ 2565904638 0;
BA_ "GenMsgCycleTime" BO_ 2565904638 100;
BA_ "GenMsgSendType" BO_ 2565904382 0;
BA_ "GenMsgCycleTime" BO_ 2565904382 100;
BA_ "GenMsgSendType" BO_ 2565900542 0;
BA_ "GenMsgCycleTime" BO_ 2565900542 50;
BA_ "GenMsgDelayTime" BO_ 2555117310 100;
BA_ "GenMsgSendType" BO_ 2555117310 0;
BA_ "GenMsgCycleTime" BO_ 2555117310 1000;
BA_ "GenMsgSendType" BO_ 2555051774 0;
BA_ "GenMsgCycleTime" BO_ 2555051774 1000;
BA_ "GenMsgSendType" BO_ 2554068734 0;
BA_ "GenMsgCycleTime" BO_ 2554068734 20;
BA_ "GenMsgSendType" BO_ 2554003198 0;
BA_ "GenMsgCycleTime" BO_ 2554003198 20;
BA_ "GenMsgDelayTime" BO_ 2352611070 20;
BA_ "GenMsgSendType" BO_ 2352611070 0;
BA_ "GenMsgCycleTime" BO_ 2352611070 200;
BA_ "GenMsgSendType" BO_ 2566687486 0;
BA_ "GenMsgCycleTime" BO_ 2566687486 1000;
BA_ "GenMsgSendType" BO_ 2566687230 0;
BA_ "GenMsgCycleTime" BO_ 2566687230 1000;
BA_ "GenMsgSendType" BO_ 2566686974 0;
BA_ "GenMsgCycleTime" BO_ 2566686974 1000;
BA_ "GenMsgSendType" BO_ 2566686718 0;
BA_ "GenMsgCycleTime" BO_ 2566686718 1000;
BA_ "GenMsgSendType" BO_ 2566686462 0;
BA_ "GenMsgCycleTime" BO_ 2566686462 1000;
BA_ "GenMsgSendType" BO_ 2566686206 0;
BA_ "GenMsgCycleTime" BO_ 2566686206 1000;
BA_ "TpJ1939VarDlc" BO_ 2566675710 1;
BA_ "TpJ1939VarDlc" BO_ 2566675454 1;
BA_ "TpJ1939VarDlc" BO_ 2566675198 1;
BA_ "GenMsgDelayTime" BO_ 2566539774 10;
BA_ "GenMsgSendType" BO_ 2566539774 0;
BA_ "GenMsgCycleTime" BO_ 2566539774 100;
BA_ "GenMsgDelayTime" BO_ 2566539518 100;
BA_ "GenMsgSendType" BO_ 2566539518 0;
BA_ "GenMsgCycleTime" BO_ 2566539518 500;
BA_ "GenMsgSendType" BO_ 2365212158 0;
BA_ "GenMsgCycleTime" BO_ 2365212158 100;
BA_ "GenMsgSendType" BO_ 2566538494 0;
BA_ "GenMsgCycleTime" BO_ 2566538494 10000;
BA_ "GenMsgDelayTime" BO_ 2499429374 100;
BA_ "GenMsgSendType" BO_ 2499429374 0;
BA_ "GenMsgCycleTime" BO_ 2499429374 1000;
BA_ "TpJ1939VarDlc" BO_ 2566537982 1;
BA_ "FsJ1939UseCrcAndCounter" BO_ 2365210878 "Bc";
BA_ "GenMsgSendType" BO_ 2365210878 0;
BA_ "GenMsgCycleTime" BO_ 2365210878 100;
BA_ "GenMsgSendType" BO_ 2566081022 0;
BA_ "GenMsgCycleTime" BO_ 2566081022 100;
BA_ "GenMsgSendType" BO_ 2364754174 0;
BA_ "GenMsgCycleTime" BO_ 2364754174 100;
BA_ "GenMsgSendType" BO_ 2364753918 0;
BA_ "GenMsgCycleTime" BO_ 2364753918 100;
BA_ "GenMsgSendType" BO_ 2364753662 0;
BA_ "GenMsgCycleTime" BO_ 2364753662 100;
BA_ "GenMsgSendType" BO_ 2364753406 0;
BA_ "GenMsgCycleTime" BO_ 2364753406 100;
BA_ "GenMsgSendType" BO_ 2566079742 0;
BA_ "GenMsgCycleTime" BO_ 2566079742 100;
BA_ "GenMsgSendType" BO_ 2566079486 0;
BA_ "GenMsgCycleTime" BO_ 2566079486 100;
BA_ "J1939PgAppearanceOnBus" BO_ 2555313918 2;
BA_ "J1939PgAppearanceOnBus" BO_ 2555248382 2;
BA_ "J1939PgAppearanceOnBus" BO_ 2552626942 2;
BA_ "GenMsgDelayTime" BO_ 2566679038 1000;
BA_ "GenMsgSendType" BO_ 2566679038 0;
BA_ "GenMsgCycleTime" BO_ 2566679038 10000;
BA_ "GenMsgSendType" BO_ 2365332478 0;
BA_ "GenMsgCycleTime" BO_ 2365332478 100;
BA_ "GenMsgSendType" BO_ 2566658814 0;
BA_ "GenMsgCycleTime" BO_ 2566658814 100;
BA_ "GenMsgSendType" BO_ 2566564606 0;
BA_ "GenMsgCycleTime" BO_ 2566564606 100;
BA_ "GenMsgSendType" BO_ 2566564350 0;
BA_ "GenMsgCycleTime" BO_ 2566564350 1000;
BA_ "GenMsgSendType" BO_ 2566563838 0;
BA_ "GenMsgCycleTime" BO_ 2566563838 1000;
BA_ "GenMsgSendType" BO_ 2566563582 0;
BA_ "GenMsgCycleTime" BO_ 2566563582 1000;
BA_ "GenMsgSendType" BO_ 2566563326 0;
BA_ "GenMsgCycleTime" BO_ 2566563326 1000;
BA_ "FsJ1939UseCrcAndCounter" BO_ 2566563070 "Aa";
BA_ "GenMsgSendType" BO_ 2566563070 0;
BA_ "GenMsgCycleTime" BO_ 2566563070 100;
BA_ "SigType" SG_ 2364758270 Cur 1;
BA_ "SPN" SG_ 2364758270 Cur 22493;
BA_ "SigType" SG_ 2364758270 Lvl 1;
BA_ "SPN" SG_ 2364758270 Lvl 22492;
BA_ "SigType" SG_ 2364758270 AvailableChargePwr 1;
BA_ "SPN" SG_ 2364758270 AvailableChargePwr 22491;
BA_ "SigType" SG_ 2364758270 AvailableDisPwr 1;
BA_ "SPN" SG_ 2364758270 AvailableDisPwr 22490;
BA_ "SigType" SG_ 2364758014 NomChargeCurLmt 1;
BA_ "GenSigStartValue" SG_ 2364758014 NomChargeCurLmt 32000;
BA_ "SPN" SG_ 2364758014 NomChargeCurLmt 22836;
BA_ "SigType" SG_ 2364758014 NomDisCurLmt 1;
BA_ "SPN" SG_ 2364758014 NomDisCurLmt 22835;
BA_ "SigType" SG_ 2364758014 MaxCurChargeCurLmt 1;
BA_ "GenSigStartValue" SG_ 2364758014 MaxCurChargeCurLmt 32000;
BA_ "SPN" SG_ 2364758014 MaxCurChargeCurLmt 22473;
BA_ "SigType" SG_ 2364758014 MaxCurDisCurLmt 1;
BA_ "SPN" SG_ 2364758014 MaxCurDisCurLmt 22472;
BA_ "SigType" SG_ 2364757758 Cur 1;
BA_ "SPN" SG_ 2364757758 Cur 22471;
BA_ "SigType" SG_ 2364757758 Lvl 1;
BA_ "SPN" SG_ 2364757758 Lvl 22470;
BA_ "SigType" SG_ 2364757758 AvailableChargePwr 1;
BA_ "SPN" SG_ 2364757758 AvailableChargePwr 22469;
BA_ "SigType" SG_ 2364757758 AvailableDisPwr 1;
BA_ "SPN" SG_ 2364757758 AvailableDisPwr 22468;
BA_ "SigType" SG_ 2364757502 NomChargeCurLmt 1;
BA_ "GenSigStartValue" SG_ 2364757502 NomChargeCurLmt 32000;
BA_ "SPN" SG_ 2364757502 NomChargeCurLmt 22834;
BA_ "SigType" SG_ 2364757502 NomDisCurLmt 1;
BA_ "SPN" SG_ 2364757502 NomDisCurLmt 22833;
BA_ "SigType" SG_ 2364757502 MaxCurChargeCurLmt 1;
BA_ "GenSigStartValue" SG_ 2364757502 MaxCurChargeCurLmt 32000;
BA_ "SPN" SG_ 2364757502 MaxCurChargeCurLmt 22451;
BA_ "SigType" SG_ 2364757502 MaxCurDisCurLmt 1;
BA_ "SPN" SG_ 2364757502 MaxCurDisCurLmt 22450;
BA_ "SigType" SG_ 2364757246 Cur 1;
BA_ "SPN" SG_ 2364757246 Cur 22449;
BA_ "SigType" SG_ 2364757246 Lvl 1;
BA_ "SPN" SG_ 2364757246 Lvl 22448;
BA_ "SigType" SG_ 2364757246 AvailableChargePwr 1;
BA_ "SPN" SG_ 2364757246 AvailableChargePwr 22447;
BA_ "SigType" SG_ 2364757246 AvailableDisPwr 1;
BA_ "SPN" SG_ 2364757246 AvailableDisPwr 22446;
BA_ "SigType" SG_ 2364756990 NomChargeCurLmt 1;
BA_ "GenSigStartValue" SG_ 2364756990 NomChargeCurLmt 32000;
BA_ "SPN" SG_ 2364756990 NomChargeCurLmt 22832;
BA_ "SigType" SG_ 2364756990 NomDisCurLmt 1;
BA_ "SPN" SG_ 2364756990 NomDisCurLmt 22831;
BA_ "SigType" SG_ 2364756990 MaxCurChargeCurLmt 1;
BA_ "GenSigStartValue" SG_ 2364756990 MaxCurChargeCurLmt 32000;
BA_ "SPN" SG_ 2364756990 MaxCurChargeCurLmt 22429;
BA_ "SigType" SG_ 2364756990 MaxCurDisCurLmt 1;
BA_ "SPN" SG_ 2364756990 MaxCurDisCurLmt 22428;
BA_ "SigType" SG_ 2364756734 Cur 1;
BA_ "SPN" SG_ 2364756734 Cur 22427;
BA_ "SigType" SG_ 2364756734 Lvl 1;
BA_ "SPN" SG_ 2364756734 Lvl 22426;
BA_ "SigType" SG_ 2364756734 AvailableChargePwr 1;
BA_ "SPN" SG_ 2364756734 AvailableChargePwr 22425;
BA_ "SigType" SG_ 2364756734 AvailableDisPwr 1;
BA_ "SPN" SG_ 2364756734 AvailableDisPwr 22424;
BA_ "SigType" SG_ 2364756478 NomChargeCurLmt 1;
BA_ "GenSigStartValue" SG_ 2364756478 NomChargeCurLmt 32000;
BA_ "SPN" SG_ 2364756478 NomChargeCurLmt 22830;
BA_ "SigType" SG_ 2364756478 NomDisCurLmt 1;
BA_ "SPN" SG_ 2364756478 NomDisCurLmt 22829;
BA_ "SigType" SG_ 2364756478 MaxCurChargeCurLmt 1;
BA_ "GenSigStartValue" SG_ 2364756478 MaxCurChargeCurLmt 32000;
BA_ "SPN" SG_ 2364756478 MaxCurChargeCurLmt 22407;
BA_ "SigType" SG_ 2364756478 MaxCurDisCurLmt 1;
BA_ "SPN" SG_ 2364756478 MaxCurDisCurLmt 22406;
BA_ "SigType" SG_ 2364756222 Cur 1;
BA_ "SPN" SG_ 2364756222 Cur 22405;
BA_ "SigType" SG_ 2364756222 Lvl 1;
BA_ "SPN" SG_ 2364756222 Lvl 22404;
BA_ "SigType" SG_ 2364756222 AvailableChargePwr 1;
BA_ "SPN" SG_ 2364756222 AvailableChargePwr 22403;
BA_ "SigType" SG_ 2364756222 AvailableDisPwr 1;
BA_ "SPN" SG_ 2364756222 AvailableDisPwr 22402;
BA_ "SigType" SG_ 2364755966 NomChargeCurLmt 1;
BA_ "GenSigStartValue" SG_ 2364755966 NomChargeCurLmt 32000;
BA_ "SPN" SG_ 2364755966 NomChargeCurLmt 22828;
BA_ "SigType" SG_ 2364755966 NomDisCurLmt 1;
BA_ "SPN" SG_ 2364755966 NomDisCurLmt 22827;
BA_ "SigType" SG_ 2364755966 MaxCurChargeCurLmt 1;
BA_ "GenSigStartValue" SG_ 2364755966 MaxCurChargeCurLmt 32000;
BA_ "SPN" SG_ 2364755966 MaxCurChargeCurLmt 22385;
BA_ "SigType" SG_ 2364755966 MaxCurDisCurLmt 1;
BA_ "SPN" SG_ 2364755966 MaxCurDisCurLmt 22384;
BA_ "SigType" SG_ 2364755710 Cur 1;
BA_ "SPN" SG_ 2364755710 Cur 22383;
BA_ "SigType" SG_ 2364755710 Lvl 1;
BA_ "SPN" SG_ 2364755710 Lvl 22382;
BA_ "SigType" SG_ 2364755710 AvailableChargePwr 1;
BA_ "SPN" SG_ 2364755710 AvailableChargePwr 22381;
BA_ "SigType" SG_ 2364755710 AvailableDisPwr 1;
BA_ "SPN" SG_ 2364755710 AvailableDisPwr 22380;
BA_ "SigType" SG_ 2364755454 NomChargeCurLmt 1;
BA_ "GenSigStartValue" SG_ 2364755454 NomChargeCurLmt 32000;
BA_ "SPN" SG_ 2364755454 NomChargeCurLmt 22826;
BA_ "SigType" SG_ 2364755454 NomDisCurLmt 1;
BA_ "SPN" SG_ 2364755454 NomDisCurLmt 22825;
BA_ "SigType" SG_ 2364755454 MaxCurChargeCurLmt 1;
BA_ "GenSigStartValue" SG_ 2364755454 MaxCurChargeCurLmt 32000;
BA_ "SPN" SG_ 2364755454 MaxCurChargeCurLmt 22363;
BA_ "SigType" SG_ 2364755454 MaxCurDisCurLmt 1;
BA_ "SPN" SG_ 2364755454 MaxCurDisCurLmt 22362;
BA_ "SigType" SG_ 2364755198 Cur 1;
BA_ "SPN" SG_ 2364755198 Cur 22361;
BA_ "SigType" SG_ 2364755198 Lvl 1;
BA_ "SPN" SG_ 2364755198 Lvl 22360;
BA_ "SigType" SG_ 2364755198 AvailableChargePwr 1;
BA_ "SPN" SG_ 2364755198 AvailableChargePwr 22359;
BA_ "SigType" SG_ 2364755198 AvailableDisPwr 1;
BA_ "SPN" SG_ 2364755198 AvailableDisPwr 22358;
BA_ "SigType" SG_ 2364754942 SecRealPwrOffsetRampRateSource 4;
BA_ "SPN" SG_ 2364754942 SecRealPwrOffsetRampRateSource 22302;
BA_ "SigType" SG_ 2364754942 SecRealPwrActiveSpOffsetSource 4;
BA_ "SPN" SG_ 2364754942 SecRealPwrActiveSpOffsetSource 22301;
BA_ "SigType" SG_ 2364754942 AndReactivePwrReversionSt 4;
BA_ "SPN" SG_ 2364754942 AndReactivePwrReversionSt 22300;
BA_ "SigType" SG_ 2364754942 ReversionSt 4;
BA_ "SPN" SG_ 2364754942 ReversionSt 22299;
BA_ "SigType" SG_ 2364754942 IntgLocalFreqCtrlResetSt 4;
BA_ "SPN" SG_ 2364754942 IntgLocalFreqCtrlResetSt 22298;
BA_ "SigType" SG_ 2364754942 IntgLocalFreqCtrlOrSecFreqCtrlSt 4;
BA_ "SPN" SG_ 2364754942 IntgLocalFreqCtrlOrSecFreqCtrlSt 22297;
BA_ "SigType" SG_ 2364754942 IntgLocalFreqCtrlSt 4;
BA_ "SPN" SG_ 2364754942 IntgLocalFreqCtrlSt 22296;
BA_ "SigType" SG_ 2364754942 SecFreqCtrlSt 4;
BA_ "SPN" SG_ 2364754942 SecFreqCtrlSt 22295;
BA_ "SigType" SG_ 2364754942 IntgLocalFreqCtrlRealPwrOffset 1;
BA_ "SPN" SG_ 2364754942 IntgLocalFreqCtrlRealPwrOffset 22294;
BA_ "SigType" SG_ 2364754942 DesSecFreqCtrlRealPwrOffset 1;
BA_ "SPN" SG_ 2364754942 DesSecFreqCtrlRealPwrOffset 22293;
BA_ "SigType" SG_ 2364754686 UtilOpRealPwrEnableSt 5;
BA_ "SPN" SG_ 2364754686 UtilOpRealPwrEnableSt 22292;
BA_ "SigType" SG_ 2364754686 ThirdPartyOpRealPwrEnableSt 5;
BA_ "SPN" SG_ 2364754686 ThirdPartyOpRealPwrEnableSt 22291;
BA_ "SigType" SG_ 2364754686 UtilOpRealPwrSt 5;
BA_ "SPN" SG_ 2364754686 UtilOpRealPwrSt 22290;
BA_ "SigType" SG_ 2364754686 ThirdPartyOpRealPwrSt 5;
BA_ "SPN" SG_ 2364754686 ThirdPartyOpRealPwrSt 22289;
BA_ "SigType" SG_ 2364754686 UtilOpRealPwrPctSp 1;
BA_ "SPN" SG_ 2364754686 UtilOpRealPwrPctSp 22288;
BA_ "SigType" SG_ 2364754686 ThirdPartyOpRealPwrSp 1;
BA_ "SPN" SG_ 2364754686 ThirdPartyOpRealPwrSp 22287;
BA_ "SigType" SG_ 2364754686 GenRealLoadCtrlBaseLoadSp 1;
BA_ "SPN" SG_ 2364754686 GenRealLoadCtrlBaseLoadSp 22286;
BA_ "SigType" SG_ 2498819326 GenReactivePwrOverExcitLmtSt 5;
BA_ "SPN" SG_ 2498819326 GenReactivePwrOverExcitLmtSt 22222;
BA_ "SigType" SG_ 2498819326 GenReactivePwrUnderExcitLmtSt 5;
BA_ "SPN" SG_ 2498819326 GenReactivePwrUnderExcitLmtSt 22221;
BA_ "SPN" SG_ 2498819326 GenFaultRideThroughSt 22220;
BA_ "SigType" SG_ 2498819326 GenUtilDecouplingProtTestFuncSt 5;
BA_ "SPN" SG_ 2498819326 GenUtilDecouplingProtTestFuncSt 22219;
BA_ "SigType" SG_ 2498819326 GenUvAndOvProtTestFuncSt 5;
BA_ "SPN" SG_ 2498819326 GenUvAndOvProtTestFuncSt 22218;
BA_ "SigType" SG_ 2498819326 TestFuncForTheProtSt 5;
BA_ "SPN" SG_ 2498819326 TestFuncForTheProtSt 22742;
BA_ "SigType" SG_ 2498819326 SimulatedMainsFreqSt 5;
BA_ "SPN" SG_ 2498819326 SimulatedMainsFreqSt 22741;
BA_ "SigType" SG_ 2498819326 SimulatedMainsFreqOffset 1;
BA_ "SPN" SG_ 2498819326 SimulatedMainsFreqOffset 22740;
BA_ "SigType" SG_ 2498819326 DemandedV 1;
BA_ "SPN" SG_ 2498819326 DemandedV 22739;
BA_ "SigType" SG_ 2498819326 DemandedPwrFactor 1;
BA_ "SPN" SG_ 2498819326 DemandedPwrFactor 22738;
BA_ "SPN" SG_ 2565918718 FourOpSt 22970;
BA_ "SPN" SG_ 2565918718 ThreeOpSt 22969;
BA_ "SigType" SG_ 2565918462 WastegateAct4Cmd 1;
BA_ "SPN" SG_ 2565918462 WastegateAct4Cmd 22968;
BA_ "SigType" SG_ 2565918462 WastegateAct3Cmd 1;
BA_ "SPN" SG_ 2565918462 WastegateAct3Cmd 22967;
BA_ "SigType" SG_ 2565905662 CapLmt 1;
BA_ "SPN" SG_ 2565905662 CapLmt 22966;
BA_ "SigType" SG_ 2565905662 CapUsed 1;
BA_ "SPN" SG_ 2565905662 CapUsed 22965;
BA_ "SigType" SG_ 2565905406 CapLmt 1;
BA_ "SPN" SG_ 2565905406 CapLmt 22962;
BA_ "SigType" SG_ 2565905406 CapUsed 1;
BA_ "SPN" SG_ 2565905406 CapUsed 22961;
BA_ "SigType" SG_ 2565905150 CapLmt 1;
BA_ "SPN" SG_ 2565905150 CapLmt 22958;
BA_ "SigType" SG_ 2565905150 CapUsed 1;
BA_ "SPN" SG_ 2565905150 CapUsed 22957;
BA_ "SigType" SG_ 2565904894 CapLmt 1;
BA_ "SPN" SG_ 2565904894 CapLmt 22954;
BA_ "SigType" SG_ 2565904894 CapUsed 1;
BA_ "SPN" SG_ 2565904894 CapUsed 22953;
BA_ "SigType" SG_ 2565904638 CapLmt 1;
BA_ "SPN" SG_ 2565904638 CapLmt 22950;
BA_ "SigType" SG_ 2565904638 CapUsed 1;
BA_ "SPN" SG_ 2565904638 CapUsed 22949;
BA_ "SigType" SG_ 2565904382 CapLmt 1;
BA_ "SPN" SG_ 2565904382 CapLmt 22946;
BA_ "SigType" SG_ 2565904382 CapUsed 1;
BA_ "SPN" SG_ 2565904382 CapUsed 22945;
BA_ "SigType" SG_ 2565900542 OverallQuality 1;
BA_ "SPN" SG_ 2565900542 OverallQuality 22731;
BA_ "SigType" SG_ 2565900542 ZQuality 1;
BA_ "SPN" SG_ 2565900542 ZQuality 22730;
BA_ "SigType" SG_ 2565900542 YQuality 1;
BA_ "SPN" SG_ 2565900542 YQuality 22729;
BA_ "SigType" SG_ 2565900542 XQuality 1;
BA_ "SPN" SG_ 2565900542 XQuality 22728;
BA_ "SPN" SG_ 2555117310 HybMultiConnReqEnergyXferType 22695;
BA_ "SigType" SG_ 2555117310 HybMultiConnDCChargingPwrMax 1;
BA_ "SPN" SG_ 2555117310 HybMultiConnDCChargingPwrMax 22694;
BA_ "SigType" SG_ 2555117310 HybMultiConnDCChargingCurMax 1;
BA_ "SPN" SG_ 2555117310 HybMultiConnDCChargingCurMax 22693;
BA_ "SigType" SG_ 2555117310 HybMultiConnDCChargingVMax 1;
BA_ "SPN" SG_ 2555117310 HybMultiConnDCChargingVMax 22692;
BA_ "SigType" SG_ 2555051774 StOfCharge 1;
BA_ "SPN" SG_ 2555051774 StOfCharge 22710;
BA_ "SPN" SG_ 2555051774 ErrorCode 22709;
BA_ "SigType" SG_ 2555051774 RESSConditioningFlag 5;
BA_ "SPN" SG_ 2555051774 RESSConditioningFlag 22708;
BA_ "SigType" SG_ 2555051774 CabinConditioningFlag 5;
BA_ "SPN" SG_ 2555051774 CabinConditioningFlag 22707;
BA_ "SigType" SG_ 2554068734 AuxChrgCmdTargetCur 1;
BA_ "SPN" SG_ 2554068734 AuxChrgCmdTargetCur 22686;
BA_ "SigType" SG_ 2554068734 AuxChrgCmdTargetV 1;
BA_ "SPN" SG_ 2554068734 AuxChrgCmdTargetV 22685;
BA_ "SPN" SG_ 2554068734 AuxChrgCmdSequenceCounter 22684;
BA_ "SPN" SG_ 2554068734 AuxChrgCmdCRC 22683;
BA_ "SigType" SG_ 2554003198 CmdTargetCur 1;
BA_ "SPN" SG_ 2554003198 CmdTargetCur 22682;
BA_ "SigType" SG_ 2554003198 CmdTargetV 1;
BA_ "SPN" SG_ 2554003198 CmdTargetV 22681;
BA_ "SPN" SG_ 2554003198 CmdSequenceCounter 22680;
BA_ "SPN" SG_ 2554003198 CmdCRC 22679;
BA_ "SigType" SG_ 2352611070 InMessageIntegrityDataSupported 5;
BA_ "SPN" SG_ 2352611070 InMessageIntegrityDataSupported 22622;
BA_ "SigType" SG_ 2352611070 CtrlMode 5;
BA_ "SPN" SG_ 2352611070 CtrlMode 22127;
BA_ "SigType" SG_ 2352611070 ExtlACCAccelerationReq 1;
BA_ "SPN" SG_ 2352611070 ExtlACCAccelerationReq 22126;
BA_ "SPN" SG_ 2352611070 Counter 22129;
BA_ "SPN" SG_ 2352611070 CRC 22128;
BA_ "SigType" SG_ 2566687486 EnableSt 4;
BA_ "SPN" SG_ 2566687486 EnableSt 21332;
BA_ "SigType" SG_ 2566687486 InputCur 1;
BA_ "SPN" SG_ 2566687486 InputCur 21335;
BA_ "SigType" SG_ 2566687486 InputV 1;
BA_ "SPN" SG_ 2566687486 InputV 21334;
BA_ "SigType" SG_ 2566687486 Spd 1;
BA_ "SPN" SG_ 2566687486 Spd 21333;
BA_ "SigType" SG_ 2566687230 EnableSt 4;
BA_ "SPN" SG_ 2566687230 EnableSt 21331;
BA_ "SigType" SG_ 2566687230 Pump1InputCur 1;
BA_ "SPN" SG_ 2566687230 Pump1InputCur 21330;
BA_ "SigType" SG_ 2566687230 Pump1InputV 1;
BA_ "SPN" SG_ 2566687230 Pump1InputV 21329;
BA_ "SigType" SG_ 2566687230 Spd 1;
BA_ "SPN" SG_ 2566687230 Spd 21328;
BA_ "SigType" SG_ 2566686974 EnableCmd 5;
BA_ "SPN" SG_ 2566686974 EnableCmd 21327;
BA_ "SigType" SG_ 2566686974 PercentSpdCmd 1;
BA_ "SPN" SG_ 2566686974 PercentSpdCmd 21326;
BA_ "SigType" SG_ 2566686974 SpdCmd 1;
BA_ "SPN" SG_ 2566686974 SpdCmd 21325;
BA_ "SigType" SG_ 2566686718 EnableCmd 5;
BA_ "SPN" SG_ 2566686718 EnableCmd 21324;
BA_ "SigType" SG_ 2566686718 PercentSpdCmd 1;
BA_ "SPN" SG_ 2566686718 PercentSpdCmd 21323;
BA_ "SigType" SG_ 2566686718 SpdCmd 1;
BA_ "SPN" SG_ 2566686718 SpdCmd 21322;
BA_ "SigType" SG_ 2566686462 InputVLvl 1;
BA_ "SPN" SG_ 2566686462 InputVLvl 21321;
BA_ "SigType" SG_ 2566686462 InputCurLvl 1;
BA_ "SPN" SG_ 2566686462 InputCurLvl 21320;
BA_ "SigType" SG_ 2566686462 OutCoolantTemp 1;
BA_ "SPN" SG_ 2566686462 OutCoolantTemp 21319;
BA_ "SigType" SG_ 2566686462 OutPwrPercent 1;
BA_ "SPN" SG_ 2566686462 OutPwrPercent 21318;
BA_ "SPN" SG_ 2566686462 Mode 21317;
BA_ "SigType" SG_ 2566686206 OutCoolantTempSp 1;
BA_ "SPN" SG_ 2566686206 OutCoolantTempSp 21316;
BA_ "SigType" SG_ 2566686206 PwrPercentCmd 1;
BA_ "SPN" SG_ 2566686206 PwrPercentCmd 21315;
BA_ "SPN" SG_ 2566686206 ModeReq 21314;
BA_ "SigType" SG_ 2566675710 Component3Identifier 1;
BA_ "SPN" SG_ 2566675710 Component3Identifier 21205;
BA_ "SigType" SG_ 2566675710 SyncSvcDelay_CalendarTime 1;
BA_ "SPN" SG_ 2566675710 SyncSvcDelay_CalendarTime 21204;
BA_ "SigType" SG_ 2566675454 Component2Identifier 1;
BA_ "SPN" SG_ 2566675454 Component2Identifier 21203;
BA_ "SigType" SG_ 2566675454 SyncSvcDelay_OperationalTime 1;
BA_ "SPN" SG_ 2566675454 SyncSvcDelay_OperationalTime 21202;
BA_ "SigType" SG_ 2566675198 Component1Identifier 1;
BA_ "SPN" SG_ 2566675198 Component1Identifier 21201;
BA_ "SigType" SG_ 2566675198 SyncSvcDist 1;
BA_ "SPN" SG_ 2566675198 SyncSvcDist 21200;
BA_ "SPN" SG_ 2566539774 RearParkAssistSt 21130;
BA_ "SPN" SG_ 2566539774 FrontParkAssistSt 21129;
BA_ "SigType" SG_ 2566539518 CtrlPushToTalkSw 5;
BA_ "SPN" SG_ 2566539518 CtrlPushToTalkSw 21137;
BA_ "SigType" SG_ 2566539518 CtrlVoiceCommunicationSw 5;
BA_ "SPN" SG_ 2566539518 CtrlVoiceCommunicationSw 21136;
BA_ "SigType" SG_ 2566539518 CtrlCallEndSw 5;
BA_ "SPN" SG_ 2566539518 CtrlCallEndSw 21135;
BA_ "SigType" SG_ 2566539518 CtrlVolumeDownSw 5;
BA_ "SPN" SG_ 2566539518 CtrlVolumeDownSw 21134;
BA_ "SigType" SG_ 2566539518 CtrlVolumeUpSw 5;
BA_ "SPN" SG_ 2566539518 CtrlVolumeUpSw 21133;
BA_ "SigType" SG_ 2566539518 CtrlPreviousSw 5;
BA_ "SPN" SG_ 2566539518 CtrlPreviousSw 21132;
BA_ "SigType" SG_ 2566539518 CtrlNextSw 5;
BA_ "SPN" SG_ 2566539518 CtrlNextSw 21131;
BA_ "SigType" SG_ 2566539262 TwoSvcModeReq 5;
BA_ "SPN" SG_ 2566539262 TwoSvcModeReq 21142;
BA_ "SigType" SG_ 2566539262 OneSvcModeReq 5;
BA_ "SPN" SG_ 2566539262 OneSvcModeReq 21141;
BA_ "SPN" SG_ 2566539006 St 21147;
BA_ "SPN" SG_ 2566539006 LmtReason 21151;
BA_ "SPN" SG_ 2566539006 DisReason 21150;
BA_ "SigType" SG_ 2566539006 TimeToLmtMachineOp 1;
BA_ "SPN" SG_ 2566539006 TimeToLmtMachineOp 21149;
BA_ "SigType" SG_ 2566539006 TimeToDisMachineOp 1;
BA_ "SPN" SG_ 2566539006 TimeToDisMachineOp 21148;
BA_ "SigType" SG_ 2365212158 KVArHoursImport 1;
BA_ "SPN" SG_ 2365212158 KVArHoursImport 21154;
BA_ "SigType" SG_ 2566538494 TotalAvgLoadFactor 1;
BA_ "SPN" SG_ 2566538494 TotalAvgLoadFactor 21167;
BA_ "SigType" SG_ 2566538494 TripAvgLoadFactor 1;
BA_ "SPN" SG_ 2566538494 TripAvgLoadFactor 21166;
BA_ "SigType" SG_ 2499429374 TotalRegenerativeBrakingLvl 1;
BA_ "SPN" SG_ 2499429374 TotalRegenerativeBrakingLvl 21224;
BA_ "SigType" SG_ 2566537982 Ctrl4Id2 8;
BA_ "SPN" SG_ 2566537982 Ctrl4Id2 21238;
BA_ "SigType" SG_ 2566537982 Ctrl4Id1 8;
BA_ "SPN" SG_ 2566537982 Ctrl4Id1 21237;
BA_ "SigType" SG_ 2566537982 Ctrl3Id2 8;
BA_ "SPN" SG_ 2566537982 Ctrl3Id2 21236;
BA_ "SigType" SG_ 2566537982 Ctrl3Id1 8;
BA_ "SPN" SG_ 2566537982 Ctrl3Id1 21235;
BA_ "SigType" SG_ 2566537982 Ctrl2Id2 8;
BA_ "SPN" SG_ 2566537982 Ctrl2Id2 21234;
BA_ "SigType" SG_ 2566537982 Ctrl2Id1 8;
BA_ "SPN" SG_ 2566537982 Ctrl2Id1 21233;
BA_ "SigType" SG_ 2566537982 Ctrl1Id2 8;
BA_ "SPN" SG_ 2566537982 Ctrl1Id2 21232;
BA_ "SigType" SG_ 2566537982 Ctrl1Id1 8;
BA_ "SPN" SG_ 2566537982 Ctrl1Id1 21231;
BA_ "SPN" SG_ 2566537726 SAOfCtrl4 21246;
BA_ "SPN" SG_ 2566537726 ReceivePortOfCtrl4 21245;
BA_ "SPN" SG_ 2566537726 ReceivePortOfCtrl3 21244;
BA_ "SPN" SG_ 2566537726 SAOfCtrl3 21243;
BA_ "SPN" SG_ 2566537726 SAOfCtrl2 21242;
BA_ "SPN" SG_ 2566537726 ReceivePortOfCtrl2 21241;
BA_ "SPN" SG_ 2566537726 ReceivePortOfCtrl1 21240;
BA_ "SPN" SG_ 2566537726 SAOfCtrl1 21239;
BA_ "SPN" SG_ 2365210878 AutoNeutralFunctionSt 21254;
BA_ "SPN" SG_ 2365210878 AutoNeutralReqFeedback 21253;
BA_ "SigType" SG_ 2365210878 Ctrl15Counter 11;
BA_ "SPN" SG_ 2365210878 Ctrl15Counter 21256;
BA_ "SigType" SG_ 2365210878 Ctrl15CRC 12;
BA_ "SPN" SG_ 2365210878 Ctrl15CRC 21255;
BA_ "SigType" SG_ 2566081022 HydrogenConcentration 1;
BA_ "SPN" SG_ 2566081022 HydrogenConcentration 21338;
BA_ "SigType" SG_ 2566081022 Enclosure2HydrogenConcentration 1;
BA_ "SPN" SG_ 2566081022 Enclosure2HydrogenConcentration 21337;
BA_ "SigType" SG_ 2566081022 Enclosure1HydrogenConcentration 1;
BA_ "SPN" SG_ 2566081022 Enclosure1HydrogenConcentration 21336;
BA_ "SigType" SG_ 2364754174 CtrlAtLowLoadSt 4;
BA_ "SPN" SG_ 2364754174 CtrlAtLowLoadSt 22737;
BA_ "SigType" SG_ 2364754174 ModeSelectionDigitalInput4St 4;
BA_ "SPN" SG_ 2364754174 ModeSelectionDigitalInput4St 22736;
BA_ "SigType" SG_ 2364754174 ModeSelectionDigitalInput3St 4;
BA_ "SPN" SG_ 2364754174 ModeSelectionDigitalInput3St 22735;
BA_ "SigType" SG_ 2364754174 ModeSelectionDigitalInput2St 4;
BA_ "SPN" SG_ 2364754174 ModeSelectionDigitalInput2St 22734;
BA_ "SigType" SG_ 2364754174 ModeSelectionDigitalInput1St 4;
BA_ "SPN" SG_ 2364754174 ModeSelectionDigitalInput1St 22733;
BA_ "SPN" SG_ 2364754174 UtilOpReactivePwrSpSource 22732;
BA_ "SPN" SG_ 2364754174 UtilSyncronizationSt 21280;
BA_ "SigType" SG_ 2364754174 UtilSycronizationDelTime 1;
BA_ "SPN" SG_ 2364754174 UtilSycronizationDelTime 21281;
BA_ "SigType" SG_ 2364754174 Sp 1;
BA_ "SPN" SG_ 2364754174 Sp 21278;
BA_ "SPN" SG_ 2364754174 ActiveLmtSource 21279;
BA_ "SPN" SG_ 2364754174 ActiveSpSource 21277;
BA_ "SPN" SG_ 2364753918 PrimRealPwrOffsetRampRateSource 22285;
BA_ "SPN" SG_ 2364753918 PrimRealPwrActiveSpOffsetSource 22284;
BA_ "SigType" SG_ 2364753918 IncreaseRampRateSp 1;
BA_ "SPN" SG_ 2364753918 IncreaseRampRateSp 21275;
BA_ "SigType" SG_ 2364753918 SpPct 1;
BA_ "SPN" SG_ 2364753918 SpPct 21274;
BA_ "SPN" SG_ 2364753918 RampRateSource 21273;
BA_ "SPN" SG_ 2364753918 ActiveSpSource 21272;
BA_ "SigType" SG_ 2364753918 DecreaseRampRateSp 1;
BA_ "SPN" SG_ 2364753918 DecreaseRampRateSp 21276;
BA_ "SigType" SG_ 2364753662 RealPwrRampRateLmtSt 4;
BA_ "SPN" SG_ 2364753662 RealPwrRampRateLmtSt 22283;
BA_ "SigType" SG_ 2364753662 RealPwrRampRateLmtEnableSt 4;
BA_ "SPN" SG_ 2364753662 RealPwrRampRateLmtEnableSt 22282;
BA_ "SigType" SG_ 2364753662 UtilOpRealPwrExportLmtSp4St 4;
BA_ "SPN" SG_ 2364753662 UtilOpRealPwrExportLmtSp4St 22281;
BA_ "SigType" SG_ 2364753662 UtilOpRealPwrExportLmtSp3St 4;
BA_ "SPN" SG_ 2364753662 UtilOpRealPwrExportLmtSp3St 22280;
BA_ "SigType" SG_ 2364753662 UtilOpRealPwrExportLmtSp2St 4;
BA_ "SPN" SG_ 2364753662 UtilOpRealPwrExportLmtSp2St 22279;
BA_ "SigType" SG_ 2364753662 UtilOpRealPwrExportLmtSp1St 4;
BA_ "SPN" SG_ 2364753662 UtilOpRealPwrExportLmtSp1St 22278;
BA_ "SigType" SG_ 2364753662 UtilParVRealPwrCurveSt 4;
BA_ "SPN" SG_ 2364753662 UtilParVRealPwrCurveSt 21269;
BA_ "SigType" SG_ 2364753662 UtilOpRealPwrExportLmtSt 4;
BA_ "SPN" SG_ 2364753662 UtilOpRealPwrExportLmtSt 21268;
BA_ "SigType" SG_ 2364753662 UtilParVRealPwrCurveSpPct 1;
BA_ "SPN" SG_ 2364753662 UtilParVRealPwrCurveSpPct 21271;
BA_ "SigType" SG_ 2364753662 UtilOpRealPwrExportLmtPct 1;
BA_ "SPN" SG_ 2364753662 UtilOpRealPwrExportLmtPct 21270;
BA_ "SigType" SG_ 2364753406 SensModeEnableSt 5;
BA_ "SPN" SG_ 2364753406 SensModeEnableSt 22277;
BA_ "SigType" SG_ 2364753406 LimFSMOfEnableStDeactThldResetSt 5;
BA_ "SPN" SG_ 2364753406 LimFSMOfEnableStDeactThldResetSt 22276;
BA_ "SigType" SG_ 2364753406 LimFSMUfSt 5;
BA_ "SPN" SG_ 2364753406 LimFSMUfSt 22275;
BA_ "SigType" SG_ 2364753406 LimFSMOfEnableSt 5;
BA_ "SPN" SG_ 2364753406 LimFSMOfEnableSt 22274;
BA_ "SigType" SG_ 2364753406 SensitiveModeSt 4;
BA_ "SPN" SG_ 2364753406 SensitiveModeSt 21265;
BA_ "SigType" SG_ 2364753406 LimFreqSensitiveModeSt 4;
BA_ "SPN" SG_ 2364753406 LimFreqSensitiveModeSt 21263;
BA_ "SigType" SG_ 2364753406 GeneratorFreqOffsetSp 1;
BA_ "SPN" SG_ 2364753406 GeneratorFreqOffsetSp 21267;
BA_ "SigType" SG_ 2364753406 SensitiveModeRealPwrSp 1;
BA_ "SPN" SG_ 2364753406 SensitiveModeRealPwrSp 21266;
BA_ "SigType" SG_ 2364753406 LimFreqSensitiveModeRealPwrSp 1;
BA_ "SPN" SG_ 2364753406 LimFreqSensitiveModeRealPwrSp 21264;
BA_ "SigType" SG_ 2566079742 ActiveExtlInhAntiRollAway 5;
BA_ "SPN" SG_ 2566079742 ActiveExtlInhAntiRollAway 21198;
BA_ "SigType" SG_ 2566079742 AntiRollAwayReqSysStInh 5;
BA_ "SPN" SG_ 2566079742 AntiRollAwayReqSysStInh 21197;
BA_ "SigType" SG_ 2566079742 TransNeutralReqSt 5;
BA_ "SPN" SG_ 2566079742 TransNeutralReqSt 21196;
BA_ "SigType" SG_ 2566079742 ParkAtSpdExtlBrkReqSt 5;
BA_ "SPN" SG_ 2566079742 ParkAtSpdExtlBrkReqSt 21195;
BA_ "SPN" SG_ 2566079742 ActiveExtlCtrlModeTowedUnit 21194;
BA_ "SPN" SG_ 2566079742 ActiveExtlCtrlModePwrUnit 21193;
BA_ "SigType" SG_ 2566079742 ExtlReqSysStTowedUnitEvacuate 5;
BA_ "SPN" SG_ 2566079742 ExtlReqSysStTowedUnitEvacuate 21192;
BA_ "SigType" SG_ 2566079742 ExtlReqSysStTowedUnitSupply 5;
BA_ "SPN" SG_ 2566079742 ExtlReqSysStTowedUnitSupply 21191;
BA_ "SigType" SG_ 2566079742 ExtlReqSysStPwrUnitRelease 5;
BA_ "SPN" SG_ 2566079742 ExtlReqSysStPwrUnitRelease 21190;
BA_ "SigType" SG_ 2566079742 ExtlReqSysStPwrUnitApply 5;
BA_ "SPN" SG_ 2566079742 ExtlReqSysStPwrUnitApply 21189;
BA_ "SigType" SG_ 2566079742 TowedUnitCircAirPress 1;
BA_ "SPN" SG_ 2566079742 TowedUnitCircAirPress 21188;
BA_ "SigType" SG_ 2566079742 PwrUnitCircAirPress 1;
BA_ "SPN" SG_ 2566079742 PwrUnitCircAirPress 21187;
BA_ "SigType" SG_ 2566079742 TowedUnitCtrlAirPress 1;
BA_ "SPN" SG_ 2566079742 TowedUnitCtrlAirPress 21186;
BA_ "SigType" SG_ 2566079742 PwrUnitCtrlAirPress 1;
BA_ "SPN" SG_ 2566079742 PwrUnitCtrlAirPress 21185;
BA_ "SPN" SG_ 2566079486 TowedUnitSwSt 21184;
BA_ "SPN" SG_ 2566079486 PwrUnitSwSt 21183;
BA_ "SigType" SG_ 2566079486 AntiRollAwayTimer 1;
BA_ "SPN" SG_ 2566079486 AntiRollAwayTimer 21182;
BA_ "SPN" SG_ 2566079486 PwrSt 21181;
BA_ "SPN" SG_ 2566079486 ExhAtSpdSt 21180;
BA_ "SigType" SG_ 2566079486 TlrOvrdIlkDoor2St 5;
BA_ "SPN" SG_ 2566079486 TlrOvrdIlkDoor2St 21179;
BA_ "SigType" SG_ 2566079486 TlrOvrdIlkDoor1St 5;
BA_ "SPN" SG_ 2566079486 TlrOvrdIlkDoor1St 21178;
BA_ "SigType" SG_ 2566079486 TlrOvrdIlkSeatBeltSwSt 5;
BA_ "SPN" SG_ 2566079486 TlrOvrdIlkSeatBeltSwSt 21177;
BA_ "SigType" SG_ 2566079486 TlrOvrdIlkIgntSt 5;
BA_ "SPN" SG_ 2566079486 TlrOvrdIlkIgntSt 21176;
BA_ "SigType" SG_ 2566079486 TlrOvrdIlkSvcBrkSt 5;
BA_ "SPN" SG_ 2566079486 TlrOvrdIlkSvcBrkSt 21175;
BA_ "SPN" SG_ 2566079486 OperatingMode 21174;
BA_ "SigType" SG_ 2566079486 PwrUnitVehType 5;
BA_ "SPN" SG_ 2566079486 PwrUnitVehType 21173;
BA_ "SigType" SG_ 2566079486 TlrBrkReleaseSt 5;
BA_ "SPN" SG_ 2566079486 TlrBrkReleaseSt 21172;
BA_ "SigType" SG_ 2566079486 OccupancyAntiRollAwaySt 5;
BA_ "SPN" SG_ 2566079486 OccupancyAntiRollAwaySt 21171;
BA_ "SPN" SG_ 2566079486 TowedUnitCtrlAirSt 21170;
BA_ "SPN" SG_ 2566079486 PwrUnitCtrlAirSt 21169;
BA_ "SigType" SG_ 2566679038 HVESSEstRemainingDist 1;
BA_ "SPN" SG_ 2566679038 HVESSEstRemainingDist 15268;
BA_ "SigType" SG_ 2365332478 CompressorPercentSpdCmd 1;
BA_ "SPN" SG_ 2365332478 CompressorPercentSpdCmd 20463;
BA_ "SigType" SG_ 2365332478 CompressorSpdCmd 1;
BA_ "SPN" SG_ 2365332478 CompressorSpdCmd 20462;
BA_ "SigType" SG_ 2365332478 CPPercentSpdCmd 1;
BA_ "SPN" SG_ 2365332478 CPPercentSpdCmd 20461;
BA_ "SigType" SG_ 2365332478 CPSpdCmd 1;
BA_ "SPN" SG_ 2365332478 CPSpdCmd 20460;
BA_ "SigType" SG_ 2566658814 CompressorEnableCmd 5;
BA_ "SPN" SG_ 2566658814 CompressorEnableCmd 20459;
BA_ "SigType" SG_ 2566658814 CPEnableCmd 5;
BA_ "SPN" SG_ 2566658814 CPEnableCmd 20458;
BA_ "SigType" SG_ 2566658814 HtrEnableCmd 5;
BA_ "SPN" SG_ 2566658814 HtrEnableCmd 20457;
BA_ "SigType" SG_ 2566658814 CoolantFlowRateReq 1;
BA_ "SPN" SG_ 2566658814 CoolantFlowRateReq 20456;
BA_ "SigType" SG_ 2566658814 OutCoolantTempReq 1;
BA_ "SPN" SG_ 2566658814 OutCoolantTempReq 20455;
BA_ "SigType" SG_ 2566658814 InletCoolantTempReq 1;
BA_ "SPN" SG_ 2566658814 InletCoolantTempReq 20454;
BA_ "SigType" SG_ 2566564606 CurGear 1;
BA_ "SPN" SG_ 2566564606 CurGear 15203;
BA_ "SigType" SG_ 2566564606 SelectedGear 1;
BA_ "SPN" SG_ 2566564606 SelectedGear 15202;
BA_ "SigType" SG_ 2566564350 OneIntmdShaftPeakTwist 1;
BA_ "SPN" SG_ 2566564350 OneIntmdShaftPeakTwist 15220;
BA_ "SigType" SG_ 2566564350 OneOutShaftPeakTwist 1;
BA_ "SPN" SG_ 2566564350 OneOutShaftPeakTwist 15219;
BA_ "SigType" SG_ 2566564350 OneInputShaftPeakTwist 1;
BA_ "SPN" SG_ 2566564350 OneInputShaftPeakTwist 15218;
BA_ "SigType" SG_ 2566564094 OpTimeSinceRebuild 1;
BA_ "SPN" SG_ 2566564094 OpTimeSinceRebuild 15223;
BA_ "SigType" SG_ 2566564094 TotalOutShaftRevolutions 1;
BA_ "SPN" SG_ 2566564094 TotalOutShaftRevolutions 15222;
BA_ "SigType" SG_ 2566564094 TotalHoursOfOp 1;
BA_ "SPN" SG_ 2566564094 TotalHoursOfOp 15221;
BA_ "SigType" SG_ 2566563838 EstCurDieselSavingsRatePct 1;
BA_ "SPN" SG_ 2566563838 EstCurDieselSavingsRatePct 15228;
BA_ "SigType" SG_ 2566563838 DieselFuelPercentDisp 1;
BA_ "SPN" SG_ 2566563838 DieselFuelPercentDisp 15227;
BA_ "SigType" SG_ 2566563838 PercentTimeActive 1;
BA_ "SPN" SG_ 2566563838 PercentTimeActive 15226;
BA_ "SigType" SG_ 2566563838 TotalDieselFuelPercentDisp 1;
BA_ "SPN" SG_ 2566563838 TotalDieselFuelPercentDisp 15225;
BA_ "SigType" SG_ 2566563838 TotalDieselFuelUsed 1;
BA_ "SPN" SG_ 2566563838 TotalDieselFuelUsed 15224;
BA_ "SigType" SG_ 2566563582 TotalDieselFuelDemand 1;
BA_ "SPN" SG_ 2566563582 TotalDieselFuelDemand 15230;
BA_ "SigType" SG_ 2566563582 TotalDieselFuelDispByGasFuel 1;
BA_ "SPN" SG_ 2566563582 TotalDieselFuelDispByGasFuel 15229;
BA_ "SPN" SG_ 2566563326 StReason 21144;
BA_ "SPN" SG_ 2566563326 OperatingSt 21143;
BA_ "SigType" SG_ 2566563326 EstCurFuelSavingsRate 1;
BA_ "SPN" SG_ 2566563326 EstCurFuelSavingsRate 15231;
BA_ "SigType" SG_ 2566563070 CRC 12;
BA_ "SPN" SG_ 2566563070 CRC 22263;
BA_ "SigType" SG_ 2566563070 Counter 11;
BA_ "SPN" SG_ 2566563070 Counter 22262;
BA_ "SigType" SG_ 2566563070 EmbeddedIntegritySupport 5;
BA_ "SPN" SG_ 2566563070 EmbeddedIntegritySupport 22261;
BA_ "SPN" SG_ 2566563070 VSCtrlCmdPriority 20869;
BA_ "SigType" SG_ 2566563070 VSCtrlCmd 1;
BA_ "SPN" SG_ 2566563070 VSCtrlCmd 15248;
BA_ "SPN" SG_ 2566562814 NomRatedCapacity 17540;
BA_ "SigType" SG_ 2566562814 CellMinVLmt 1;
BA_ "SPN" SG_ 2566562814 CellMinVLmt 17539;
BA_ "SigType" SG_ 2566562814 CellMaxVLmt 1;
BA_ "SPN" SG_ 2566562814 CellMaxVLmt 17538;
BA_ "SigType" SG_ 2566562814 RecommendedMinOperatingTemp 1;
BA_ "SPN" SG_ 2566562814 RecommendedMinOperatingTemp 17537;
BA_ "SigType" SG_ 2566562814 RecommendedMaxOperatingTemp 1;
BA_ "SPN" SG_ 2566562814 RecommendedMaxOperatingTemp 17536;
BA_ "SigType" SG_ 2566562814 RecommendedMaxStOfCharge 1;
BA_ "SPN" SG_ 2566562814 RecommendedMaxStOfCharge 17535;
BA_ "SigType" SG_ 2566562814 RecommendedMinStOfCharge 1;
BA_ "SPN" SG_ 2566562814 RecommendedMinStOfCharge 17534;
BA_ "SigType" SG_ 2566562814 RecommendedMaxOperatingV 1;
BA_ "SPN" SG_ 2566562814 RecommendedMaxOperatingV 17533;
BA_ "SigType" SG_ 2566562814 RecommendedMinOperatingV 1;
BA_ "SPN" SG_ 2566562814 RecommendedMinOperatingV 17532;
BA_ "SigType" SG_ 2566562814 NomV 1;
BA_ "SPN" SG_ 2566562814 NomV 17531;
BA_ "SigType" SG_ 2633671422 TotalEnergyOut 1;
BA_ "SPN" SG_ 2633671422 TotalEnergyOut 17530;
BA_ "SigType" SG_ 2633671422 TotalEnergyInput 1;
BA_ "SPN" SG_ 2633671422 TotalEnergyInput 17529;
BA_ "SigType" SG_ 2633671422 TotalAccumulatedCharge 1;
BA_ "SPN" SG_ 2633671422 TotalAccumulatedCharge 17528;
BA_ "SigType" SG_ 2633671422 TotalEnergyThroughput 1;
BA_ "SPN" SG_ 2633671422 TotalEnergyThroughput 17527;
BA_ "SigType" SG_ 2633671422 ContactorOpenUnderLoadCount 1;
BA_ "SPN" SG_ 2633671422 ContactorOpenUnderLoadCount 17526;
BA_ "SigType" SG_ 2633671422 StOfHealth 1;
BA_ "SPN" SG_ 2633671422 StOfHealth 17525;
BA_ "SPN" SG_ 2566562302 NomRatedCapacity 17398;
BA_ "SigType" SG_ 2566562302 CellMinVLmt 1;
BA_ "SPN" SG_ 2566562302 CellMinVLmt 17397;
BA_ "SigType" SG_ 2566562302 CellMaxVLmt 1;
BA_ "SPN" SG_ 2566562302 CellMaxVLmt 17396;
BA_ "SigType" SG_ 2566562302 RecommendedMinOperatingTemp 1;
BA_ "SPN" SG_ 2566562302 RecommendedMinOperatingTemp 17395;
BA_ "SigType" SG_ 2566562302 RecommendedMaxOperatingTemp 1;
BA_ "SPN" SG_ 2566562302 RecommendedMaxOperatingTemp 17394;
BA_ "SigType" SG_ 2566562302 RecommendedMaxStOfCharge 1;
BA_ "SPN" SG_ 2566562302 RecommendedMaxStOfCharge 17393;
BA_ "SigType" SG_ 2566562302 RecommendedMinStOfCharge 1;
BA_ "SPN" SG_ 2566562302 RecommendedMinStOfCharge 17392;
BA_ "SigType" SG_ 2566562302 RecommendedMaxOperatingV 1;
BA_ "SPN" SG_ 2566562302 RecommendedMaxOperatingV 17391;
BA_ "SigType" SG_ 2566562302 RecommendedMinOperatingV 1;
BA_ "SPN" SG_ 2566562302 RecommendedMinOperatingV 17390;
BA_ "SigType" SG_ 2566562302 NomV 1;
BA_ "SPN" SG_ 2566562302 NomV 17389;
BA_ "SigType" SG_ 2633670910 TotalEnergyOut 1;
BA_ "SPN" SG_ 2633670910 TotalEnergyOut 17388;
BA_ "SigType" SG_ 2633670910 TotalEnergyInput 1;
BA_ "SPN" SG_ 2633670910 TotalEnergyInput 17387;
BA_ "SigType" SG_ 2633670910 TotalAccumulatedCharge 1;
BA_ "SPN" SG_ 2633670910 TotalAccumulatedCharge 17386;
BA_ "SigType" SG_ 2633670910 TotalEnergyThroughput 1;
BA_ "SPN" SG_ 2633670910 TotalEnergyThroughput 17385;
BA_ "SigType" SG_ 2633670910 ContactorOpenUnderLoadCount 1;
BA_ "SPN" SG_ 2633670910 ContactorOpenUnderLoadCount 17384;
BA_ "SigType" SG_ 2633670910 StOfHealth 1;
BA_ "SPN" SG_ 2633670910 StOfHealth 17383;
BA_ "SPN" SG_ 2566561790 NomRatedCapacity 17256;
BA_ "SigType" SG_ 2566561790 CellMinVLmt 1;
BA_ "SPN" SG_ 2566561790 CellMinVLmt 17255;
BA_ "SigType" SG_ 2566561790 CellMaxVLmt 1;
BA_ "SPN" SG_ 2566561790 CellMaxVLmt 17254;
BA_ "SigType" SG_ 2566561790 RecommendedMinOperatingTemp 1;
BA_ "SPN" SG_ 2566561790 RecommendedMinOperatingTemp 17253;
BA_ "SigType" SG_ 2566561790 RecommendedMaxOperatingTemp 1;
BA_ "SPN" SG_ 2566561790 RecommendedMaxOperatingTemp 17252;
BA_ "SigType" SG_ 2566561790 RecommendedMaxStOfCharge 1;
BA_ "SPN" SG_ 2566561790 RecommendedMaxStOfCharge 17251;
BA_ "SigType" SG_ 2566561790 RecommendedMinStOfCharge 1;
BA_ "SPN" SG_ 2566561790 RecommendedMinStOfCharge 17250;
BA_ "SigType" SG_ 2566561790 RecommendedMaxOperatingV 1;
BA_ "SPN" SG_ 2566561790 RecommendedMaxOperatingV 17249;
BA_ "SigType" SG_ 2566561790 RecommendedMinOperatingV 1;
BA_ "SPN" SG_ 2566561790 RecommendedMinOperatingV 17248;
BA_ "SigType" SG_ 2566561790 NomV 1;
BA_ "SPN" SG_ 2566561790 NomV 17247;
BA_ "SigType" SG_ 2633670398 TotalEnergyOut 1;
BA_ "SPN" SG_ 2633670398 TotalEnergyOut 17246;
BA_ "SigType" SG_ 2633670398 TotalEnergyInput 1;
BA_ "SPN" SG_ 2633670398 TotalEnergyInput 17245;
BA_ "SigType" SG_ 2633670398 TotalAccumulatedCharge 1;
BA_ "SPN" SG_ 2633670398 TotalAccumulatedCharge 17244;
BA_ "SigType" SG_ 2633670398 TotalEnergyThroughput 1;
BA_ "SPN" SG_ 2633670398 TotalEnergyThroughput 17243;
BA_ "SigType" SG_ 2633670398 ContactorOpenUnderLoadCount 1;
BA_ "SPN" SG_ 2633670398 ContactorOpenUnderLoadCount 17242;
BA_ "SigType" SG_ 2633670398 StOfHealth 1;
BA_ "SPN" SG_ 2633670398 StOfHealth 17241;
BA_ "SPN" SG_ 2566561278 NomRatedCapacity 17114;
BA_ "SigType" SG_ 2566561278 CellMinVLmt 1;
BA_ "SPN" SG_ 2566561278 CellMinVLmt 17113;
BA_ "SigType" SG_ 2566561278 CellMaxVLmt 1;
BA_ "SPN" SG_ 2566561278 CellMaxVLmt 17112;
BA_ "SigType" SG_ 2566561278 RecommendedMinOperatingTemp 1;
BA_ "SPN" SG_ 2566561278 RecommendedMinOperatingTemp 17111;
BA_ "SigType" SG_ 2566561278 RecommendedMaxOperatingTemp 1;
BA_ "SPN" SG_ 2566561278 RecommendedMaxOperatingTemp 17110;
BA_ "SigType" SG_ 2566561278 RecommendedMaxStOfCharge 1;
BA_ "SPN" SG_ 2566561278 RecommendedMaxStOfCharge 17109;
BA_ "SigType" SG_ 2566561278 RecommendedMinStOfCharge 1;
BA_ "SPN" SG_ 2566561278 RecommendedMinStOfCharge 17108;
BA_ "SigType" SG_ 2566561278 RecommendedMaxOperatingV 1;
BA_ "SPN" SG_ 2566561278 RecommendedMaxOperatingV 17107;
BA_ "SigType" SG_ 2566561278 RecommendedMinOperatingV 1;
BA_ "SPN" SG_ 2566561278 RecommendedMinOperatingV 17106;
BA_ "SigType" SG_ 2566561278 NomV 1;
BA_ "SPN" SG_ 2566561278 NomV 17105;
VAL_ 2364754942 SecRealPwrOffsetRampRateSource 3 "None" 2 "Error" 1 "Secondary Regulation" 0 "Integral Local Frequency Regulation" ;
VAL_ 2364754942 SecRealPwrActiveSpOffsetSource 3 "None" 2 "Error" 1 "Secondary Regulation" 0 "Integral Local Frequency Regulation" ;
VAL_ 2364754942 AndReactivePwrReversionSt 3 "Not available" 2 "Error" 1 "Active" 0 "Inactive" ;
VAL_ 2364754942 ReversionSt 3 "Not available" 2 "Error" 1 "Active" 0 "Inactive" ;
VAL_ 2364754942 IntgLocalFreqCtrlResetSt 3 "Not Available" 2 "Error" 1 "Reset requested" 0 "Reset not requested" ;
VAL_ 2364754942 IntgLocalFreqCtrlOrSecFreqCtrlSt 3 "Not available" 2 "Error" 1 "Enabled" 0 "Disabled" ;
VAL_ 2364754942 IntgLocalFreqCtrlSt 3 "Not available" 2 "Error" 1 "Active" 0 "Inactive" ;
VAL_ 2364754942 SecFreqCtrlSt 3 "Not available" 2 "Error" 1 "Active" 0 "Inactive" ;
VAL_ 2364754686 UtilOpRealPwrEnableSt 3 "Not available" 2 "Error" 1 "Enabled" 0 "Disabled" ;
VAL_ 2364754686 ThirdPartyOpRealPwrEnableSt 3 "Not available" 2 "Error" 1 "Enabled" 0 "Disabled" ;
VAL_ 2364754686 UtilOpRealPwrSt 3 "Not available" 2 "Error" 1 "Actively Controlling" 0 "Not Actively Controlling" ;
VAL_ 2364754686 ThirdPartyOpRealPwrSt 3 "Not available" 2 "Error" 1 "Actively Controlling" 0 "Not Actively Controlling" ;
VAL_ 2498819326 GenReactivePwrOverExcitLmtSt 3 "Not available" 2 "Error" 1 "Active" 0 "Inactive" ;
VAL_ 2498819326 GenReactivePwrUnderExcitLmtSt 3 "Not available" 2 "Error" 1 "Active" 0 "Inactive" ;
VAL_ 2498819326 GenFaultRideThroughSt 15 "Not Available" 14 "Error" 3 "Low Voltage Ride Through detected" 2 "High Voltage Ride Through detected" 1 "Fault Ride Through detected" 0 "No Fault Ride Through detected" ;
VAL_ 2498819326 GenUtilDecouplingProtTestFuncSt 3 "Not available" 2 "Error" 1 "Active" 0 "Inactive" ;
VAL_ 2498819326 GenUvAndOvProtTestFuncSt 3 "Not available" 2 "Error" 1 "Active" 0 "Inactive" ;
VAL_ 2498819326 TestFuncForTheProtSt 3 "Not available" 2 "Error" 1 "Active" 0 "Inactive" ;
VAL_ 2498819326 SimulatedMainsFreqSt 3 "Not available" 2 "Error" 1 "Active" 0 "Inactive" ;
VAL_ 2565918718 FourOpSt 15 "Not Available" 14 "Error" 5 "Uncontrolled Shutdown Active" 4 "Controlled Shutdown Active" 3 "Derate Active" 2 "Alarm High Severity" 1 "Alarm" 0 "Normal" ;
VAL_ 2565918718 ThreeOpSt 15 "Not Available" 14 "Error" 5 "Uncontrolled Shutdown Active" 4 "Controlled Shutdown Active" 3 "Derate Active" 2 "Alarm High Severity" 1 "Alarm" 0 "Normal" ;
VAL_ 2555117310 HybMultiConnReqEnergyXferType 15 "Reserved" 14 "Reserved" 13 "Reserved" 12 "Reserved" 11 "Reserved" 10 "Reserved" 9 "Reserved" 8 "Reserved" 7 "Reserved" 6 "Reserved" 5 "Reserved" 4 "Reserved" 3 "Reserved" 2 "Reserved" 1 "DC-Core" 0 "DC-Extended" ;
VAL_ 2555051774 ErrorCode 15 "Not available" 14 "No Data" 13 "Charging system not compatible" 12 "Reserved" 11 "Reserved" 10 "Reserved" 9 "Reserved" 8 "Reserved" 7 "Reserved" 6 "Charging Voltage Out of Range" 5 "Charging Current differential" 4 "Vehicle charging system fault" 3 "Connector Lock fault" 2 "Shift Position " 1 "Battery Temperature too hot/cold" 0 "No Error" ;
VAL_ 2555051774 RESSConditioningFlag 3 "Not available" 2 "Reserved" 1 "Battery conditioning active" 0 "Battery conditioning not active" ;
VAL_ 2555051774 CabinConditioningFlag 3 "Not available" 2 "Reserved" 1 "Cabin conditioning active" 0 "Cabin conditioning not active" ;
VAL_ 2352611070 InMessageIntegrityDataSupported 3 "No External ACC Acceleration Request protection supported by the sender" 2 "Reserved" 1 "External ACC Acceleration Request protection is supported using J1939-76 SHM" 0 "External ACC Acceleration Request CRC and Counter is support by the sender" ;
VAL_ 2352611070 CtrlMode 3 "Not Available" 2 "Error" 1 "External ACC Acceleration Request" 0 "No External ACC Acceleration Request" ;
VAL_ 2566687486 EnableSt 3 "Not available" 2 "Motor On, Reverse Direction" 1 "Motor On, Normal" 0 "Motor Off" ;
VAL_ 2566687230 EnableSt 3 "Not available" 2 "Motor On, Reverse Direction" 1 "Motor On, Normal" 0 "Motor Off" ;
VAL_ 2566686974 EnableCmd 3 "Don't Care/Take no action" 2 "Motor On Reverse Direction" 1 "Motor On Normal/Default Direction" 0 "Motor Off" ;
VAL_ 2566686718 EnableCmd 3 "Don't Care/Take no action" 2 "Motor On Reverse Direction" 1 "Motor On Normal/Default Direction" 0 "Motor Off" ;
VAL_ 2566686462 Mode 15 "Not available" 14 "Error" 13 "Reserved" 12 "Reserved" 11 "Reserved" 10 "Reserved" 9 "Reserved" 8 "Reserved" 7 "Heater Locked" 6 "Diagnose Active" 5 "Heater Stopping" 4 "Heater Starting" 3 "Heater pump up-keep  " 2 "Normal mode" 1 "Economy mode" 0 "Heater not active" ;
VAL_ 2566686206 ModeReq 15 "Don't care/take no action" 14 "Reserved" 13 "Reserved" 12 "Reserved" 11 "Reserved" 10 "Reserved" 9 "Reserved" 8 "Reserved" 7 "Reserved" 6 "Reserved" 5 "Reserved" 4 "Reserved" 3 "Heater pump up-keep" 2 "Normal mode" 1 "Economy mode" 0 "De-activate fuel cell auxiliary heater" ;
VAL_ 2566539774 RearParkAssistSt 7 "Not Available" 6 "Error" 5 "Reserved" 4 "Reserved" 3 "Active" 2 "Disabled/Blocked" 1 "Standby" 0 "Off" ;
VAL_ 2566539774 FrontParkAssistSt 7 "Not Available" 6 "Error" 5 "Reserved" 4 "Reserved" 3 "Active" 2 "Disabled/Blocked" 1 "Standby" 0 "Off" ;
VAL_ 2566539518 CtrlPushToTalkSw 3 "Not Available" 2 "Error" 1 "Pressed" 0 "Released" ;
VAL_ 2566539518 CtrlVoiceCommunicationSw 3 "Not Available" 2 "Error" 1 "Pressed" 0 "Released" ;
VAL_ 2566539518 CtrlCallEndSw 3 "Not Available" 2 "Error" 1 "Pressed" 0 "Released" ;
VAL_ 2566539518 CtrlVolumeDownSw 3 "Not Available" 2 "Error" 1 "Pressed" 0 "Released" ;
VAL_ 2566539518 CtrlVolumeUpSw 3 "Not Available" 2 "Error" 1 "Pressed" 0 "Released" ;
VAL_ 2566539518 CtrlPreviousSw 3 "Not Available" 2 "Error" 1 "Pressed" 0 "Released" ;
VAL_ 2566539518 CtrlNextSw 3 "Not Available" 2 "Error" 1 "Pressed" 0 "Released" ;
VAL_ 2566539262 TwoSvcModeReq 3 "Take no action" 2 "Reserved" 1 "Enable Service Mode" 0 "Disable Service Mode" ;
VAL_ 2566539262 OneSvcModeReq 3 "Take no action" 2 "Reserved" 1 "Enable Service Mode" 0 "Disable Service Mode" ;
VAL_ 2566539006 St 7 "Not Available" 6 "Error" 5 "Reserved" 4 "Reserved" 3 "Reserved" 2 "Disabled Operation" 1 "Limited Operation" 0 "Normal Operation" ;
VAL_ 2566539006 LmtReason 15 "Not Available" 14 "Error" 13 "Reserved" 12 "Reserved" 11 "Reserved" 10 "Reserved" 9 "Reserved" 8 "Reserved" 7 "Reserved" 6 "Invalid Radio" 5 "Invalid Key" 4 "Wireless Connection Loss" 3 "GPS Antenna Fault" 2 "Radio Removal" 1 "Remote Command" 0 "No Machine Operation Limit" ;
VAL_ 2566539006 DisReason 15 "Not Available" 14 "Error" 13 "Reserved" 12 "Reserved" 11 "Reserved" 10 "Reserved" 9 "Reserved" 8 "Reserved" 7 "Reserved" 6 "Invalid Radio" 5 "Invalid Key" 4 "Wireless Connection Loss" 3 "GPS Antenna Fault" 2 "Radio Removal" 1 "Remote Command" 0 "No Machine Operation Disable" ;
VAL_ 2566537726 ReceivePortOfCtrl4 15 "Not Available" 14 "Reserved" 13 "Reserved" 12 "Reserved" 11 "Reserved" 10 "Port 10" 9 "Port 9" 8 "Port 8" 7 "Port 7" 6 "Port 6" 5 "Port 5" 4 "Port 4" 3 "Port 3" 2 "Port 2" 1 "Port 1" 0 "Not Identified" ;
VAL_ 2566537726 ReceivePortOfCtrl3 15 "Not Available" 14 "Reserved" 13 "Reserved" 12 "Reserved" 11 "Reserved" 10 "Port 10" 9 "Port 9" 8 "Port 8" 7 "Port 7" 6 "Port 6" 5 "Port 5" 4 "Port 4" 3 "Port 3" 2 "Port 2" 1 "Port 1" 0 "Not Identified" ;
VAL_ 2566537726 ReceivePortOfCtrl2 15 "Not Available" 14 "Reserved" 13 "Reserved" 12 "Reserved" 11 "Reserved" 10 "Port 10" 9 "Port 9" 8 "Port 8" 7 "Port 7" 6 "Port 6" 5 "Port 5" 4 "Port 4" 3 "Port 3" 2 "Port 2" 1 "Port 1" 0 "Not Identified" ;
VAL_ 2566537726 ReceivePortOfCtrl1 15 "Not Available" 14 "Reserved" 13 "Reserved" 12 "Reserved" 11 "Reserved" 10 "Port 10" 9 "Port 9" 8 "Port 8" 7 "Port 7" 6 "Port 6" 5 "Port 5" 4 "Port 4" 3 "Port 3" 2 "Port 2" 1 "Port 1" 0 "Not Identified" ;
VAL_ 2365210878 AutoNeutralFunctionSt 15 "Not Available" 14 "Error" 13 "Reserved" 12 "Reserved" 11 "Reserved" 10 "Reserved" 9 "Reserved" 8 "Reserved" 7 "Reserved" 6 "Reserved" 5 "Function Request Achieved" 4 "Function Request Pending" 3 "Function Request Inhibited" 2 "Function Inactive,  conditions are such that an Auto-Neutral request would NOT be honored" 1 "Function Inactive,  conditions are such that an Auto-Neutral request would be honored" 0 "Function Aborted or Disabled" ;
VAL_ 2365210878 AutoNeutralReqFeedback 7 "Not Available" 6 "Error" 5 "Reserved" 4 "Reserved" 3 "Responding to: Don't Care / Take No Action" 2 "Responding to: Request to shift from Auto-Neutral state to previous direction" 1 "Responding to: Request to shift to" 0 "Responding to: No request" ;
VAL_ 2364754174 CtrlAtLowLoadSt 3 "Not available" 2 "Error / function disabled" 1 "Within limits" 0 "Not within limits" ;
VAL_ 2364754174 ModeSelectionDigitalInput4St 3 "Not available" 2 "Error" 1 "Active" 0 "Inactive" ;
VAL_ 2364754174 ModeSelectionDigitalInput3St 3 "Not available" 2 "Error" 1 "Active" 0 "Inactive" ;
VAL_ 2364754174 ModeSelectionDigitalInput2St 3 "Not available" 2 "Error" 1 "Active" 0 "Inactive" ;
VAL_ 2364754174 ModeSelectionDigitalInput1St 3 "Not available" 2 "Error" 1 "Active" 0 "Inactive" ;
VAL_ 2364754174 UtilOpReactivePwrSpSource 15 "Not available" 14 "Error" 13 "Reserved" 12 "Reserved" 11 "Reserved" 10 "Reserved" 9 "Reserved" 8 "Voltage" 7 "Voltage-Power Factor Control Curve" 6 "Real Power-Power Factor Control Curve" 5 "Real Power-Reactive Power Control Curve" 4 "Voltage-Reactive Power with Voltage Shift" 3 "Voltage-Reactive Power with Reactive Power Shift" 2 "Reactive Power" 1 "Power Factor" 0 "None" ;
VAL_ 2364754174 UtilSyncronizationSt 15 "Not available" 14 "Error" 13 "Reserved" 12 "Reserved" 11 "Reserved" 10 "Reserved" 9 "Reserved" 8 "Reserved" 7 "Reserved" 6 "Reserved" 5 "Reserved" 4 "Reserved" 3 "Remaining observation time" 2 "Voltage or frequency outside of permissible range" 1 "Waiting for external signal" 0 "Permission granted" ;
VAL_ 2364754174 ActiveLmtSource 15 "Not available" 14 "Error" 13 "Reserved" 12 "Reserved" 11 "Reserved" 10 "Reserved" 9 "Reserved" 8 "Reserved" 7 "Reserved" 6 "Reserved" 5 "Real Power-Power Factor Control Curve Limitation" 4 "Voltage-Reacitve Power with Voltage Shift Delay" 3 "Voltage-Reacitve Power with Reactive Power Shift Delay" 2 "Voltage-Reacitve Power with Voltage Shift Limitation" 1 "Voltage-Reacitve Power with Reactive Power Shift Limitation- Q(U)-Q_Shift" 0 "None" ;
VAL_ 2364754174 ActiveSpSource 15 "Not available" 14 "Error" 13 "Reserved" 12 "Reserved" 11 "Reserved" 10 "Reserved" 9 "Reserved" 8 "Voltage" 7 "Voltage-Power Factor Control Curve" 6 "Real Power-Power Factor Control Curve" 5 "Real Power-Reactive Power Control Curve" 4 "Voltage-Reacitve Power with Voltage Shift" 3 "Voltage-Reacitve Power with Reactive Power Shift" 2 "Reactive Power" 1 "Power Factor" 0 "None" ;
VAL_ 2364753918 PrimRealPwrOffsetRampRateSource 7 "Not Available" 6 "Error" 5 "Reserved" 4 "Reserved" 3 "Reserved" 2 "Frequency Sensitive Mode Decrease" 1 "Frequency Sensitive Mode Increase" 0 "None" ;
VAL_ 2364753918 PrimRealPwrActiveSpOffsetSource 7 "Not Available" 6 "Error" 5 "Reserved" 4 "Reserved" 3 "Reserved" 2 "Reserved" 1 "Frequency Sensitive Mode" 0 "None" ;
VAL_ 2364753918 RampRateSource 15 "Not Available" 14 "Error" 13 "Reserved" 12 "Reserved" 11 "Reserved" 10 "Reconnection after Utility Decoupling" 9 "Genset Normal Starting" 8 "Utility Operator Limitation" 7 "Frequency Sensitive Mode" 6 "Utility Parallel Voltage-Real Power Curve" 5 "Disconnection from Utility" 4 "Limited Frequency Sensitive Mode Stage #2" 3 "Limited Frequency Sensitive Mode Stage #1" 2 "Utility Operator Demand" 1 "Third Party Operator" 0 "Genset Operator" ;
VAL_ 2364753918 ActiveSpSource 15 "Not Available" 14 "Error" 13 "Reserved" 12 "Reserved" 11 "Reserved" 10 "Reserved" 9 "Reserved" 8 "Reserved" 7 "Utility Parallel Voltage-Real Power Curve" 6 "Utility Operator Limitation" 5 "Limited Frequency Sensitive Mode Underfrequency" 4 "Limited Frequency Sensitive Mode Overfrequency" 3 "Utility Operator" 2 "Third Party Vendor" 1 "Service Tool" 0 "Genset Operator" ;
VAL_ 2364753662 RealPwrRampRateLmtSt 3 "Not available" 2 "Error" 1 "Actively Limiting" 0 "Not Actively Limiting" ;
VAL_ 2364753662 RealPwrRampRateLmtEnableSt 3 "Not available" 2 "Error" 1 "Enabled" 0 "Disabled" ;
VAL_ 2364753662 UtilOpRealPwrExportLmtSp4St 3 "Not available" 2 "Error" 1 "Actively Limiting" 0 "Not Actively Limiting" ;
VAL_ 2364753662 UtilOpRealPwrExportLmtSp3St 3 "Not available" 2 "Error" 1 "Actively Limiting" 0 "Not Actively Limiting" ;
VAL_ 2364753662 UtilOpRealPwrExportLmtSp2St 3 "Not available" 2 "Error" 1 "Actively Limiting" 0 "Not Actively Limiting" ;
VAL_ 2364753662 UtilOpRealPwrExportLmtSp1St 3 "Not available" 2 "Error" 1 "Actively Limiting" 0 "Not Actively Limiting" ;
VAL_ 2364753662 UtilParVRealPwrCurveSt 3 "Not available" 2 "Error" 1 "Active" 0 "Inactive" ;
VAL_ 2364753662 UtilOpRealPwrExportLmtSt 3 "Not available" 2 "Error" 1 "Active" 0 "Inactive" ;
VAL_ 2364753406 SensModeEnableSt 3 "Not Available" 2 "Error" 1 "Enabled" 0 "Disabled" ;
VAL_ 2364753406 LimFSMOfEnableStDeactThldResetSt 3 "Not Available" 2 "Error" 1 "Reset requested" 0 "Reset not requested" ;
VAL_ 2364753406 LimFSMUfSt 3 "Not Available" 2 "Error" 1 "Enabled" 0 "Disabled" ;
VAL_ 2364753406 LimFSMOfEnableSt 3 "Not Available" 2 "Error" 1 "Enabled" 0 "Disabled" ;
VAL_ 2364753406 SensitiveModeSt 3 "Not available" 2 "Error" 1 "Active" 0 "Inactive" ;
VAL_ 2364753406 LimFreqSensitiveModeSt 3 "Not available" 2 "Error" 1 "Active" 0 "Inactive" ;
VAL_ 2566079742 ActiveExtlInhAntiRollAway 3 "Not Available" 2 "Error" 1 "External EPB Inhibit Anti-Roll-Away being executed" 0 "No external inhibit Anti-Roll-Away being executed" ;
VAL_ 2566079742 AntiRollAwayReqSysStInh 3 "Not Available" 2 "Error" 1 "External EPB Inhibit Anti-Roll-Away will be accepted" 0 "External EPB Inhibit Anti-Roll-Away will not be accepted" ;
VAL_ 2566079742 TransNeutralReqSt 3 "Not Available" 2 "Error" 1 "Transmission Neutral Request in Active state" 0 "Transmission Neutral Request in Passive state" ;
VAL_ 2566079742 ParkAtSpdExtlBrkReqSt 3 "Not Available" 2 "Error" 1 "EPB is executing external Park-at-Speed service brake request" 0 "EPB is not executing external Park-at-Speed service brake request" ;
VAL_ 2566079742 ActiveExtlCtrlModeTowedUnit 15 "Not Available" 14 "Error" 13 "Reserved" 12 "Reserved" 11 "Reserved" 10 "Reserved" 9 "Reserved" 8 "Reserved" 7 "Reserved" 6 "Reserved" 5 "Reserved" 4 "Reserved" 3 "Reserved" 2 "External EPB Power Unit release demand being executed" 1 "External EPB Power Unit apply demand being executed" 0 "No external Power Unit apply or release demand being executed" ;
VAL_ 2566079742 ActiveExtlCtrlModePwrUnit 15 "Not Available" 14 "Error" 13 "Reserved" 12 "Reserved" 11 "Reserved" 10 "Reserved" 9 "Reserved" 8 "Reserved" 7 "Reserved" 6 "Reserved" 5 "Reserved" 4 "Reserved" 3 "Reserved" 2 "External EPB Power Unit release demand being executed" 1 "External EPB Power Unit apply demand being executed" 0 "No external Power Unit apply or release demand being executed" ;
VAL_ 2566079742 ExtlReqSysStTowedUnitEvacuate 3 "Not Available" 2 "Reserved" 1 "External EPB Towed Unit Evacuate will be accepted" 0 "External EPB Towed Unit Evacuate will not be accepted" ;
VAL_ 2566079742 ExtlReqSysStTowedUnitSupply 3 "Not Available" 2 "Reserved" 1 "External EPB Towed Unit Supply will be accepted" 0 "External EPB Towed Unit Supply will not be accepted" ;
VAL_ 2566079742 ExtlReqSysStPwrUnitRelease 3 "Not Available" 2 "Reserved" 1 "External EPB Power Unit Release will be accepted" 0 "External EPB Power Unit Release will not be accepted" ;
VAL_ 2566079742 ExtlReqSysStPwrUnitApply 3 "Not Available" 2 "Reserved" 1 "External EPB Power Unit Apply will be accepted" 0 "External EPB Power Unit Apply will not be accepted" ;
VAL_ 2566079486 TowedUnitSwSt 7 "Not Available" 6 "Error" 5 "Reserved" 4 "Release Park Brake Position, Driver Request Honored" 3 "Release Park Brake Position, Driver Request Not Honored" 2 "Apply Park Brake Position, Driver Request Honored" 1 "Apply Park Brake Position, Driver Request Not Honored" 0 "Neutral Position" ;
VAL_ 2566079486 PwrUnitSwSt 7 "Not Available" 6 "Error" 5 "Reserved" 4 "Release Park Brake Position, Driver Request Honored" 3 "Release Park Brake Position, Driver Request Not Honored" 2 "Apply Park Brake Position, Driver Request Honored" 1 "Apply Park Brake Position, Driver Request Not Honored" 0 "Neutral Position" ;
VAL_ 2566079486 PwrSt 7 "Not Available" 6 "Error" 5 "Reserved" 4 "Reserved" 3 "Reserved" 2 "Reserved" 1 "Entering Sleep Mode" 0 "Normal" ;
VAL_ 2566079486 ExhAtSpdSt 7 "Not Available" 6 "Error" 5 "Reserved" 4 "Reserved" 3 "Reserved" 2 "Reserved" 1 "Exhaust-at-Speed active" 0 "Exhaust-at-Speed passive" ;
VAL_ 2566079486 TlrOvrdIlkDoor2St 3 "Not Available" 2 "Error" 1 "EPB will override door 2 switch interlock for trailer unparking" 0 "EPB will not override door 2 switch interlock for trailer unparking" ;
VAL_ 2566079486 TlrOvrdIlkDoor1St 3 "Not Available" 2 "Error" 1 "EPB will override door 1 switch interlock for trailer unparking" 0 "EPB will not override door 1 switch interlock for trailer unparking" ;
VAL_ 2566079486 TlrOvrdIlkSeatBeltSwSt 3 "Not Available" 2 "Error" 1 "EPB will override seat belt switch interlock for trailer unparking" 0 "EPB will not override seat belt switch interlock for trailer unparking" ;
VAL_ 2566079486 TlrOvrdIlkIgntSt 3 "Not Available" 2 "Error" 1 "EPB will override ignition switch interlock for trailer unparking" 0 "EPB will not override ignition switch interlock for trailer unparking" ;
VAL_ 2566079486 TlrOvrdIlkSvcBrkSt 3 "Not Available" 2 "Error" 1 "EPB will override service brake switch interlock for trailer unparking" 0 "EPB will not override service brake switch interlock for trailer unparking" ;
VAL_ 2566079486 OperatingMode 15 "Not Available" 14 "Error" 13 "Reserved" 12 "Reserved" 11 "Reserved" 10 "Reserved" 9 "Reserved" 8 "Reserved" 7 "Reserved" 6 "Reserved" 5 "Programming Mode" 4 "Parking Brake Release Interlock Override Mode" 3 "Maintenance Mode" 2 "Retrofit Installation Mode" 1 "OEM Assembly Mode" 0 "Normal Mode" ;
VAL_ 2566079486 PwrUnitVehType 3 "Error" 2 "Non-Towing bus" 1 "Non-Towing Straight Truck" 0 "Towing" ;
VAL_ 2566079486 TlrBrkReleaseSt 3 "Not Available" 2 "Error" 1 "Active" 0 "Passive" ;
VAL_ 2566079486 OccupancyAntiRollAwaySt 3 "Not Available" 2 "Error" 1 "Occupancy Anti-Roll-Away Active" 0 "Occupancy Anti-Roll-Away Passive" ;
VAL_ 2566079486 TowedUnitCtrlAirSt 7 "Not Available" 6 "Error" 5 "Reserved" 4 "No Trailer Attached" 3 "Charged" 2 "Building Pressure" 1 "Exhausting Pressure" 0 "Exhausted" ;
VAL_ 2566079486 PwrUnitCtrlAirSt 7 "Not Available" 6 "Error" 5 "Reserved" 4 "Reserved" 3 "Charged" 2 "Building Pressure" 1 "Exhausting Pressure" 0 "Exhausted" ;
VAL_ 2555248382 ConAbortReason 255 "Not available" 254 "Error indicator" 250 "Connection Abort reason is not listed" 9 "Total Message Size is greater than 1785 bytes" 8 "Duplicate sequence number (software cannot recover)" 7 "Bad sequence number (software cannot recover)" 6 "Unexpected data transfer packet" 5 "Maximum retransmit request limit reached" 4 "CTS messages received when data transfer is in progress." 3 "A timeout occurred and this is the connection abort to close the session." 2 "System resources were needed for another task so this connection managed session was terminated." 1 "Already in one or more connection managed sessions and cannot support another." ;
VAL_ 2555248382 ControlByte 15 "Abort" 4 "BAM" 3 "EOMA" 2 "EOMS" 1 "CTS" 0 "RTS" ;
VAL_ 2566658814 CompressorEnableCmd 3 "Don't Care/Take no action" 2 "Reserved" 1 "Compressor On" 0 "Compressor Off" ;
VAL_ 2566658814 CPEnableCmd 3 "Don't Care/Take no action" 2 "Motor On Reverse Direction" 1 "Motor On Normal/Default Direction" 0 "Motor Off" ;
VAL_ 2566658814 HtrEnableCmd 3 "Don't Care/Take no action" 2 "Reserved" 1 "Enable Heater" 0 "Disable Heater" ;
VAL_ 2566563326 StReason 255 "Not Available" 254 "Error" 253 "Reserved" 252 "Reserved" 251 "Reserved" 250 "Reserved" 249 "Reserved" 248 "Reserved" 247 "Reserved" 246 "Reserved" 245 "Reserved" 244 "Reserved" 243 "Reserved" 242 "Reserved" 241 "Reserved" 240 "Reserved" 239 "Reserved" 238 "Reserved" 237 "Reserved" 236 "Reserved" 235 "Reserved" 234 "Reserved" 233 "Reserved" 232 "Reserved" 231 "Reserved" 230 "Reserved" 229 "Reserved" 228 "Reserved" 227 "Reserved" 226 "Reserved" 225 "Reserved" 224 "Reserved" 223 "Reserved" 222 "Reserved" 221 "Reserved" 220 "Reserved" 219 "Reserved" 218 "Reserved" 217 "Reserved" 216 "Reserved" 215 "Reserved" 214 "Reserved" 138 "Reserved" 137 "Reserved" 136 "Reserved" 135 "Reserved" 134 "Reserved" 133 "Reserved" 132 "Reserved" 131 "Reserved" 130 "Reserved" 129 "Reserved" 128 "Reserved" 127 "Reserved" 126 "Reserved" 125 "Reserved" 124 "Reserved" 123 "Reserved" 122 "Reserved" 121 "Reserved" 120 "Reserved" 119 "Reserved" 118 "Reserved" 117 "Reserved" 116 "Reserved" 115 "Reserved" 114 "Reserved" 113 "Reserved" 112 "Reserved" 111 "Reserved" 110 "Reserved" 109 "Reserved" 108 "Reserved" 107 "Reserved" 106 "Reserved" 105 "Reserved" 104 "Reserved" 103 "Reserved" 102 "Reserved" 101 "Reserved" 100 "Reserved" 99 "Reserved" 98 "Reserved" 97 "Reserved" 96 "Reserved" 95 "Reserved" 94 "Reserved" 93 "Reserved" 92 "Reserved" 91 "Reserved" 90 "Reserved" 89 "Reserved" 88 "Reserved" 87 "Reserved" 86 "Reserved" 85 "Reserved" 84 "Reserved" 83 "Reserved" 82 "Reserved" 81 "Reserved" 80 "Reserved" 79 "Reserved" 78 "Reserved" 77 "Reserved" 76 "Reserved" 75 "Reserved" 74 "Reserved" 73 "Reserved" 72 "Reserved" 71 "Reserved" 70 "Reserved" 69 "Reserved" 68 "Reserved" 67 "Reserved" 66 "Reserved" 65 "Reserved" 64 "Reserved" 213 "Reserved" 212 "Reserved" 211 "Reserved" 210 "Reserved" 209 "Reserved" 208 "Reserved" 207 "Reserved" 206 "Reserved" 205 "Reserved" 204 "Reserved" 203 "Reserved" 202 "Reserved" 201 "Reserved" 200 "Reserved" 199 "Reserved" 198 "Reserved" 197 "Reserved" 196 "Reserved" 195 "Reserved" 194 "Reserved" 193 "Reserved" 192 "Reserved" 191 "Reserved" 190 "Reserved" 189 "Reserved" 188 "Reserved" 187 "Reserved" 186 "Reserved" 185 "Reserved" 184 "Reserved" 183 "Reserved" 182 "Reserved" 181 "Reserved" 180 "Reserved" 179 "Reserved" 178 "Reserved" 177 "Reserved" 176 "Reserved" 175 "Reserved" 174 "Reserved" 173 "Reserved" 172 "Reserved" 171 "Reserved" 170 "Reserved" 169 "Reserved" 168 "Reserved" 167 "Reserved" 166 "Reserved" 165 "Reserved" 164 "Reserved" 163 "Reserved" 162 "Reserved" 161 "Reserved" 160 "Reserved" 159 "Reserved" 158 "Reserved" 157 "Reserved" 156 "Reserved" 155 "Reserved" 154 "Reserved" 153 "Reserved" 152 "Reserved" 151 "Reserved" 150 "Reserved" 149 "Reserved" 148 "Reserved" 147 "Reserved" 146 "Reserved" 145 "Reserved" 144 "Reserved" 143 "Reserved" 142 "Reserved" 141 "Reserved" 140 "Reserved" 139 "Reserved" 63 "Reserved" 62 "Reserved" 61 "Reserved" 60 "Reserved" 59 "Reserved" 58 "Reserved" 57 "Reserved" 56 "Reserved" 55 "Reserved" 54 "Reserved" 53 "Reserved" 52 "Reserved" 51 "Reserved" 50 "Reserved" 49 "Reserved" 48 "Reserved" 47 "Reserved" 46 "Reserved" 45 "Reserved" 44 "Reserved" 43 "Reserved" 42 "Reserved" 41 "Reserved" 40 "Reserved" 39 "Reserved" 38 "Reserved" 37 "Reserved" 36 "Reserved" 35 "Reserved" 34 "Reserved" 33 "Reserved" 32 "Reserved" 31 "Reserved" 30 "Reserved" 29 "Reserved" 28 "Reserved" 27 "Reserved" 26 "Reserved" 25 "Gas Blending Normal Above Target" 24 "Gas Blending Normal Below Target" 23 "Gas Blending At Target" 22 "Engine Under Acceleration" 21 "Engine Operating Time Too Low" 20 "Gas System Leak Check In Progress" 19 "Aftertreatment Warm Up In Progress" 18 "Gas Blending System Abnormal" 17 "Gaseous Fuel Energy Content Too High" 16 "Engine System Protection Active" 15 "Aftertreatment Temperature Threshold Not Met" 14 "Engine Cylinder Cut-Out Mode Active" 13 "Gas System Temperature Too High" 12 "Gas System Temperature Too Low" 11 "Gas System Pressure Too High" 10 "Gas System Pressure Too Low" 9 "Intake Manifold Air Temperature Too High" 8 "Intake Manifold Air Temperature Too Low" 7 "Coolant Temperature Too High" 6 "Coolant Temperature Too Low" 5 "Engine Load Too High" 4 "Engine Load Too Low" 3 "Engine Speed Too High" 2 "Engine Speed Too Low" 1 "Diagnostic Trouble Code Active" 0 "Not Requested" ;
VAL_ 2566563326 OperatingSt 15 "Not Available" 14 "Error" 13 "Reserved" 12 "Reserved" 11 "Reserved" 10 "Reserved" 9 "Reserved" 8 "Reserved" 7 "Reserved" 6 "Reserved" 5 "Active" 4 "Pending" 3 "Temporarily Disabled Due to Current Conditions" 2 "Automatically Disabled and Locked" 1 "Operator Disabled" 0 "Disabled by Configuration" ;
VAL_ 2566563070 EmbeddedIntegritySupport 3 "ADSC2 CRC and Counter are not supported by the sender" 2 "Reserved" 1 "ADSC2 protection is supported using J1939-76 SHM" 0 "ADSC2 embedded CRC and Counter are supported by the sender" ;
VAL_ 2566563070 VSCtrlCmdPriority 7 "Not Supported" 6 "Lowest priority" 5 "Sixth highest priority" 4 "Fifth highest priority" 3 "Fourth highest priority" 2 "Third highest priority" 1 "Second highest priority" 0 "Highest priority" ;

SG_MUL_VAL_ 2555248382 TotalNoOfSegments ControlByte 0-0, 2-2, 3-3, 4-4;
SG_MUL_VAL_ 2555248382 TotalMsgSize ControlByte 0-0, 2-2, 3-3, 4-4;
SG_MUL_VAL_ 2555248382 AssuranceDataType ControlByte 0-0, 2-2, 4-4;
